VERSION ""

NS_ :

BS_:

BU_: SOBDMB_AWDC BCMC_CPDB BECMB_EPM PACM GWM _delete BCM ACCM DCDC_HEV GENERIC TSTR

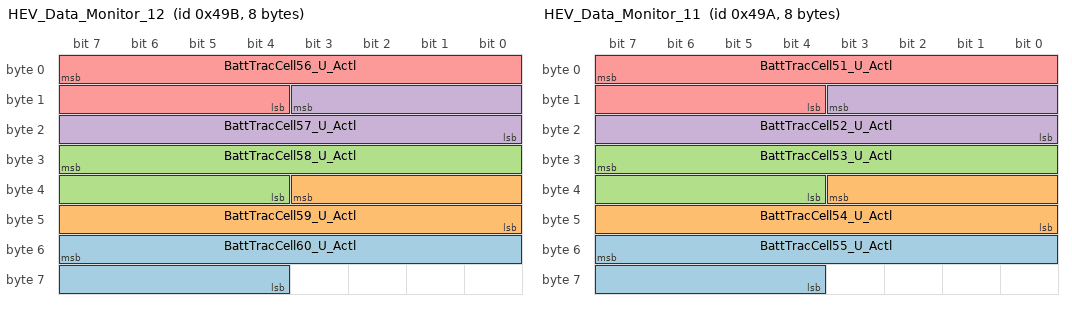
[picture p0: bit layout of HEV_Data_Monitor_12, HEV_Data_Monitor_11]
BO_ 1179 HEV_Data_Monitor_12: 8 GWM
 SG_ BattTracCell60_U_Actl : 55|12@0+ (0.001,1) [1|5.093] "volt" Vector__XXX
 SG_ BattTracCell59_U_Actl : 35|12@0+ (0.001,1) [1|5.093] "volt" Vector__XXX
 SG_ BattTracCell58_U_Actl : 31|12@0+ (0.001,1) [1|5.093] "volt" Vector__XXX
 SG_ BattTracCell57_U_Actl : 11|12@0+ (0.001,1) [1|5.093] "volt" Vector__XXX
 SG_ BattTracCell56_U_Actl : 7|12@0+ (0.001,1) [1|5.093] "volt" Vector__XXX

BO_ 1178 HEV_Data_Monitor_11: 8 GWM
 SG_ BattTracCell55_U_Actl : 55|12@0+ (0.001,1) [1|5.093] "volt" Vector__XXX
 SG_ BattTracCell54_U_Actl : 35|12@0+ (0.001,1) [1|5.093] "volt" Vector__XXX
 SG_ BattTracCell53_U_Actl : 31|12@0+ (0.001,1) [1|5.093] "volt" Vector__XXX
 SG_ BattTracCell52_U_Actl : 11|12@0+ (0.001,1) [1|5.093] "volt" Vector__XXX
 SG_ BattTracCell51_U_Actl : 7|12@0+ (0.001,1) [1|5.093] "volt" Vector__XXX

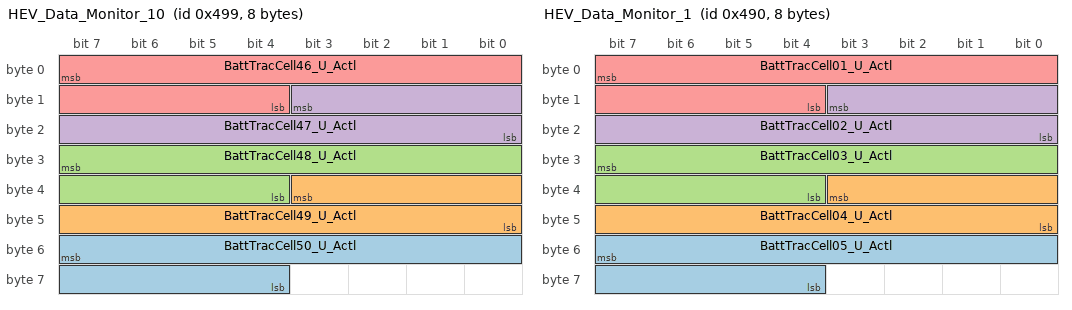
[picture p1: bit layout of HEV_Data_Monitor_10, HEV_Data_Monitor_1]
BO_ 1177 HEV_Data_Monitor_10: 8 GWM
 SG_ BattTracCell50_U_Actl : 55|12@0+ (0.001,1) [1|5.093] "volt" Vector__XXX
 SG_ BattTracCell49_U_Actl : 35|12@0+ (0.001,1) [1|5.093] "volt" Vector__XXX
 SG_ BattTracCell48_U_Actl : 31|12@0+ (0.001,1) [1|5.093] "volt" Vector__XXX
 SG_ BattTracCell47_U_Actl : 11|12@0+ (0.001,1) [1|5.093] "volt" Vector__XXX
 SG_ BattTracCell46_U_Actl : 7|12@0+ (0.001,1) [1|5.093] "volt" Vector__XXX

BO_ 1168 HEV_Data_Monitor_1: 8 GWM
 SG_ BattTracCell05_U_Actl : 55|12@0+ (0.001,1) [1|5.093] "volt" Vector__XXX
 SG_ BattTracCell04_U_Actl : 35|12@0+ (0.001,1) [1|5.093] "volt" Vector__XXX
 SG_ BattTracCell03_U_Actl : 31|12@0+ (0.001,1) [1|5.093] "volt" Vector__XXX
 SG_ BattTracCell02_U_Actl : 11|12@0+ (0.001,1) [1|5.093] "volt" Vector__XXX
 SG_ BattTracCell01_U_Actl : 7|12@0+ (0.001,1) [1|5.093] "volt" Vector__XXX

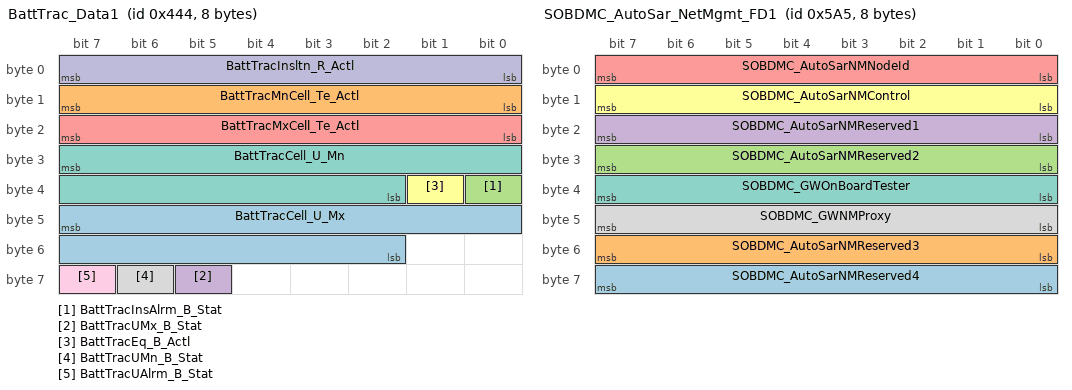
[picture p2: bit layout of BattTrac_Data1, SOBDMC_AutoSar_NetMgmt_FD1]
BO_ 1092 BattTrac_Data1: 8 GWM
 SG_ BattTracCell_U_Mx : 47|14@0+ (0.001,0) [0|16.382] "volt" Vector__XXX
 SG_ BattTracMnCell_Te_Actl : 15|8@0+ (1,-40) [-40|213] "degC" Vector__XXX
 SG_ BattTracInsAlrm_B_Stat : 32|1@0+ (1,0) [0|1] "SED" Vector__XXX
 SG_ BattTracUMx_B_Stat : 61|1@0+ (1,0) [0|1] "SED" Vector__XXX
 SG_ BattTracMxCell_Te_Actl : 23|8@0+ (1,-40) [-40|213] "degC" Vector__XXX
 SG_ BattTracEq_B_Actl : 33|1@0+ (1,0) [0|1] "SED" Vector__XXX
 SG_ BattTracCell_U_Mn : 31|14@0+ (0.001,0) [0|16.382] "volt" Vector__XXX
 SG_ BattTracUMn_B_Stat : 62|1@0+ (1,0) [0|1] "SED" Vector__XXX
 SG_ BattTracUAlrm_B_Stat : 63|1@0+ (1,0) [0|1] "SED" Vector__XXX
 SG_ BattTracInsltn_R_Actl : 7|8@0+ (6000,0) [0|1524000] "ohm" Vector__XXX

BO_ 1445 SOBDMC_AutoSar_NetMgmt_FD1: 8 GWM
 SG_ SOBDMC_AutoSarNMReserved4 : 63|8@0+ (1,0) [0|255] "unitless"  BCM
 SG_ SOBDMC_AutoSarNMReserved3 : 55|8@0+ (1,0) [0|255] "unitless"  BCM
 SG_ SOBDMC_AutoSarNMReserved2 : 31|8@0+ (1,0) [0|255] "unitless"  BCM
 SG_ SOBDMC_AutoSarNMReserved1 : 23|8@0+ (1,0) [0|255] "unitless"  BCM
 SG_ SOBDMC_AutoSarNMNodeId : 7|8@0+ (1,0) [0|255] "unitless"  BCM
 SG_ SOBDMC_AutoSarNMControl : 15|8@0+ (1,0) [0|255] "unitless"  BCM
 SG_ SOBDMC_GWOnBoardTester : 39|8@0+ (1,0) [0|255] "unitless"  BCM
 SG_ SOBDMC_GWNMProxy : 47|8@0+ (1,0) [0|255] "unitless"  BCM

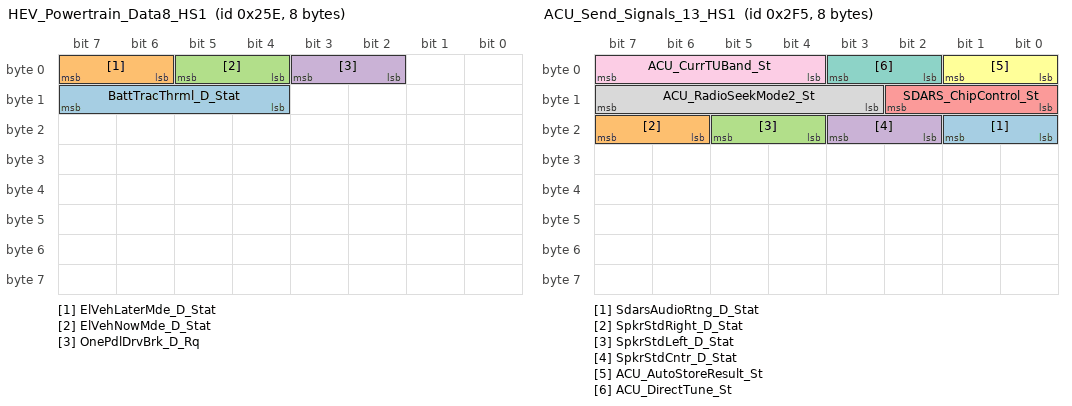
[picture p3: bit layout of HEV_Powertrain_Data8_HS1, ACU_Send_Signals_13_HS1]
BO_ 606 HEV_Powertrain_Data8_HS1: 8 GWM
 SG_ BattTracThrml_D_Stat : 15|4@0+ (1,0) [0|15] "SED"  GENERIC
 SG_ ElVehLaterMde_D_Stat : 7|2@0+ (1,0) [0|3] "SED"  GENERIC
 SG_ ElVehNowMde_D_Stat : 5|2@0+ (1,0) [0|3] "SED"  SOBDMB_AWDC
 SG_ OnePdlDrvBrk_D_Rq : 3|2@0+ (1,0) [0|3] "SED"  GENERIC

BO_ 942 ParkAid_Data_3_HS1: 8 GWM
 SG_ ApaOffOptnSel_B_Avail : 51|1@0+ (1,0) [0|1] "SED"  GENERIC
 SG_ PrkBrkElRleas_B_RqApa : 50|1@0+ (1,0) [0|1] "SED"  GENERIC
 SG_ ApaDrvRq2MsgTxt_D_Rq : 55|4@0+ (1,0) [0|15] "SED"  GENERIC
 SG_ ApaDrvRq1MsgTxt_D_Rq : 42|3@0+ (1,0) [0|7] "SED"  BCM
 SG_ ApaSys_D2_Stat : 35|4@0+ (1,0) [0|15] "SED"  GENERIC
 SG_ ApaSlotTrgt_D_Stat : 39|4@0+ (1,0) [0|15] "SED"  GENERIC
 SG_ ApaSlotOption_B_Avail : 43|1@0+ (1,0) [0|1] "SED"  GENERIC
 SG_ ApaSlotAlrtSet_B_Stat : 44|1@0+ (1,0) [0|1] "SED"  GENERIC
 SG_ ApaSlotAlrt_B_Rq : 45|1@0+ (1,0) [0|1] "SED"  GENERIC
 SG_ ApaRmtFeatSel_B_Avail : 46|1@0+ (1,0) [0|1] "SED"  GENERIC
 SG_ ApaParkOutSel_B_Avail : 47|1@0+ (1,0) [0|1] "SED"  GENERIC
 SG_ ApaParkInSel_B_Avail : 24|1@0+ (1,0) [0|1] "SED"  GENERIC
 SG_ ApaMsgTxt_D2_Stat : 28|4@0+ (1,0) [0|15] "SED"  GENERIC
 SG_ ApaDynmcSlot_B_Stat : 29|1@0+ (1,0) [0|1] "SED"  GENERIC
 SG_ ApaDisplayMode_D_Stat : 31|2@0+ (1,0) [0|3] "SED"  GENERIC
 SG_ ApaControlMode_D_Stat : 16|1@0+ (1,0) [0|1] "SED"  GENERIC
 SG_ PrkAidAcsyRear_D_Stat : 18|2@0+ (1,0) [0|3] "SED"  GENERIC
 SG_ PrkAidAcsyFront_D_Stat : 20|2@0+ (1,0) [0|3] "SED"  GENERIC
 SG_ PrkAidRdiusRight_L_Dsply : 15|8@0+ (1,0) [0|255] "unitless"  GENERIC
 SG_ PrkAidRdiusLeft_L_Dsply : 7|8@0+ (1,0) [0|255] "unitless"  GENERIC
 SG_ PrkAidDrvDir_D_Stat : 23|3@0+ (1,0) [0|7] "SED"  GENERIC

BO_ 757 ACU_Send_Signals_13_HS1: 8 GWM
 SG_ SdarsAudioRtng_D_Stat : 17|2@0+ (1,0) [0|3] "SED"  GENERIC
 SG_ SpkrStdRight_D_Stat : 23|2@0+ (1,0) [0|3] "SED"  GENERIC
 SG_ SpkrStdLeft_D_Stat : 21|2@0+ (1,0) [0|3] "SED"  GENERIC
 SG_ SpkrStdCntr_D_Stat : 19|2@0+ (1,0) [0|3] "SED"  GENERIC
 SG_ SDARS_ChipControl_St : 10|3@0+ (1,0) [0|7] "SED"  GENERIC
 SG_ ACU_AutoStoreResult_St : 1|2@0+ (1,0) [0|3] "SED"  GENERIC
 SG_ ACU_DirectTune_St : 3|2@0+ (1,0) [0|3] "SED"  GENERIC
 SG_ ACU_RadioSeekMode2_St : 15|5@0+ (1,0) [0|31] "SED"  GENERIC
 SG_ ACU_CurrTUBand_St : 7|4@0+ (1,0) [0|15] "SED" Vector__XXX

BO_ 646 Battery_Traction_13: 8 GWM
 SG_ BattTrac3_Pw_LimDchrg : 55|16@0+ (50,0) [0|3276750] "watts" Vector__XXX
 SG_ BattTrac3_Pw_LimChrg : 39|16@0+ (50,0) [0|3276750] "watts" Vector__XXX
 SG_ BattTrac3_Pw_DchrgInst : 23|16@0+ (50,0) [0|3276750] "watts" Vector__XXX
 SG_ BattTrac3_Pw_ChrgInst : 7|16@0+ (50,0) [0|3276750] "watts" Vector__XXX

BO_ 1229 IPMA_Data6_HS1: 8 GWM
 SG_ ExitNotClrRight_B_Stat : 6|1@0+ (1,0) [0|1] "SED"  BCM
 SG_ ExitNotClrLeft_B_Stat : 7|1@0+ (1,0) [0|1] "SED"  BCM

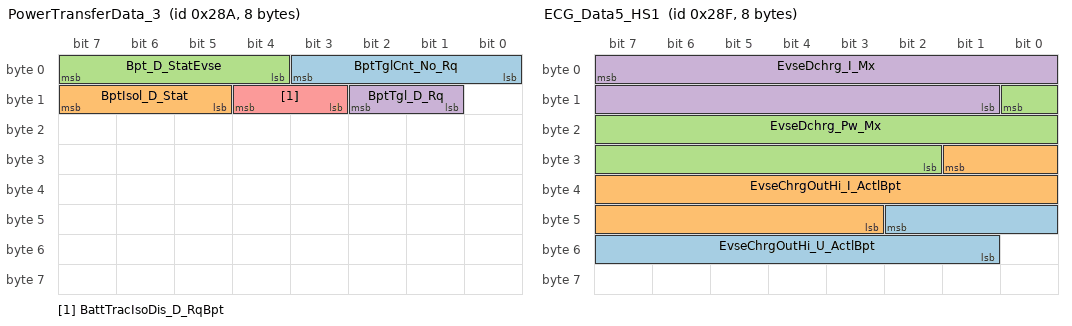
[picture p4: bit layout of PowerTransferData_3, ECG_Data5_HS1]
BO_ 650 PowerTransferData_3: 8 GWM
 SG_ BptTglCnt_No_Rq : 3|4@0+ (1,0) [0|13] "unitless" Vector__XXX
 SG_ BptIsol_D_Stat : 15|3@0+ (1,0) [0|7] "SED" Vector__XXX
 SG_ Bpt_D_StatEvse : 7|4@0+ (1,0) [0|15] "SED" Vector__XXX
 SG_ BptTgl_D_Rq : 10|2@0+ (1,0) [0|3] "SED" Vector__XXX
 SG_ BattTracIsoDis_D_RqBpt : 12|2@0+ (1,0) [0|3] "SED" Vector__XXX

BO_ 655 ECG_Data5_HS1: 8 GWM
 SG_ EvseChrgOutHi_U_ActlBpt : 42|10@0+ (0.5,0) [0|510.5] "volt" Vector__XXX
 SG_ EvseChrgOutHi_I_ActlBpt : 25|15@0+ (0.05,-750) [-750|888.25] "ampere" Vector__XXX
 SG_ EvseDchrg_Pw_Mx : 8|15@0+ (50,0) [0|1638250] "wattS" Vector__XXX
 SG_ EvseDchrg_I_Mx : 7|15@0+ (0.05,0) [0|1638.25] "ampere" Vector__XXX

BO_ 599 Battery_Traction_12: 8 GWM
 SG_ Bpt_D_StatBattTrac : 7|3@0+ (1,0) [0|7] "SED" Vector__XXX

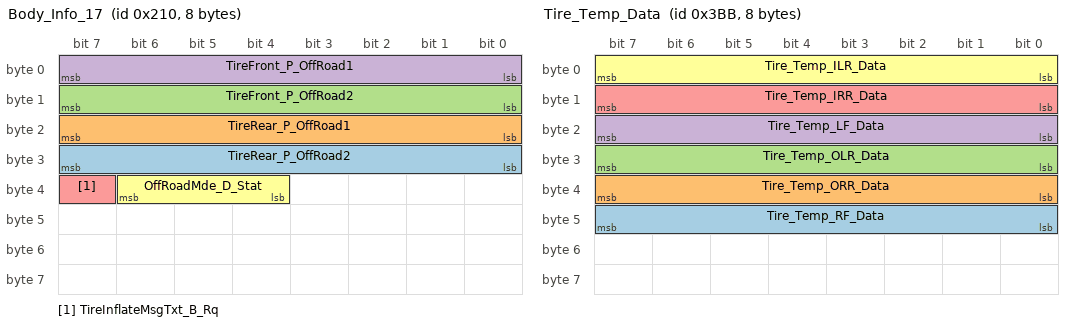
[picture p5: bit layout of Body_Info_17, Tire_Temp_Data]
BO_ 528 Body_Info_17: 8 BCM
 SG_ TireRear_P_OffRoad2 : 31|8@0+ (1,0) [0|255] "pounds/inch^2"  GWM
 SG_ TireRear_P_OffRoad1 : 23|8@0+ (1,0) [0|255] "pounds/inch^2"  GWM
 SG_ TireFront_P_OffRoad2 : 15|8@0+ (1,0) [0|255] "pounds/inch^2"  GWM
 SG_ TireFront_P_OffRoad1 : 7|8@0+ (1,0) [0|255] "pounds/inch^2"  GWM
 SG_ TireInflateMsgTxt_B_Rq : 39|1@0+ (1,0) [0|1] "SED"  GWM
 SG_ OffRoadMde_D_Stat : 38|3@0+ (1,0) [0|7] "SED"  GWM

BO_ 955 Tire_Temp_Data: 8 BCM
 SG_ Tire_Temp_RF_Data : 47|8@0+ (1,-60) [-60|193] "degC"  GWM
 SG_ Tire_Temp_ORR_Data : 39|8@0+ (1,-60) [-60|193] "degC"  GWM
 SG_ Tire_Temp_OLR_Data : 31|8@0+ (1,-60) [-60|193] "degC"  GWM
 SG_ Tire_Temp_LF_Data : 23|8@0+ (1,-60) [-60|193] "degC"  GWM
 SG_ Tire_Temp_IRR_Data : 15|8@0+ (1,-60) [-60|193] "degC"  GWM
 SG_ Tire_Temp_ILR_Data : 7|8@0+ (1,-60) [-60|193] "degC"  GWM

BO_ 749 BatteryCharge_Data3: 8 GWM
 SG_ ChrgrSysFalt18_D_Stat : 37|2@0+ (1,0) [0|3] "SED" Vector__XXX
 SG_ ChrgrSysFalt17_D_Stat : 39|2@0+ (1,0) [0|3] "SED" Vector__XXX
 SG_ ChrgrSysFalt16_D_Stat : 25|2@0+ (1,0) [0|3] "SED" Vector__XXX
 SG_ ChrgrSysFalt15_D_Stat : 27|2@0+ (1,0) [0|3] "SED" Vector__XXX
 SG_ ChrgrSysFalt14_D_Stat : 29|2@0+ (1,0) [0|3] "SED" Vector__XXX
 SG_ ChrgrSysFalt13_D_Stat : 31|2@0+ (1,0) [0|3] "SED" Vector__XXX
 SG_ ChrgrSysFalt12_D_Stat : 17|2@0+ (1,0) [0|3] "SED" Vector__XXX
 SG_ ChrgrSysFalt11_D_Stat : 19|2@0+ (1,0) [0|3] "SED" Vector__XXX
 SG_ ChrgrSysFalt9_D_Stat : 23|2@0+ (1,0) [0|3] "SED" Vector__XXX
 SG_ ChrgrSysFalt8_D_Stat : 9|2@0+ (1,0) [0|3] "SED" Vector__XXX
 SG_ ChrgrSysFalt7_D_Stat : 11|2@0+ (1,0) [0|3] "SED" Vector__XXX
 SG_ ChrgrSysFalt6_D_Stat : 13|2@0+ (1,0) [0|3] "SED" Vector__XXX
 SG_ ChrgrSysFalt5_D_Stat : 15|2@0+ (1,0) [0|3] "SED" Vector__XXX
 SG_ ChrgrSysFalt4_D_Stat : 1|2@0+ (1,0) [0|3] "SED" Vector__XXX
 SG_ ChrgrSysFalt3_D_Stat : 3|2@0+ (1,0) [0|3] "SED" Vector__XXX
 SG_ ChrgrSysFalt2_D_Stat : 5|2@0+ (1,0) [0|3] "SED" Vector__XXX
 SG_ ChrgrSysFalt1_D_Stat : 7|2@0+ (1,0) [0|3] "SED" Vector__XXX
 SG_ ChrgrSysFalt10_D_Stat : 21|2@0+ (1,0) [0|3] "SED" Vector__XXX

BO_ 624 PaakCtlData6_HS1: 8 GWM
 SG_ PaakAddEraseIndx_No_Rq : 5|6@0+ (1,0) [0|63] "unitless"  BCM
 SG_ PaakAddErase_D_Rq : 7|2@0+ (1,0) [0|3] "SED"  BCM

BO_ 580 Battery_Traction_11: 8 GWM
 SG_ BattTracVrtOck_B_Rq : 7|1@0+ (1,0) [0|1] "SED" Vector__XXX

BO_ 622 Body_Info_12: 8 BCM
 SG_ FobCtlType_D_Stat : 43|2@0+ (1,0) [0|3] "SED"  GWM
 SG_ FobCtlRollCode_No_Stat : 47|4@0+ (1,0) [0|15] "unitless"  GWM
 SG_ FobCtlPssvData_No_Actl : 7|40@0+ (1,0) [0|1099511627775] "Encrypted"  GWM

BO_ 1050 GatewayData8_HS1: 8 GWM
 SG_ ActvDrvMde_D2_Stat_UB : 2|1@0+ (1,0) [0|1] "SED"  BCM
 SG_ ActvDrvMde_D2_Stat : 7|5@0+ (1,0) [0|31] "SED"  BCM
 SG_ PtWakeupActv4_B_Rq_UB : 25|1@0+ (1,0) [0|1] "SED"  BCM
 SG_ PtWakeupActv4_B_Rq : 26|1@0+ (1,0) [0|1] "SED"  BCM
 SG_ ModemReset_D_Rq_UB : 24|1@0+ (1,0) [0|1] "SED" Vector__XXX
 SG_ ModemReset_D_Rq : 39|4@0+ (1,0) [0|15] "SED" Vector__XXX
 SG_ SelDrvMdeAwd_D_Rq_UB : 11|1@0+ (1,0) [0|1] "SED"  GENERIC
 SG_ SelDrvMdeAwd_D_Rq : 23|5@0+ (1,0) [0|31] "SED"  GENERIC
 SG_ DrLckCnt_No_ActlTgate_UB : 10|1@0+ (1,0) [0|1] "SED"  BCM
 SG_ DrLckCnt_No_ActlTgate : 31|4@0+ (1,0) [0|15] "unitless"  BCM
 SG_ TelematicsSrvc_D_St_UB : 12|1@0+ (1,0) [0|1] "SED" Vector__XXX
 SG_ TelematicsSrvc_D_St : 15|3@0+ (1,0) [0|7] "SED" Vector__XXX
 SG_ FactoryReset_Rq_UB : 0|1@0+ (1,0) [0|1] "SED" Vector__XXX
 SG_ FactoryReset_Rq : 1|1@0+ (1,0) [0|1] "SED" Vector__XXX
 SG_ TurnLampFrOut_B_Stat_UB : 27|1@0+ (1,0) [0|1] "SED"  BCM
 SG_ TurnLampFlOut_B_Stat_UB : 16|1@0+ (1,0) [0|1] "SED"  BCM
 SG_ TurnLampFrOut_B_Stat : 8|1@0+ (1,0) [0|1] "SED"  BCM
 SG_ TurnLampFlOut_B_Stat : 9|1@0+ (1,0) [0|1] "SED"  BCM
 SG_ TrunkFrontRolCd_No_Locl_UB : 18|1@0+ (1,0) [0|1] "SED"  BCM
 SG_ TrunkFrontRolCd_No_Locl : 47|16@0+ (1,0) [0|65535] "unitless"  BCM
 SG_ SelDrvMdeHmi03_D_Rq : 63|5@0+ (1,0) [0|31] "SED"  BCM
 SG_ SelDrvMdeHmi03_D_Rq_UB : 17|1@0+ (1,0) [0|1] "SED"  BCM

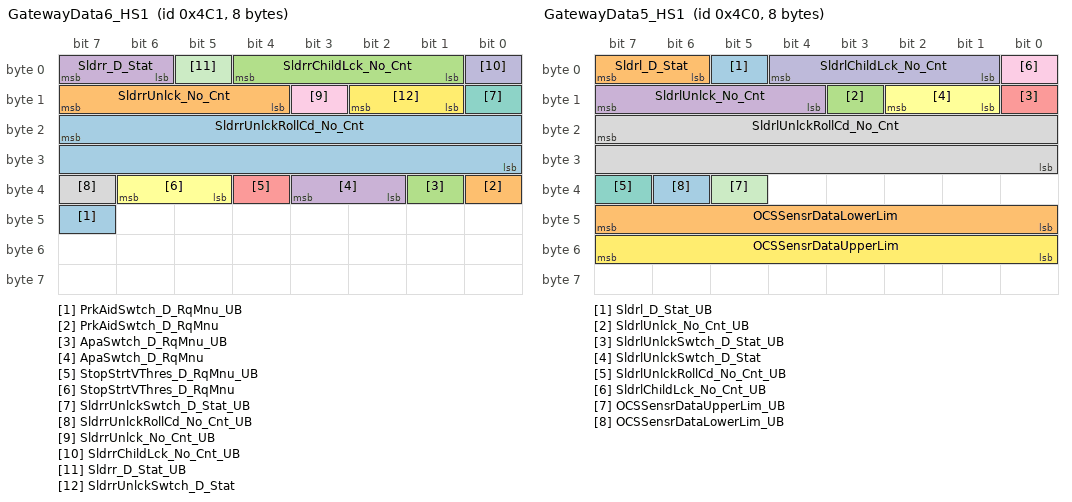
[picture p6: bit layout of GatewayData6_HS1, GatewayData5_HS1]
BO_ 1217 GatewayData6_HS1: 8 GWM
 SG_ PrkAidSwtch_D_RqMnu_UB : 47|1@0+ (1,0) [0|1] "SED"  GENERIC
 SG_ PrkAidSwtch_D_RqMnu : 32|1@0+ (1,0) [0|1] "SED"  GENERIC
 SG_ ApaSwtch_D_RqMnu_UB : 33|1@0+ (1,0) [0|1] "SED"  GENERIC
 SG_ ApaSwtch_D_RqMnu : 35|2@0+ (1,0) [0|3] "SED"  GENERIC
 SG_ StopStrtVThres_D_RqMnu_UB : 36|1@0+ (1,0) [0|1] "SED" Vector__XXX
 SG_ StopStrtVThres_D_RqMnu : 38|2@0+ (1,0) [0|3] "SED" Vector__XXX
 SG_ SldrrUnlckSwtch_D_Stat_UB : 8|1@0+ (1,0) [0|1] "SED" Vector__XXX
 SG_ SldrrUnlckRollCd_No_Cnt_UB : 39|1@0+ (1,0) [0|1] "SED" Vector__XXX
 SG_ SldrrUnlck_No_Cnt_UB : 11|1@0+ (1,0) [0|1] "SED" Vector__XXX
 SG_ SldrrChildLck_No_Cnt_UB : 0|1@0+ (1,0) [0|1] "SED" Vector__XXX
 SG_ Sldrr_D_Stat_UB : 5|1@0+ (1,0) [0|1] "SED" Vector__XXX
 SG_ SldrrUnlckSwtch_D_Stat : 10|2@0+ (1,0) [0|3] "SED" Vector__XXX
 SG_ SldrrUnlckRollCd_No_Cnt : 23|16@0+ (1,0) [0|65535] "unitless" Vector__XXX
 SG_ SldrrUnlck_No_Cnt : 15|4@0+ (1,0) [0|15] "unitless" Vector__XXX
 SG_ SldrrChildLck_No_Cnt : 4|4@0+ (1,0) [0|15] "unitless" Vector__XXX
 SG_ Sldrr_D_Stat : 7|2@0+ (1,0) [0|3] "SED" Vector__XXX

BO_ 1216 GatewayData5_HS1: 8 GWM
 SG_ Sldrl_D_Stat_UB : 5|1@0+ (1,0) [0|1] "SED" Vector__XXX
 SG_ Sldrl_D_Stat : 7|2@0+ (1,0) [0|3] "SED" Vector__XXX
 SG_ SldrlUnlck_No_Cnt_UB : 11|1@0+ (1,0) [0|1] "SED" Vector__XXX
 SG_ SldrlUnlck_No_Cnt : 15|4@0+ (1,0) [0|15] "unitless" Vector__XXX
 SG_ SldrlUnlckSwtch_D_Stat_UB : 8|1@0+ (1,0) [0|1] "SED" Vector__XXX
 SG_ SldrlUnlckSwtch_D_Stat : 10|2@0+ (1,0) [0|3] "SED" Vector__XXX
 SG_ SldrlUnlckRollCd_No_Cnt_UB : 39|1@0+ (1,0) [0|1] "SED" Vector__XXX
 SG_ SldrlUnlckRollCd_No_Cnt : 23|16@0+ (1,0) [0|65535] "unitless" Vector__XXX
 SG_ SldrlChildLck_No_Cnt_UB : 0|1@0+ (1,0) [0|1] "SED" Vector__XXX
 SG_ SldrlChildLck_No_Cnt : 4|4@0+ (1,0) [0|15] "unitless" Vector__XXX
 SG_ OCSSensrDataUpperLim_UB : 37|1@0+ (1,0) [0|1] "SED" Vector__XXX
 SG_ OCSSensrDataUpperLim : 55|8@0+ (1,0) [0|254] "SED" Vector__XXX
 SG_ OCSSensrDataLowerLim_UB : 38|1@0+ (1,0) [0|1] "SED" Vector__XXX
 SG_ OCSSensrDataLowerLim : 47|8@0+ (1,0) [0|254] "SED" Vector__XXX

BO_ 1087 Powertrain_Data_5_HS1: 8 GWM
 SG_ DcacFaltMsgTxt_D2_Rq : 39|6@0+ (1,0) [0|63] "SED" Vector__XXX
 SG_ SelDrvMdeCstmPt_D_Stat : 31|5@0+ (1,0) [0|31] "SED"  GENERIC
 SG_ RepaLcGrdInhbt_B_Stat : 17|1@0+ (1,0) [0|1] "SED"  GENERIC
 SG_ ClimtCool_D_RqPt : 19|2@0+ (1,0) [0|3] "SED"  GENERIC
 SG_ BtsiShifInhbt_B_RqPt : 8|1@0+ (1,0) [0|1] "SED" Vector__XXX
 SG_ StrtInGearMsgTxt_D_Rq : 23|4@0+ (1,0) [0|15] "SED"  GENERIC
 SG_ IgnOffInhbt_B_Stat : 9|1@0+ (1,0) [0|1] "SED" Vector__XXX
 SG_ StopStrtCstm_D_Stat : 26|2@0+ (1,0) [0|3] "SED"  GENERIC
 SG_ FapLcInhbt_B_Rq : 1|1@0+ (1,0) [0|1] "SED"  GENERIC
 SG_ FapLcStopHold_B_Rq : 2|1@0+ (1,0) [0|1] "SED"  GENERIC
 SG_ FapLcPrchgBrk_B_Rq : 3|1@0+ (1,0) [0|1] "SED"  GENERIC
 SG_ FapLcObstcl_B_Stat : 4|1@0+ (1,0) [0|1] "SED"  GENERIC
 SG_ FapLcMaxGrdInhbt_B_Stat : 5|1@0+ (1,0) [0|1] "SED"  GENERIC
 SG_ FapLcMaxGrdAbrt_B_Stat : 6|1@0+ (1,0) [0|1] "SED"  GENERIC
 SG_ FapLcActv_B_Stat : 7|1@0+ (1,0) [0|1] "SED" Vector__XXX
 SG_ BattRgenLoDChrg_D_RqEng : 13|2@0+ (1,0) [0|3] "SED" Vector__XXX
 SG_ BattRgenLoChrg_D_RqEng : 15|2@0+ (1,0) [0|3] "SED" Vector__XXX
 SG_ AdasLcObtclAbrt_B_Stat : 0|1@0+ (1,0) [0|1] "SED"  GENERIC
 SG_ AirDamPos_D_Stat : 11|2@0+ (1,0) [0|3] "SED"  GENERIC

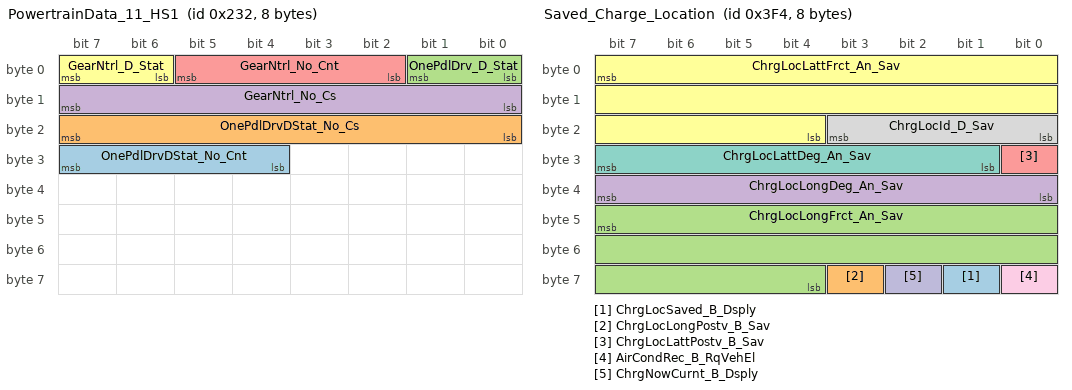
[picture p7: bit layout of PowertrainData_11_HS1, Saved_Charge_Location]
BO_ 562 PowertrainData_11_HS1: 8 GWM
 SG_ OnePdlDrvDStat_No_Cnt : 31|4@0+ (1,0) [0|15] "Unitless"  GENERIC
 SG_ OnePdlDrvDStat_No_Cs : 23|8@0+ (1,0) [0|255] "Unitless"  GENERIC
 SG_ OnePdlDrv_D_Stat : 1|2@0+ (1,0) [0|3] "SED"  GENERIC
 SG_ GearNtrl_No_Cs : 15|8@0+ (1,0) [0|255] "unitless" Vector__XXX
 SG_ GearNtrl_No_Cnt : 5|4@0+ (1,0) [0|15] "unitless" Vector__XXX
 SG_ GearNtrl_D_Stat : 7|2@0+ (1,0) [0|3] "SED" Vector__XXX

BO_ 533 APIM_Send_Signals_2_HS1: 8 GWM
 SG_ ClrExitAsstEnbl_D_RqMnu : 60|2@0+ (1,0) [0|3] "SED"  GENERIC
 SG_ PaakMyKey_D_Rq : 7|2@0+ (1,0) [0|3] "SED"  BCM
 SG_ AutoEpbZoomView_B_Stat : 32|1@0+ (1,0) [0|1] "SED"  GENERIC
 SG_ AutoEpbButtn_B_Stat : 19|1@0+ (1,0) [0|1] "SED"  GENERIC
 SG_ DcacPw_D_Rq : 62|2@0+ (1,0) [0|3] "SED"  GENERIC
 SG_ DcacPwReset_B_Rq : 63|1@0+ (1,0) [0|1] "SED"  GENERIC
 SG_ OtaTrg_D_Stat : 41|2@0+ (1,0) [0|3] "SED"  GENERIC
 SG_ DcacPwLoButtn_B_Stat : 13|1@0+ (1,0) [0|1] "SED"  GENERIC
 SG_ DcacPwOffButtn_B_Stat : 12|1@0+ (1,0) [0|1] "SED"  GENERIC
 SG_ DcacPwHiButtn_B_Stat : 14|1@0+ (1,0) [0|1] "SED"  GENERIC
 SG_ DcacPwResetButtn_B_Stat : 11|1@0+ (1,0) [0|1] "SED"  GENERIC
 SG_ DcacPwButtn_B_Falt : 15|1@0+ (1,0) [0|1] "SED"  GENERIC
 SG_ OnbChrgGoTTouch_D_Rq : 43|2@0+ (1,0) [0|3] "SED" Vector__XXX
 SG_ OnbChrgGoTPrcond_D_Rq : 34|2@0+ (1,0) [0|3] "SED" Vector__XXX
 SG_ OnbChrgGoTOn_D_Rq : 25|2@0+ (1,0) [0|3] "SED" Vector__XXX
 SG_ OnbChrgGoTMnte_D_Rq : 47|4@0+ (1,0) [0|15] "minute" Vector__XXX
 SG_ OnbChrgGoTHr_T_Rq : 39|5@0+ (1,0) [0|29] "hour" Vector__XXX
 SG_ OnbChrgGoTExtHtr_D_Rq : 27|2@0+ (1,0) [0|3] "SED" Vector__XXX
 SG_ OnbChrgGoTElement_D_Rq : 31|4@0+ (1,0) [0|15] "Unitless" Vector__XXX
 SG_ OnbChrgGoTDelete_B_Rq : 17|1@0+ (1,0) [0|1] "SED" Vector__XXX
 SG_ OnbChrgClearAll_B_Rq : 18|1@0+ (1,0) [0|1] "SED" Vector__XXX
 SG_ OnbChrgGoTUpdate_B_Rq : 16|1@0+ (1,0) [0|1] "SED" Vector__XXX
 SG_ TrlrAidMde_D_Rq : 5|2@0+ (1,0) [0|3] "SED"  GENERIC
 SG_ TCU_Init_Actvtn_St : 1|2@0+ (1,0) [0|3] "SED"  GENERIC
 SG_ TCU_Final_Actvtn_St : 3|2@0+ (1,0) [0|3] "SED"  GENERIC
 SG_ TrlrAlarmButtn_B_Stat : 50|1@0+ (1,0) [0|1] "SED"  GENERIC
 SG_ DcacMdeButtn_B_Stat : 8|1@0+ (1,0) [0|1] "SED"  GENERIC
 SG_ LghtAmbDrvMde_D_Rq : 49|2@0+ (1,0) [0|3] "SED"  BCM
 SG_ DcacGfciTestBttn_B_Stat : 9|1@0+ (1,0) [0|1] "SED"  GENERIC
 SG_ TrlrHitch_D_RqMnu : 23|4@0+ (1,0) [0|15] "SED"  GENERIC
 SG_ TrlrBrkGain_No_Rq : 55|5@0+ (0.5,0) [0|15.5] "unitless"  GENERIC
 SG_ DcacPwButtn_B_Stat : 10|1@0+ (1,0) [0|1] "SED"  GENERIC

BO_ 1012 Saved_Charge_Location: 8 GWM
 SG_ ChrgLocSaved_B_Dsply : 57|1@0+ (1,0) [0|1] "SED"  GENERIC
 SG_ ChrgLocLongPostv_B_Sav : 59|1@0+ (1,0) [0|1] "SED"  GENERIC
 SG_ ChrgLocLongFrct_An_Sav : 47|20@0+ (1E-006,0) [0|1.048575] "degrees"  GENERIC
 SG_ ChrgLocLongDeg_An_Sav : 39|8@0+ (1,0) [0|255] "degrees"  GENERIC
 SG_ ChrgLocLattPostv_B_Sav : 24|1@0+ (1,0) [0|1] "SED"  GENERIC
 SG_ ChrgLocLattFrct_An_Sav : 7|20@0+ (1E-006,0) [0|1.048575] "degrees"  GENERIC
 SG_ ChrgLocLattDeg_An_Sav : 31|7@0+ (1,0) [0|127] "unitless"  GENERIC
 SG_ ChrgLocId_D_Sav : 19|4@0+ (1,0) [0|15] "unitless"  GENERIC
 SG_ AirCondRec_B_RqVehEl : 56|1@0+ (1,0) [0|1] "SED"  GENERIC
 SG_ ChrgNowCurnt_B_Dsply : 58|1@0+ (1,0) [0|1] "SED" Vector__XXX

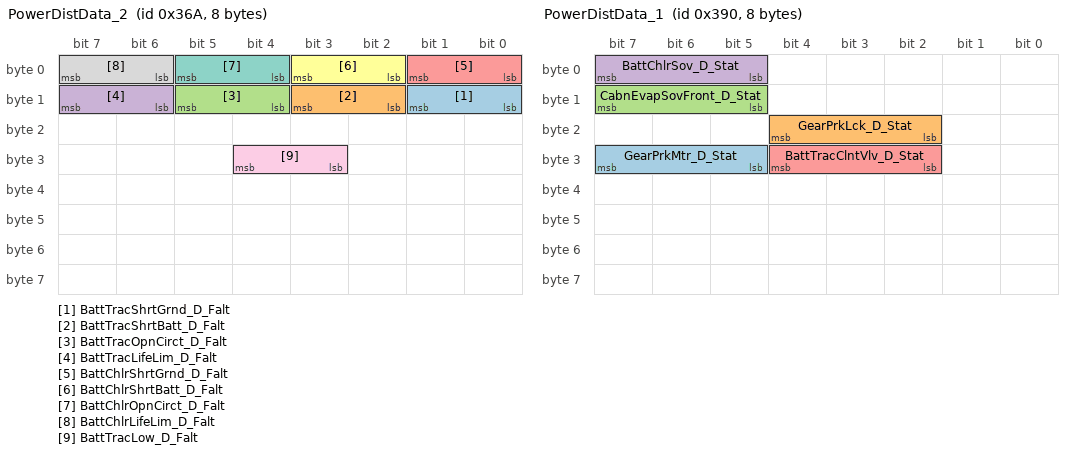
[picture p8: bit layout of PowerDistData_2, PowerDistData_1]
BO_ 874 PowerDistData_2: 8 BCMC_CPDB
 SG_ BattTracShrtGrnd_D_Falt : 9|2@0+ (1,0) [0|3] "SED"  GWM
 SG_ BattTracShrtBatt_D_Falt : 11|2@0+ (1,0) [0|3] "SED"  GWM
 SG_ BattTracOpnCirct_D_Falt : 13|2@0+ (1,0) [0|3] "SED"  GWM
 SG_ BattTracLifeLim_D_Falt : 15|2@0+ (1,0) [0|3] "SED"  GWM
 SG_ BattChlrShrtGrnd_D_Falt : 1|2@0+ (1,0) [0|3] "SED"  GWM
 SG_ BattChlrShrtBatt_D_Falt : 3|2@0+ (1,0) [0|3] "SED"  GWM
 SG_ BattChlrOpnCirct_D_Falt : 5|2@0+ (1,0) [0|3] "SED"  GWM
 SG_ BattChlrLifeLim_D_Falt : 7|2@0+ (1,0) [0|3] "SED"  GWM
 SG_ BattTracLow_D_Falt : 28|2@0+ (1,0) [0|3] "SED"  GWM

BO_ 912 PowerDistData_1: 8 BCMC_CPDB
 SG_ GearPrkMtr_D_Stat : 31|3@0+ (1,0) [0|7] "SED"  GWM
 SG_ GearPrkLck_D_Stat : 20|3@0+ (1,0) [0|7] "SED"  GWM
 SG_ CabnEvapSovFront_D_Stat : 15|3@0+ (1,0) [0|7] "SED"  GWM
 SG_ BattChlrSov_D_Stat : 7|3@0+ (1,0) [0|7] "SED"  GWM
 SG_ BattTracClntVlv_D_Stat : 28|3@0+ (1,0) [0|7] "SED"  GWM

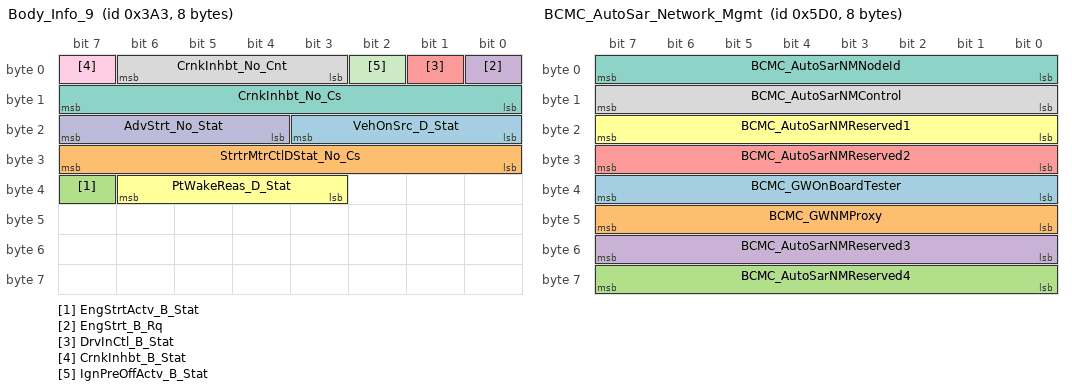
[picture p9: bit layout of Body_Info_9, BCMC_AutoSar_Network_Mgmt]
BO_ 931 Body_Info_9: 8 BCM
 SG_ VehOnSrc_D_Stat : 19|4@0+ (1,0) [0|15] "SED"  SOBDMB_AWDC,GWM
 SG_ StrtrMtrCtlDStat_No_Cs : 31|8@0+ (1,0) [0|255] "unitless"  SOBDMB_AWDC,GWM
 SG_ EngStrtActv_B_Stat : 39|1@0+ (1,0) [0|1] "SED"  SOBDMB_AWDC,GWM
 SG_ EngStrt_B_Rq : 0|1@0+ (1,0) [0|1] "SED"  SOBDMB_AWDC,GWM
 SG_ DrvInCtl_B_Stat : 1|1@0+ (1,0) [0|1] "SED"  SOBDMB_AWDC,GWM
 SG_ PtWakeReas_D_Stat : 38|4@0+ (1,0) [0|15] "SED"  GWM
 SG_ CrnkInhbt_No_Cs : 15|8@0+ (1,0) [0|255] "Unitless"  GWM
 SG_ CrnkInhbt_No_Cnt : 6|4@0+ (1,0) [0|15] "Unitless"  SOBDMB_AWDC,GWM
 SG_ CrnkInhbt_B_Stat : 7|1@0+ (1,0) [0|1] "SED"  SOBDMB_AWDC,GWM
 SG_ AdvStrt_No_Stat : 23|4@0+ (1,0) [0|15] "unitless"  SOBDMB_AWDC,GWM
 SG_ IgnPreOffActv_B_Stat : 2|1@0+ (1,0) [0|1] "SED"  GWM

BO_ 1488 BCMC_AutoSar_Network_Mgmt: 8 BCMC_CPDB
 SG_ BCMC_GWOnBoardTester : 39|8@0+ (1,0) [0|255] "unitless"  GWM
 SG_ BCMC_GWNMProxy : 47|8@0+ (1,0) [0|255] "unitless"  GWM
 SG_ BCMC_AutoSarNMReserved4 : 63|8@0+ (1,0) [0|255] "unitless"  GWM
 SG_ BCMC_AutoSarNMReserved3 : 55|8@0+ (1,0) [0|255] "unitless"  GWM
 SG_ BCMC_AutoSarNMReserved2 : 31|8@0+ (1,0) [0|255] "unitless"  GWM
 SG_ BCMC_AutoSarNMReserved1 : 23|8@0+ (1,0) [0|255] "unitless"  GWM
 SG_ BCMC_AutoSarNMNodeId : 7|8@0+ (1,0) [0|255] "unitless"  GWM
 SG_ BCMC_AutoSarNMControl : 15|8@0+ (1,0) [0|255] "unitless"  GWM

BO_ 1776 TesterPhysicalReqBCMC_CPDB: 8 TSTR
 SG_ TesterPhysicalReqBCMC_CPDB : 7|64@0+ (1,0) [0|1.84467E+019] "unitless"  BCMC_CPDB

BO_ 1784 TesterPhysicalResBCMC_CPDB: 8 BCMC_CPDB
 SG_ TesterPhysicalResBCMC_CPDB : 7|64@0+ (1,0) [0|1.84467E+019] "unitless"  TSTR

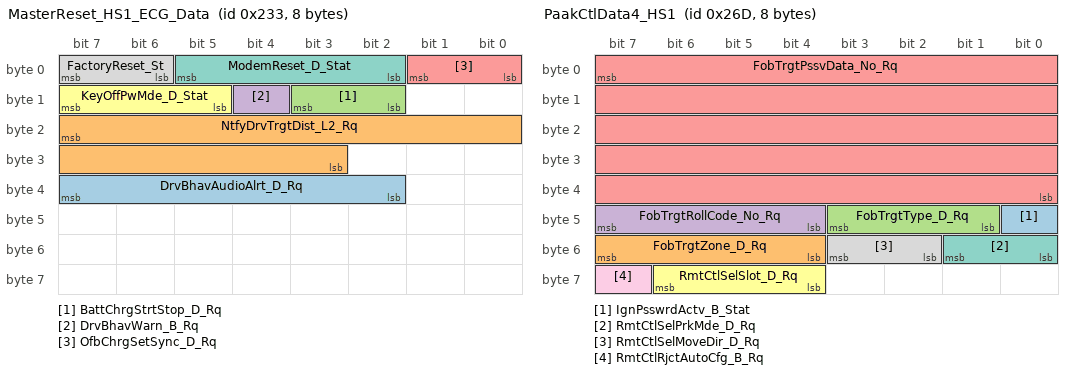
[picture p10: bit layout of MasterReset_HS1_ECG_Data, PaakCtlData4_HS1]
BO_ 563 MasterReset_HS1_ECG_Data: 8 GWM
 SG_ DrvBhavAudioAlrt_D_Rq : 39|6@0+ (1,0) [0|63] "SED"  GENERIC
 SG_ NtfyDrvTrgtDist_L2_Rq : 23|13@0+ (0.1,0) [0|818.9] "Km"  GENERIC
 SG_ BattChrgStrtStop_D_Rq : 11|2@0+ (1,0) [0|3] "SED"  GENERIC
 SG_ DrvBhavWarn_B_Rq : 12|1@0+ (1,0) [0|1] "SED"  GENERIC
 SG_ OfbChrgSetSync_D_Rq : 1|2@0+ (1,0) [0|3] "SED"  GENERIC
 SG_ KeyOffPwMde_D_Stat : 15|3@0+ (1,0) [0|7] "SED"  GENERIC
 SG_ ModemReset_D_Stat : 5|4@0+ (1,0) [0|15] "SED"  GENERIC
 SG_ FactoryReset_St : 7|2@0+ (1,0) [0|3] "SED"  GENERIC

BO_ 621 PaakCtlData4_HS1: 8 GWM
 SG_ IgnPsswrdActv_B_Stat : 40|1@0+ (1,0) [0|1] "SED"  BCM
 SG_ FobTrgtZone_D_Rq : 55|4@0+ (1,0) [0|15] "SED"  BCM
 SG_ FobTrgtType_D_Rq : 43|3@0+ (1,0) [0|7] "SED"  BCM
 SG_ FobTrgtRollCode_No_Rq : 47|4@0+ (1,0) [0|15] "unitless"  BCM
 SG_ FobTrgtPssvData_No_Rq : 7|40@0+ (1,0) [0|1099511627775] "Encrypted"  BCM
 SG_ RmtCtlSelSlot_D_Rq : 62|3@0+ (1,0) [0|7] "SED"  GENERIC
 SG_ RmtCtlSelPrkMde_D_Rq : 49|2@0+ (1,0) [0|3] "SED"  GENERIC
 SG_ RmtCtlSelMoveDir_D_Rq : 51|2@0+ (1,0) [0|3] "SED"  GENERIC
 SG_ RmtCtlRjctAutoCfg_B_Rq : 63|1@0+ (1,0) [0|1] "SED"  GENERIC

BO_ 1149 Battery_Traction_10: 8 GWM
 SG_ BattTracPerf_Pc_Dsply : 15|8@0+ (1,0) [0|253] "percent" Vector__XXX
 SG_ BattTracPerf_Pc_Actl : 7|8@0+ (1,0) [0|253] "percent" Vector__XXX

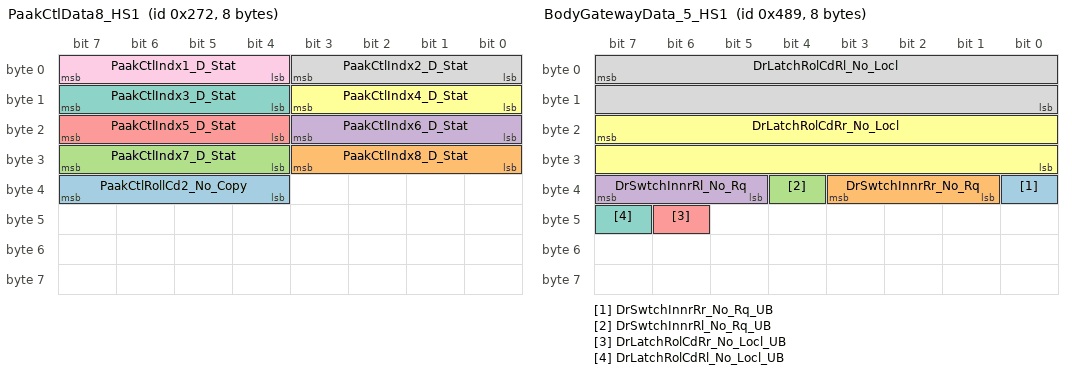
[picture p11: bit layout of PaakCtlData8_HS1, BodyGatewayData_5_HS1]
BO_ 626 PaakCtlData8_HS1: 8 GWM
 SG_ PaakCtlRollCd2_No_Copy : 39|4@0+ (1,0) [0|15] "unitless"  BCM
 SG_ PaakCtlIndx8_D_Stat : 27|4@0+ (1,0) [0|15] "SED"  BCM
 SG_ PaakCtlIndx7_D_Stat : 31|4@0+ (1,0) [0|15] "SED"  BCM
 SG_ PaakCtlIndx6_D_Stat : 19|4@0+ (1,0) [0|15] "SED"  BCM
 SG_ PaakCtlIndx5_D_Stat : 23|4@0+ (1,0) [0|15] "SED"  BCM
 SG_ PaakCtlIndx4_D_Stat : 11|4@0+ (1,0) [0|15] "SED"  BCM
 SG_ PaakCtlIndx3_D_Stat : 15|4@0+ (1,0) [0|15] "SED"  BCM
 SG_ PaakCtlIndx2_D_Stat : 3|4@0+ (1,0) [0|15] "SED"  BCM
 SG_ PaakCtlIndx1_D_Stat : 7|4@0+ (1,0) [0|15] "SED"  BCM

BO_ 1135 Battery_Traction_9: 8 GWM
 SG_ BattChrg_I2_Rq : 23|16@0+ (0.1,0) [0|6553.5] "ampere" Vector__XXX
 SG_ BattChrg_I2_Mx : 7|16@0+ (0.1,0) [0|6553.5] "ampere" Vector__XXX

BO_ 1161 BodyGatewayData_5_HS1: 8 GWM
 SG_ DrSwtchInnrRr_No_Rq_UB : 32|1@0+ (1,0) [0|1] "SED"  BCM
 SG_ DrSwtchInnrRr_No_Rq : 35|3@0+ (1,0) [0|7] "unitless"  BCM
 SG_ DrSwtchInnrRl_No_Rq_UB : 36|1@0+ (1,0) [0|1] "SED"  BCM
 SG_ DrSwtchInnrRl_No_Rq : 39|3@0+ (1,0) [0|7] "unitless"  BCM
 SG_ DrLatchRolCdRr_No_Locl_UB : 46|1@0+ (1,0) [0|1] "SED"  BCM
 SG_ DrLatchRolCdRr_No_Locl : 23|16@0+ (1,0) [0|65535] "unitless"  BCM
 SG_ DrLatchRolCdRl_No_Locl_UB : 47|1@0+ (1,0) [0|1] "SED"  BCM
 SG_ DrLatchRolCdRl_No_Locl : 7|16@0+ (1,0) [0|65535] "unitless"  BCM

BO_ 960 DrLatchRolCdData: 8 BCM
 SG_ DrLatchRolCdRr_No_Actl : 55|16@0+ (1,0) [0|65535] "unitless"  GWM
 SG_ DrLatchRolCdRl_No_Actl : 39|16@0+ (1,0) [0|65535] "unitless"  GWM
 SG_ DrLatchRolCdFr_No_Actl : 23|16@0+ (1,0) [0|65535] "unitless"  GWM
 SG_ DrLatchRolCdFl_No_Actl : 7|16@0+ (1,0) [0|65535] "unitless"  GWM

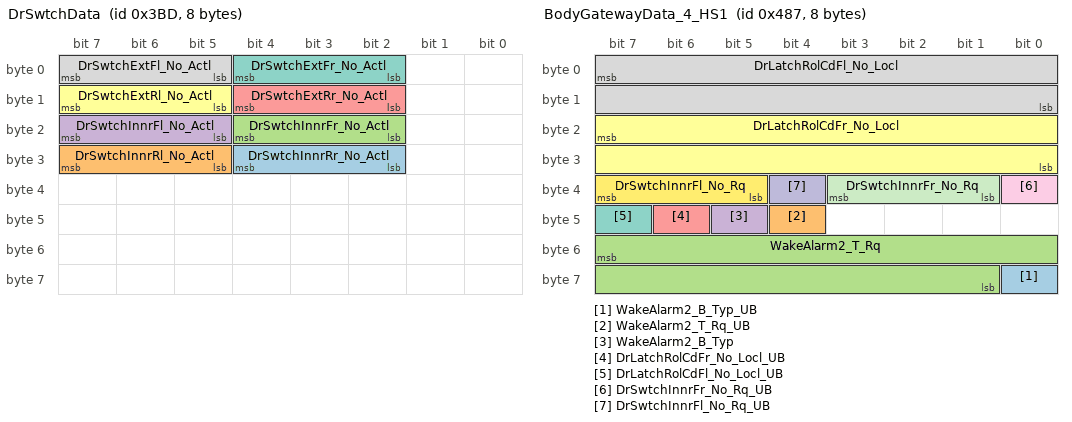
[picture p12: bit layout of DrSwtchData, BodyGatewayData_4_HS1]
BO_ 957 DrSwtchData: 8 BCM
 SG_ DrSwtchInnrRr_No_Actl : 28|3@0+ (1,0) [0|7] "unitless"  GWM
 SG_ DrSwtchInnrRl_No_Actl : 31|3@0+ (1,0) [0|7] "unitless"  GWM
 SG_ DrSwtchInnrFr_No_Actl : 20|3@0+ (1,0) [0|7] "unitless"  GWM
 SG_ DrSwtchInnrFl_No_Actl : 23|3@0+ (1,0) [0|7] "unitless"  GWM
 SG_ DrSwtchExtRr_No_Actl : 12|3@0+ (1,0) [0|7] "unitless"  GWM
 SG_ DrSwtchExtRl_No_Actl : 15|3@0+ (1,0) [0|7] "unitless"  GWM
 SG_ DrSwtchExtFr_No_Actl : 4|3@0+ (1,0) [0|7] "unitless"  GWM
 SG_ DrSwtchExtFl_No_Actl : 7|3@0+ (1,0) [0|7] "unitless"  GWM

BO_ 1159 BodyGatewayData_4_HS1: 8 GWM
 SG_ WakeAlarm2_B_Typ_UB : 56|1@0+ (1,0) [0|1] "SED"  BCM
 SG_ WakeAlarm2_T_Rq_UB : 44|1@0+ (1,0) [0|1] "SED"  BCM
 SG_ WakeAlarm2_T_Rq : 55|15@0+ (1,0) [0|32767] "minute"  BCM
 SG_ WakeAlarm2_B_Typ : 45|1@0+ (1,0) [0|1] "SED"  BCM
 SG_ DrLatchRolCdFr_No_Locl_UB : 46|1@0+ (1,0) [0|1] "SED"  BCM
 SG_ DrLatchRolCdFr_No_Locl : 23|16@0+ (1,0) [0|65535] "unitless"  BCM
 SG_ DrLatchRolCdFl_No_Locl_UB : 47|1@0+ (1,0) [0|1] "SED"  BCM
 SG_ DrLatchRolCdFl_No_Locl : 7|16@0+ (1,0) [0|65535] "unitless"  BCM
 SG_ DrSwtchInnrFr_No_Rq_UB : 32|1@0+ (1,0) [0|1] "SED"  BCM
 SG_ DrSwtchInnrFl_No_Rq_UB : 36|1@0+ (1,0) [0|1] "SED"  BCM
 SG_ DrSwtchInnrFr_No_Rq : 35|3@0+ (1,0) [0|7] "unitless"  BCM
 SG_ DrSwtchInnrFl_No_Rq : 39|3@0+ (1,0) [0|7] "unitless"  BCM

BO_ 72 Global_PATS_Target2: 8 SOBDMB_AWDC
 SG_ immoTarget2Status : 7|3@0+ (1,0) [0|7] "SED"  GWM,BCM
 SG_ immoTarget2Data : 15|40@0+ (1,0) [0|1099511627775] "Encrypted"  GWM,BCM
 SG_ immoTarget2Cmd : 4|3@0+ (1,0) [0|7] "SED"  GWM,BCM

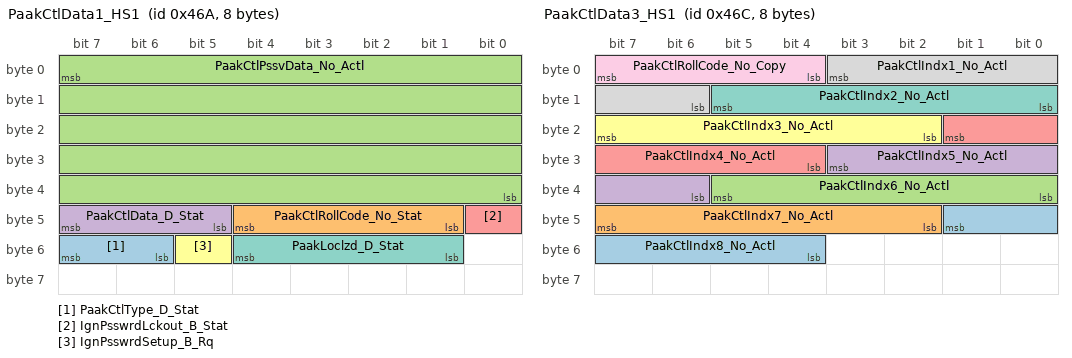
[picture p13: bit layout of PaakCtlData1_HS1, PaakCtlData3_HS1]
BO_ 1130 PaakCtlData1_HS1: 8 GWM
 SG_ PaakCtlType_D_Stat : 55|2@0+ (1,0) [0|3] "SED"  BCM
 SG_ PaakCtlRollCode_No_Stat : 44|4@0+ (1,0) [0|15] "unitless"  BCM
 SG_ PaakCtlPssvData_No_Actl : 7|40@0+ (1,0) [0|1099511627775] "unitless"  BCM
 SG_ PaakCtlData_D_Stat : 47|3@0+ (1,0) [0|7] "SED"  BCM
 SG_ IgnPsswrdLckout_B_Stat : 40|1@0+ (1,0) [0|1] "SED"  GENERIC
 SG_ IgnPsswrdSetup_B_Rq : 53|1@0+ (1,0) [0|1] "SED"  GENERIC
 SG_ PaakLoclzd_D_Stat : 52|4@0+ (1,0) [0|15] "SED"  BCM

BO_ 1132 PaakCtlData3_HS1: 8 GWM
 SG_ PaakCtlIndx8_No_Actl : 41|6@0+ (1,0) [0|63] "unitless"  BCM
 SG_ PaakCtlIndx7_No_Actl : 47|6@0+ (1,0) [0|63] "unitless"  BCM
 SG_ PaakCtlIndx6_No_Actl : 37|6@0+ (1,0) [0|63] "unitless"  BCM
 SG_ PaakCtlIndx5_No_Actl : 27|6@0+ (1,0) [0|63] "unitless"  BCM
 SG_ PaakCtlIndx4_No_Actl : 17|6@0+ (1,0) [0|63] "unitless"  BCM
 SG_ PaakCtlIndx3_No_Actl : 23|6@0+ (1,0) [0|63] "unitless"  BCM
 SG_ PaakCtlIndx2_No_Actl : 13|6@0+ (1,0) [0|63] "unitless"  BCM
 SG_ PaakCtlIndx1_No_Actl : 3|6@0+ (1,0) [0|63] "unitless"  BCM
 SG_ PaakCtlRollCode_No_Copy : 7|4@0+ (1,0) [0|15] "unitless"  BCM

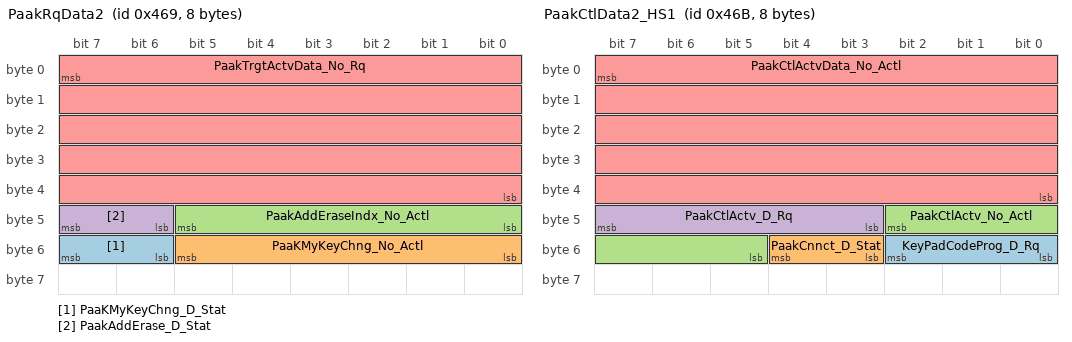
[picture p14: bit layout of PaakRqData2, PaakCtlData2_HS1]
BO_ 1129 PaakRqData2: 8 BCM
 SG_ PaaKMyKeyChng_D_Stat : 55|2@0+ (1,0) [0|3] "SED"  GWM
 SG_ PaaKMyKeyChng_No_Actl : 53|6@0+ (1,0) [0|63] "unitless"  GWM
 SG_ PaakAddEraseIndx_No_Actl : 45|6@0+ (1,0) [0|63] "unitless"  GWM
 SG_ PaakAddErase_D_Stat : 47|2@0+ (1,0) [0|3] "SED"  GWM
 SG_ PaakTrgtActvData_No_Rq : 7|40@0+ (1,0) [0|1099511627775] "unitless"  GWM

BO_ 1131 PaakCtlData2_HS1: 8 GWM
 SG_ KeyPadCodeProg_D_Rq : 50|3@0+ (1,0) [0|7] "SED"  BCM
 SG_ PaakCnnct_D_Stat : 52|2@0+ (1,0) [0|3] "SED"  GENERIC
 SG_ PaakCtlActv_No_Actl : 42|6@0+ (1,0) [0|63] "unitless"  BCM
 SG_ PaakCtlActv_D_Rq : 47|5@0+ (1,0) [0|31] "SED"  BCM
 SG_ PaakCtlActvData_No_Actl : 7|40@0+ (1,0) [0|1099511627775] "unitless"  BCM

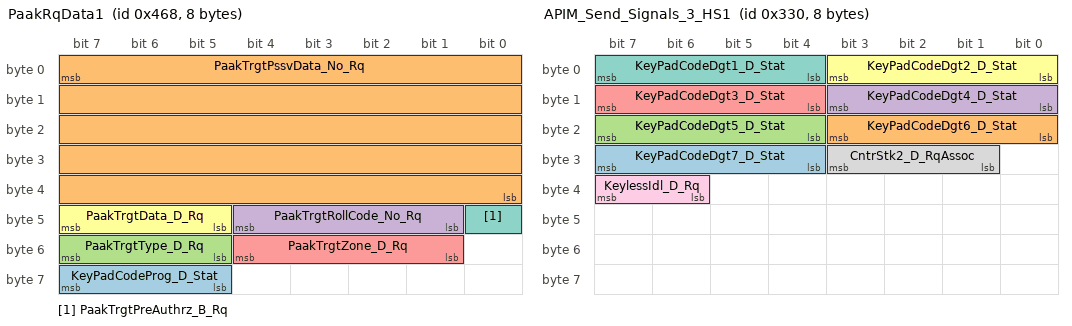
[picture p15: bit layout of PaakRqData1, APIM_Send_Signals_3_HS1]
BO_ 1128 PaakRqData1: 8 BCM
 SG_ KeyPadCodeProg_D_Stat : 63|3@0+ (1,0) [0|7] "SED"  GWM
 SG_ PaakTrgtPssvData_No_Rq : 7|40@0+ (1,0) [0|1099511627775] "unitless"  GWM
 SG_ PaakTrgtType_D_Rq : 55|3@0+ (1,0) [0|7] "SED"  GWM
 SG_ PaakTrgtRollCode_No_Rq : 44|4@0+ (1,0) [0|15] "unitless"  GWM
 SG_ PaakTrgtZone_D_Rq : 52|4@0+ (1,0) [0|15] "SED"  GWM
 SG_ PaakTrgtData_D_Rq : 47|3@0+ (1,0) [0|7] "SED"  GWM
 SG_ PaakTrgtPreAuthrz_B_Rq : 40|1@0+ (1,0) [0|1] "SED"  GWM

BO_ 123 Battery_Traction_2: 8 GWM
 SG_ BattTrac_U2_Actl : 21|12@0+ (0.5,0) [0|2046.5] "volt"  SOBDMB_AWDC,DCDC_HEV
 SG_ BattTrac_I2_Actl : 7|18@0+ (0.05,-6553.52) [-6553.52|6553.53] "ampere" Vector__XXX

BO_ 816 APIM_Send_Signals_3_HS1: 8 GWM
 SG_ KeyPadCodeDgt7_D_Stat : 31|4@0+ (1,0) [0|15] "SED"  BCM
 SG_ KeyPadCodeDgt6_D_Stat : 19|4@0+ (1,0) [0|15] "SED"  BCM
 SG_ KeyPadCodeDgt5_D_Stat : 23|4@0+ (1,0) [0|15] "SED"  BCM
 SG_ KeyPadCodeDgt4_D_Stat : 11|4@0+ (1,0) [0|15] "SED"  BCM
 SG_ KeyPadCodeDgt3_D_Stat : 15|4@0+ (1,0) [0|15] "SED"  BCM
 SG_ KeyPadCodeDgt2_D_Stat : 3|4@0+ (1,0) [0|15] "SED"  BCM
 SG_ KeyPadCodeDgt1_D_Stat : 7|4@0+ (1,0) [0|15] "SED"  BCM
 SG_ CntrStk2_D_RqAssoc : 27|3@0+ (1,0) [0|7] "SED"  BCM
 SG_ KeylessIdl_D_Rq : 39|2@0+ (1,0) [0|3] "SED"  BCM

BO_ 2612066520 PARSEDPushFcGWM_ECGtoPACM: 8 GWM
 SG_ PARSEDPushFcGWM_ECGtoPACM : 7|29@0+ (1,0) [0|536870911] "unitless"  PACM

BO_ 966 Body_Info_14: 8 BCM
 SG_ TrnkFrontInhbt_B_Stat : 26|1@0+ (1,0) [0|1] "SED"  GWM
 SG_ TrnkFrontRleas_D_Src : 20|3@0+ (1,0) [0|7] "SED"  GWM
 SG_ TrunkFrontOpen_No_Actl : 23|3@0+ (1,0) [0|7] "unitless"  GWM
 SG_ TrunkFrontRolCd_No_Actl : 7|16@0+ (1,0) [0|65535] "unitless"  GWM

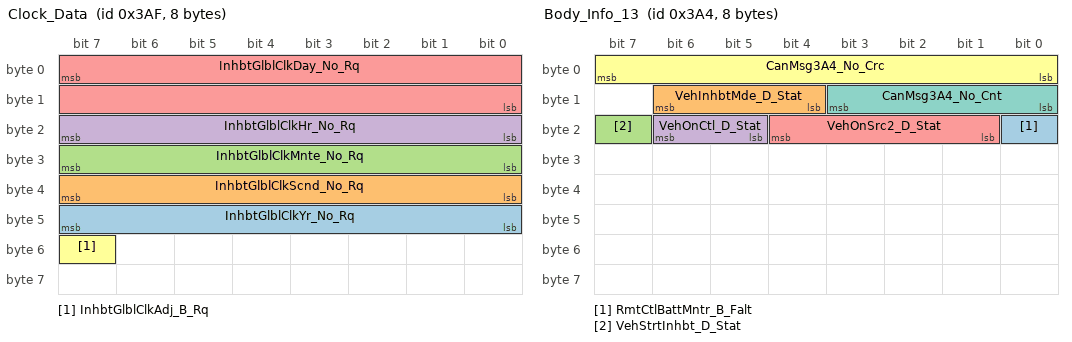
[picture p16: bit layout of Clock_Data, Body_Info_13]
BO_ 943 Clock_Data: 8 GWM
 SG_ InhbtGlblClkYr_No_Rq : 47|8@0+ (1,2000) [2000|2255] "year"  BCM
 SG_ InhbtGlblClkScnd_No_Rq : 39|8@0+ (1,0) [0|255] "second"  BCM
 SG_ InhbtGlblClkMnte_No_Rq : 31|8@0+ (1,0) [0|255] "minute"  BCM
 SG_ InhbtGlblClkHr_No_Rq : 23|8@0+ (1,0) [0|255] "hour"  BCM
 SG_ InhbtGlblClkDay_No_Rq : 7|16@0+ (1,0) [0|65535] "julian day"  BCM
 SG_ InhbtGlblClkAdj_B_Rq : 55|1@0+ (1,0) [0|1] "SED"  BCM

BO_ 932 Body_Info_13: 8 BCM
 SG_ RmtCtlBattMntr_B_Falt : 16|1@0+ (1,0) [0|1] "SED"  GWM
 SG_ VehInhbtMde_D_Stat : 14|3@0+ (1,0) [0|7] "SED"  GWM
 SG_ VehStrtInhbt_D_Stat : 23|1@0+ (1,0) [0|1] "SED"  GWM,PACM
 SG_ VehOnCtl_D_Stat : 22|2@0+ (1,0) [0|3] "SED"  GWM,PACM
 SG_ VehOnSrc2_D_Stat : 20|4@0+ (1,0) [0|15] "SED"  GWM
 SG_ CanMsg3A4_No_Crc : 7|8@0+ (1,0) [0|255] "Unitless"  GWM
 SG_ CanMsg3A4_No_Cnt : 11|4@0+ (1,0) [0|15] "Unitless"  GWM

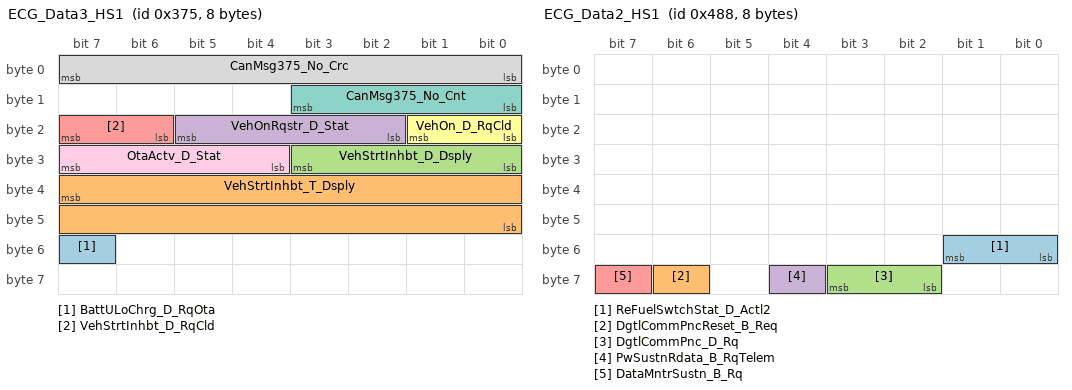
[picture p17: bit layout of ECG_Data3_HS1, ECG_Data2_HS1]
BO_ 885 ECG_Data3_HS1: 8 GWM
 SG_ BattULoChrg_D_RqOta : 55|1@0+ (1,0) [0|1] "SED"  BCM
 SG_ VehStrtInhbt_T_Dsply : 39|16@0+ (1,0) [0|65535] "second"  GENERIC
 SG_ VehStrtInhbt_D_Dsply : 27|4@0+ (1,0) [0|15] "SED"  GENERIC
 SG_ VehOnRqstr_D_Stat : 21|4@0+ (1,0) [0|15] "SED"  BCM
 SG_ VehStrtInhbt_D_RqCld : 23|2@0+ (1,0) [0|3] "SED"  BCM
 SG_ VehOn_D_RqCld : 17|2@0+ (1,0) [0|3] "SED"  BCM
 SG_ CanMsg375_No_Cnt : 11|4@0+ (1,0) [0|15] "unitless"  BCM
 SG_ CanMsg375_No_Crc : 7|8@0+ (1,0) [0|255] "unitless"  BCM
 SG_ OtaActv_D_Stat : 31|4@0+ (1,0) [0|15] "SED"  BCM

BO_ 1160 ECG_Data2_HS1: 8 GWM
 SG_ ReFuelSwtchStat_D_Actl2 : 49|2@0+ (1,0) [0|3] "SED"  GENERIC
 SG_ DgtlCommPncReset_B_Req : 62|1@0+ (1,0) [0|1] "SED" Vector__XXX
 SG_ DgtlCommPnc_D_Rq : 59|2@0+ (1,0) [0|3] "SED" Vector__XXX
 SG_ PwSustnRdata_B_RqTelem : 60|1@0+ (1,0) [0|1] "SED"  DCDC_HEV
 SG_ DataMntrSustn_B_Rq : 63|1@0+ (1,0) [0|1] "SED"  DCDC_HEV

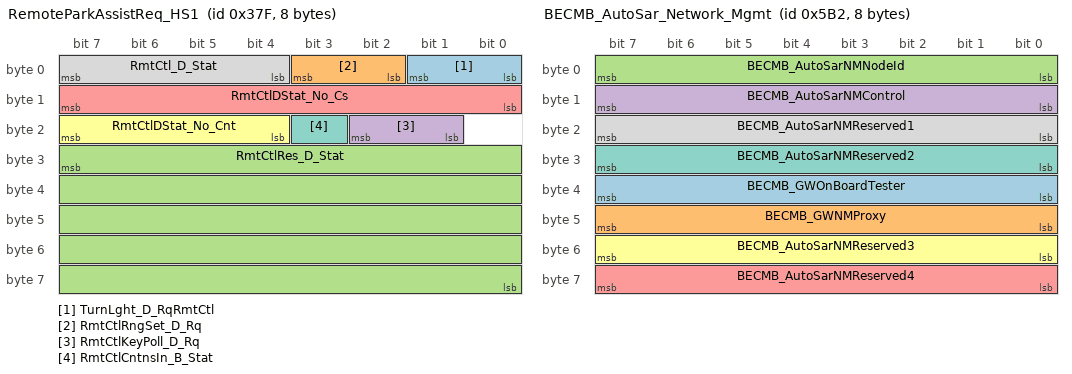
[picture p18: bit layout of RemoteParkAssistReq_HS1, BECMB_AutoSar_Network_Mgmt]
BO_ 895 RemoteParkAssistReq_HS1: 8 GWM
 SG_ TurnLght_D_RqRmtCtl : 1|2@0+ (1,0) [0|3] "SED" Vector__XXX
 SG_ RmtCtlRngSet_D_Rq : 3|2@0+ (1,0) [0|3] "SED" Vector__XXX
 SG_ RmtCtlRes_D_Stat : 31|40@0+ (1,0) [0|1099511627775] "unitless" Vector__XXX
 SG_ RmtCtlKeyPoll_D_Rq : 18|2@0+ (1,0) [0|3] "SED" Vector__XXX
 SG_ RmtCtlDStat_No_Cs : 15|8@0+ (1,0) [0|255] "Unitless" Vector__XXX
 SG_ RmtCtlDStat_No_Cnt : 23|4@0+ (1,0) [0|15] "Unitless" Vector__XXX
 SG_ RmtCtlCntnsIn_B_Stat : 19|1@0+ (1,0) [0|1] "SED" Vector__XXX
 SG_ RmtCtl_D_Stat : 7|4@0+ (1,0) [0|15] "SED" Vector__XXX

BO_ 515 PowertrainData_12_HS1: 8 GWM
 SG_ PtIgnSwtch_D_Stat : 7|2@0+ (1,0) [0|3] "SED"  BCM

BO_ 1119 Voltage_Power_Data2: 8 DCDC_HEV
 SG_ CoolFanDcdc_D_Rq : 5|2@0+ (1,0) [0|3] "SED"  GWM
 SG_ DcdcClntFlw_D_Rq : 7|2@0+ (1,0) [0|3] "SED"  SOBDMB_AWDC,GWM

BO_ 1827 TesterPhysicalReqBECMB_EPM: 8 TSTR
 SG_ TesterPhysicalReqBECMB_EPM : 7|64@0+ (1,0) [0|1.84467E+019] "unitless"  BECMB_EPM

BO_ 1835 TesterPhysicalResBECMB_EPM: 8 BECMB_EPM
 SG_ TesterPhysicalResBECMB_EPM : 7|64@0+ (1,0) [0|1.84467E+019] "unitless"  TSTR

BO_ 1110 Power_Stat: 8 BECMB_EPM
 SG_ RstrnMdulePw_D_Falt : 7|2@0+ (1,0) [0|3] "SED"  GWM

BO_ 1036 PedestrianAlert_Data: 8 PACM
 SG_ PdstrnAlrt_B_Falt : 7|1@0+ (1,0) [0|1] "SED"  GWM

BO_ 1152 HEV_Powertrain_Data6_HS1: 8 GWM
 SG_ PwOutlet8EnblScnd_B_Rq : 16|1@0+ (1,0) [0|1] "SED" Vector__XXX
 SG_ PwOutlet8Enbl_B_Rq : 17|1@0+ (1,0) [0|1] "SED" Vector__XXX
 SG_ PwOutlet7EnblScnd_B_Rq : 18|1@0+ (1,0) [0|1] "SED" Vector__XXX
 SG_ PwOutlet7Enbl_B_Rq : 19|1@0+ (1,0) [0|1] "SED" Vector__XXX
 SG_ PwOutlet6EnblScnd_B_Rq : 20|1@0+ (1,0) [0|1] "SED" Vector__XXX
 SG_ PwOutlet6Enbl_B_Rq : 21|1@0+ (1,0) [0|1] "SED" Vector__XXX
 SG_ PwCabinEnblScnd_B_Rq : 28|1@0+ (1,0) [0|1] "SED" Vector__XXX
 SG_ PwCabinEnbl_B_Rq : 29|1@0+ (1,0) [0|1] "SED" Vector__XXX
 SG_ PwTrnkFrntEnblScnd_B_Rq : 30|1@0+ (1,0) [0|1] "SED" Vector__XXX
 SG_ PwTrnkFrntEnbl_B_Rq : 31|1@0+ (1,0) [0|1] "SED" Vector__XXX
 SG_ OnePdlDrvLamp_B_Rq : 23|1@0+ (1,0) [0|1] "SED"  GENERIC
 SG_ OnePdlDrv_D_Dsply : 4|2@0+ (1,0) [0|3] "SED"  GENERIC
 SG_ HybPwULoLamp_B_Rq : 22|1@0+ (1,0) [0|1] "SED" Vector__XXX
 SG_ GrdAsstActv_B_Stat : 8|1@0+ (1,0) [0|1] "SED" Vector__XXX
 SG_ StopStrtVThres_D_Stat : 1|2@0+ (1,0) [0|3] "SED"  GENERIC
 SG_ VehElEff_No_Avg : 15|7@0+ (10,-100) [-100|1150] "watt*hr/km" Vector__XXX
 SG_ EngTeHi_B_Actl : 5|1@0+ (1,0) [0|1] "SED" Vector__XXX
 SG_ DcdcOn_B_Rq : 6|1@0+ (1,0) [0|1] "SED"  DCDC_HEV
 SG_ BattTracDiagClr_B_Stat : 2|1@0+ (1,0) [0|1] "SED" Vector__XXX
 SG_ ULoBattSpprtSustn_B_Rq : 7|1@0+ (1,0) [0|1] "SED"  BCM,DCDC_HEV

BO_ 1458 BECMB_AutoSar_Network_Mgmt: 8 BECMB_EPM
 SG_ BECMB_GWOnBoardTester : 39|8@0+ (1,0) [0|255] "unitless"  BCM,GWM
 SG_ BECMB_GWNMProxy : 47|8@0+ (1,0) [0|255] "unitless"  BCM,GWM
 SG_ BECMB_AutoSarNMNodeId : 7|8@0+ (1,0) [0|255] "unitless"  GWM,BCM
 SG_ BECMB_AutoSarNMControl : 15|8@0+ (1,0) [0|255] "unitless"  BCM,GWM
 SG_ BECMB_AutoSarNMReserved4 : 63|8@0+ (1,0) [0|255] "unitless"  BCM,GWM
 SG_ BECMB_AutoSarNMReserved3 : 55|8@0+ (1,0) [0|255] "unitless"  BCM,GWM
 SG_ BECMB_AutoSarNMReserved2 : 31|8@0+ (1,0) [0|255] "unitless"  GWM,BCM
 SG_ BECMB_AutoSarNMReserved1 : 23|8@0+ (1,0) [0|255] "unitless"  GWM,BCM

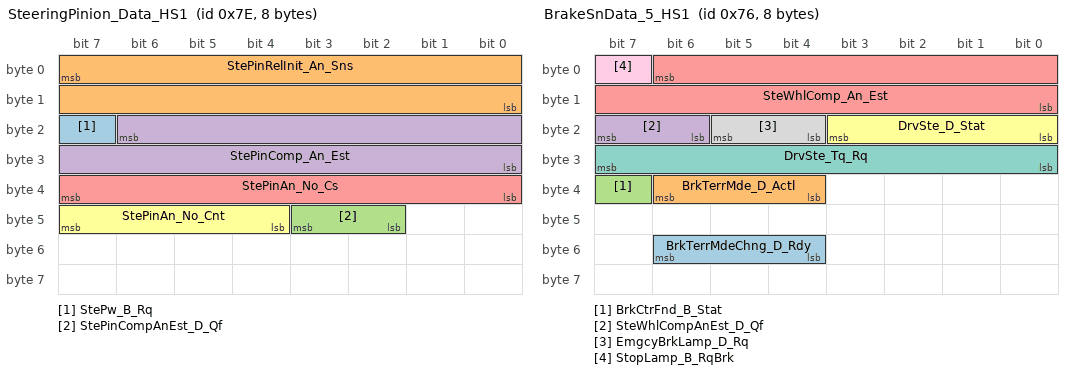
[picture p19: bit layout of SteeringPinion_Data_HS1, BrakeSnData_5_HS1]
BO_ 126 SteeringPinion_Data_HS1: 8 GWM
 SG_ StePw_B_Rq : 23|1@0+ (1,0) [0|1] "SED"  GENERIC
 SG_ StePinRelInit_An_Sns : 7|16@0+ (0.1,-3200) [-3200|3353.3] "degrees"  GENERIC
 SG_ StePinCompAnEst_D_Qf : 43|2@0+ (1,0) [0|3] "SED"  BCM
 SG_ StePinComp_An_Est : 22|15@0+ (0.1,-1600) [-1600|1676.7] "degrees"  BCM
 SG_ StePinAn_No_Cs : 39|8@0+ (1,0) [0|255] "Unitless"  GENERIC
 SG_ StePinAn_No_Cnt : 47|4@0+ (1,0) [0|15] "unitless"  GENERIC

BO_ 1872 TesterPhysicalReqPACM: 8 TSTR
 SG_ TesterPhysicalReqPACM : 7|64@0+ (1,0) [0|1.84467E+019] "unitless"  PACM

BO_ 1880 TesterPhysicalResPACM: 8 PACM
 SG_ TesterPhysicalResPACM : 7|64@0+ (1,0) [0|1.84467E+019] "unitless"  TSTR

BO_ 118 BrakeSnData_5_HS1: 8 GWM
 SG_ BrkTerrMdeChng_D_Rdy : 54|3@0+ (1,0) [0|7] "SED"  GENERIC
 SG_ BrkTerrMde_D_Actl : 38|3@0+ (1,0) [0|7] "SED"  GENERIC
 SG_ BrkCtrFnd_B_Stat : 39|1@0+ (1,0) [0|1] "SED"  GENERIC
 SG_ SteWhlCompAnEst_D_Qf : 23|2@0+ (1,0) [0|3] "SED"  BCM
 SG_ SteWhlComp_An_Est : 6|15@0+ (0.1,-1600) [-1600|1676.7] "deg"  BCM
 SG_ DrvSte_D_Stat : 19|4@0+ (1,0) [0|15] "SED"  GENERIC
 SG_ DrvSte_Tq_Rq : 31|8@0+ (0.0625,-8) [-8|7.8125] "Nm"  GENERIC
 SG_ EmgcyBrkLamp_D_Rq : 21|2@0+ (1,0) [0|3] "SED"  BCM
 SG_ StopLamp_B_RqBrk : 7|1@0+ (1,0) [0|1] "SED"  BCM

CM_ SG_ 1445 SOBDMC_AutoSarNMReserved4 "Signal not transmitted on gas and diesel variants.";
CM_ SG_ 1445 SOBDMC_AutoSarNMReserved3 "Signal not transmitted on gas and diesel variants.";
CM_ SG_ 1445 SOBDMC_AutoSarNMReserved2 "Signal not transmitted on gas and diesel variants.";
CM_ SG_ 1445 SOBDMC_AutoSarNMReserved1 "Signal not transmitted on gas and diesel variants.";
CM_ SG_ 1445 SOBDMC_AutoSarNMNodeId "Signal not transmitted on gas and diesel variants.";
CM_ SG_ 1445 SOBDMC_AutoSarNMControl "Signal not transmitted on gas and diesel variants.";
CM_ SG_ 942 PrkAidRdiusRight_L_Dsply "MSGDCR 679, set all signals to OnChange";
CM_ SG_ 942 PrkAidRdiusLeft_L_Dsply "MSGDCR 679, set all signals to OnChange";
CM_ SG_ 942 PrkAidDrvDir_D_Stat "MSGDCR 679, set all signals to OnChange";
CM_ SG_ 757 ACU_AutoStoreResult_St "Object Tuner. RadioSeekModeResult";
CM_ SG_ 757 ACU_DirectTune_St "Object.Tuner.DirectTune";
CM_ SG_ 757 ACU_RadioSeekMode2_St "Object Tuner.RadioSeekMode2";
CM_ SG_ 757 ACU_CurrTUBand_St "Object.Tuner.CurrentTUBand";
CM_ SG_ 562 OnePdlDrvDStat_No_Cnt "Signal not transmitted on gas variants.";
CM_ SG_ 562 OnePdlDrvDStat_No_Cs "Signal not transmitted on gas variants.";
CM_ SG_ 562 GearNtrl_No_Cs "Powersplit HEVs with HF45, HPCM will Tx  this message.  For all other programs it will be Tx by PCM or TCM. ";
CM_ SG_ 562 GearNtrl_No_Cnt "Powersplit HEVs with HF45, HPCM will Tx  this message.  For all other programs it will be Tx by PCM or TCM. ";
CM_ SG_ 931 CrnkInhbt_No_Cs "Signal not transmitted on gas and HEV variants.";
CM_ SG_ 931 CrnkInhbt_No_Cnt "Signal not transmitted on gas and HEV variants.";
CM_ SG_ 563 NtfyDrvTrgtDist_L2_Rq "Object.SetTripRangeAlert_Rq
This signal is meant to provide the customer settings for the target distance remote notification";
CM_ SG_ 1130 PaakCtlPssvData_No_Actl "Not transmitted on all vehicle variants";
CM_ SG_ 1129 PaakTrgtActvData_No_Rq "Not transmitted on all vehicle variants";
CM_ SG_ 1131 PaakCtlActvData_No_Actl "Not transmitted on all vehicle variants";
CM_ SG_ 1128 PaakTrgtPssvData_No_Rq "Not transmitted on all vehicle variants";
CM_ BO_ 932 "NOTE: START BITS 8-11 MUST BE OPEN SPEC REQUIREMENT";
CM_ SG_ 932 CanMsg3A4_No_Crc "Signal not transmitted on gas and HEV variants.";
CM_ SG_ 932 CanMsg3A4_No_Cnt "Signal not transmitted on gas and HEV variants.";
CM_ BO_ 885 "NOTE: START BITS 8-11 MUST BE OPEN SPEC REQUIREMENT";
CM_ BO_ 1160 "some signals from HS4 0x22A TCU_EM in CGEA1.3";
CM_ SG_ 126 StePinRelInit_An_Sns "SASM will transmit these signals on vehicles with SASM and without PSCM.  SCCM will not Tx this signal when SASM is present.";
CM_ SG_ 126 StePinAn_No_Cs "Signal not transmitted on gas variants.";
CM_ SG_ 118 SteWhlCompAnEst_D_Qf "Legacy signal not supported, reserving bit locations for commodity BCM, PAM, RCM, APIM dbc files.  GWM to Tx Init value, no valid data. ";
CM_ SG_ 118 SteWhlComp_An_Est "Legacy signal not supported, reserving bit locations for commodity BCM, PAM, RCM, APIM dbc files.  GWM to Tx Init value, no valid data. ";
BA_DEF_ BO_  "FrameRouting" STRING ;
BA_DEF_ BO_  "FrameGatewayNetwork" STRING ;
BA_DEF_ BO_  "NetworkInitialization" ENUM  "No","Yes";
BA_DEF_ BO_  "FrameGatewayId" HEX 0 1407;
BA_DEF_ BO_  "EventRateOfChange" INT 10 10000;
BA_DEF_ BO_  "GenMsgStartDelayTime" INT 0 10000;
BA_DEF_ BO_  "GenMsgNrOfRepetition" INT 0 100;
BA_DEF_ BO_  "GenMsgDelayTime" INT 0 1000;
BA_DEF_ BO_  "GenMsgCycleTime" INT 0 100000;
BA_DEF_ BO_  "GenMsgSendType" ENUM  "FixedPeriodic","Event","EnabledPeriodic","NotUsed","NotUsed","EventPeriodic","NotUsed","NotUsed","NoMsgSendType";
BA_DEF_ SG_  "U_CD764_MY2022_Tx" ENUM  "No","Yes";
BA_DEF_ SG_  "U_U55X_MY2022_Tx" ENUM  "No","Yes";
BA_DEF_ SG_  "U_CD542_MY2021_Tx" ENUM  "No","Yes";
BA_DEF_ SG_  "ECGUsedTxSignal" ENUM  "No","Yes";
BA_DEF_ SG_  "U_T6_MCA_MY2020_Tx" ENUM  "No","Yes";
BA_DEF_ SG_  "U_P702_MY2021_Tx" ENUM  "No","Yes";
BA_DEF_ SG_  "U_CX727_MY2021_Tx" ENUM  "No","Yes";
BA_DEF_ SG_  "U_CD764_MY2022_Rx" ENUM  "No","Yes";
BA_DEF_ SG_  "U_U55X_MY2022_Rx" ENUM  "No","Yes";
BA_DEF_ SG_  "U_CD542_MY2021_Rx" ENUM  "No","Yes";
BA_DEF_ SG_  "ECGUsedRxSignal" ENUM  "No","Yes";
BA_DEF_ SG_  "U_T6_MCA_MY2020_Rx" ENUM  "No","Yes";
BA_DEF_ SG_  "U_P702_MY2021_Rx" ENUM  "No","Yes";
BA_DEF_ SG_  "U_CX727_MY2021_Rx" ENUM  "No","Yes";
BA_DEF_ SG_  "GenSigStartValue" HEX 0 268435455;
BA_DEF_ SG_  "MetaData" ENUM  "No","Yes";
BA_DEF_ SG_  "ContentDependant" ENUM  "No","Yes";
BA_DEF_ SG_  "GenSigStartValueInteger" INT 0 1000000000;
BA_DEF_ SG_  "UsedOnPgmDBC" ENUM  "No","Yes";
BA_DEF_ SG_  "WakeupSignal" ENUM  "No","Yes";
BA_DEF_ SG_  "GenSigInactiveValue" INT 0 100000;
BA_DEF_ SG_  "GenSigSendType" ENUM  "Cyclic","OnWrite","vector_leerstring","OnChange","vector_leerstring","IfActive","vector_leerstring","NoSigSendType";
BA_DEF_ BO_  "OvtpPushApplication" ENUM  "FALSE","TRUE";
BA_DEF_ BO_  "SCP_FreshnessValueLength" INT 0 512;
BA_DEF_ BO_  "SCP_FreshnessValueTxLength" INT 0 512;
BA_DEF_ BO_  "SCP_AuthInfoTxLength" INT 0 512;
BA_DEF_ BO_  "GenMsgRoutingTimeoutTime" INT 0 5000;
BA_DEF_ BO_  "MessageGateway" ENUM  "No","Yes";
BA_DEF_ BO_  "NmAsrMessage" ENUM  "No","Yes";
BA_DEF_ BO_  "TpApplType" STRING ;
BA_DEF_ BO_  "DiagState" ENUM  "No","Yes";
BA_DEF_ BO_  "TpTxIndex" INT 0 536870911;
BA_DEF_ BO_  "DiagRequest" ENUM  "No","Yes";
BA_DEF_ BO_  "DiagResponse" ENUM  "No","Yes";
BA_DEF_ BO_  "GenMsgILSupport" ENUM  "No","Yes";
BA_DEF_DEF_  "FrameRouting" "";
BA_DEF_DEF_  "FrameGatewayNetwork" "NONE";
BA_DEF_DEF_  "NetworkInitialization" "Yes";
BA_DEF_DEF_  "FrameGatewayId" 0;
BA_DEF_DEF_  "EventRateOfChange" 10000;
BA_DEF_DEF_  "GenMsgStartDelayTime" 0;
BA_DEF_DEF_  "GenMsgNrOfRepetition" 1;
BA_DEF_DEF_  "GenMsgDelayTime" 20;
BA_DEF_DEF_  "GenMsgCycleTime" 0;
BA_DEF_DEF_  "GenMsgSendType" "NoMsgSendType";
BA_DEF_DEF_  "U_CD764_MY2022_Tx" "No";
BA_DEF_DEF_  "U_U55X_MY2022_Tx" "No";
BA_DEF_DEF_  "U_CD542_MY2021_Tx" "No";
BA_DEF_DEF_  "ECGUsedTxSignal" "No";
BA_DEF_DEF_  "U_T6_MCA_MY2020_Tx" "No";
BA_DEF_DEF_  "U_P702_MY2021_Tx" "No";
BA_DEF_DEF_  "U_CX727_MY2021_Tx" "No";
BA_DEF_DEF_  "U_CD764_MY2022_Rx" "No";
BA_DEF_DEF_  "U_U55X_MY2022_Rx" "No";
BA_DEF_DEF_  "U_CD542_MY2021_Rx" "No";
BA_DEF_DEF_  "ECGUsedRxSignal" "No";
BA_DEF_DEF_  "U_T6_MCA_MY2020_Rx" "No";
BA_DEF_DEF_  "U_P702_MY2021_Rx" "No";
BA_DEF_DEF_  "U_CX727_MY2021_Rx" "No";
BA_DEF_DEF_  "GenSigStartValue" 0;
BA_DEF_DEF_  "MetaData" "No";
BA_DEF_DEF_  "ContentDependant" "No";
BA_DEF_DEF_  "GenSigStartValueInteger" 0;
BA_DEF_DEF_  "UsedOnPgmDBC" "Yes";
BA_DEF_DEF_  "WakeupSignal" "No";
BA_DEF_DEF_  "GenSigInactiveValue" 0;
BA_DEF_DEF_  "GenSigSendType" "NoSigSendType";
BA_DEF_DEF_  "OvtpPushApplication" "FALSE";
BA_DEF_DEF_  "SCP_FreshnessValueLength" 64;
BA_DEF_DEF_  "SCP_FreshnessValueTxLength" 11;
BA_DEF_DEF_  "SCP_AuthInfoTxLength" 53;
BA_DEF_DEF_  "GenMsgRoutingTimeoutTime" 0;
BA_DEF_DEF_  "MessageGateway" "No";
BA_DEF_DEF_  "NmAsrMessage" "No";
BA_DEF_DEF_  "TpApplType" "";
BA_DEF_DEF_  "DiagState" "No";
BA_DEF_DEF_  "TpTxIndex" 0;
BA_DEF_DEF_  "DiagRequest" "No";
BA_DEF_DEF_  "DiagResponse" "No";
BA_DEF_DEF_  "GenMsgILSupport" "Yes";
BA_ "FrameGatewayId" BO_ 1179 1179;
BA_ "FrameRouting" BO_ 1179 "HS5_CAN,0x49B";
BA_ "FrameGatewayNetwork" BO_ 1179 "HS5_CAN";
BA_ "FrameGatewayId" BO_ 1178 1178;
BA_ "FrameRouting" BO_ 1178 "HS5_CAN,0x49A";
BA_ "FrameGatewayNetwork" BO_ 1178 "HS5_CAN";
BA_ "FrameGatewayId" BO_ 1177 1177;
BA_ "FrameRouting" BO_ 1177 "HS5_CAN,0x499";
BA_ "FrameGatewayNetwork" BO_ 1177 "HS5_CAN";
BA_ "FrameGatewayId" BO_ 1168 1168;
BA_ "FrameRouting" BO_ 1168 "HS5_CAN,0x490";
BA_ "FrameGatewayNetwork" BO_ 1168 "HS5_CAN";
BA_ "FrameGatewayId" BO_ 1092 1092;
BA_ "FrameRouting" BO_ 1092 "HS5_CAN,0x444";
BA_ "FrameGatewayNetwork" BO_ 1092 "HS5_CAN";
BA_ "GenMsgILSupport" BO_ 1445 0;
BA_ "NmAsrMessage" BO_ 1445 1;
BA_ "NetworkInitialization" BO_ 1445 0;
BA_ "FrameGatewayId" BO_ 606 606;
BA_ "FrameGatewayNetwork" BO_ 606 "FD1_CAN";
BA_ "FrameRouting" BO_ 606 "FD1_CAN,0x25E;";
BA_ "FrameGatewayId" BO_ 942 942;
BA_ "FrameGatewayNetwork" BO_ 942 "FD1_CAN";
BA_ "FrameRouting" BO_ 942 "FD1_CAN,0x3AE;HS2_CAN,0x3EA;";
BA_ "FrameGatewayId" BO_ 757 757;
BA_ "FrameGatewayNetwork" BO_ 757 "HS3_CAN";
BA_ "FrameRouting" BO_ 757 "HS3_CAN,0x2F5;";
BA_ "FrameGatewayId" BO_ 646 646;
BA_ "FrameGatewayNetwork" BO_ 646 "HS5_CAN";
BA_ "FrameRouting" BO_ 646 "HS5_CAN,0x286";
BA_ "FrameGatewayId" BO_ 1229 1229;
BA_ "FrameGatewayNetwork" BO_ 1229 "FD1_CAN";
BA_ "FrameRouting" BO_ 1229 "FD1_CAN,0x4CD;";
BA_ "GenMsgSendType" BO_ 650 5;
BA_ "GenMsgCycleTime" BO_ 650 500;
BA_ "GenMsgSendType" BO_ 655 0;
BA_ "GenMsgCycleTime" BO_ 655 500;
BA_ "FrameGatewayId" BO_ 599 599;
BA_ "FrameGatewayNetwork" BO_ 599 "HS5_CAN";
BA_ "FrameRouting" BO_ 599 "HS5_CAN,0x257";
BA_ "GenMsgSendType" BO_ 528 5;
BA_ "GenMsgCycleTime" BO_ 528 1000;
BA_ "GenMsgSendType" BO_ 955 0;
BA_ "GenMsgCycleTime" BO_ 955 1000;
BA_ "FrameGatewayId" BO_ 749 749;
BA_ "FrameRouting" BO_ 749 "HS5_CAN,0x2ED";
BA_ "FrameGatewayNetwork" BO_ 749 "HS5_CAN";
BA_ "FrameGatewayId" BO_ 624 624;
BA_ "FrameGatewayNetwork" BO_ 624 "HS4_CAN";
BA_ "FrameRouting" BO_ 624 "HS4_CAN,0x270;";
BA_ "FrameGatewayId" BO_ 580 580;
BA_ "FrameGatewayNetwork" BO_ 580 "HS5_CAN";
BA_ "FrameRouting" BO_ 580 "HS5_CAN,0x244";
BA_ "GenMsgSendType" BO_ 622 5;
BA_ "GenMsgCycleTime" BO_ 622 200;
BA_ "GenMsgSendType" BO_ 1050 5;
BA_ "GenMsgCycleTime" BO_ 1050 1000;
BA_ "GenMsgSendType" BO_ 1217 5;
BA_ "GenMsgCycleTime" BO_ 1217 1000;
BA_ "GenMsgSendType" BO_ 1216 5;
BA_ "GenMsgCycleTime" BO_ 1216 1000;
BA_ "FrameGatewayId" BO_ 1087 1087;
BA_ "FrameGatewayNetwork" BO_ 1087 "FD1_CAN";
BA_ "FrameRouting" BO_ 1087 "FD1_CAN,0x43F;";
BA_ "FrameGatewayId" BO_ 562 562;
BA_ "FrameGatewayNetwork" BO_ 562 "FD1_CAN";
BA_ "FrameRouting" BO_ 562 "FD1_CAN,0x232;";
BA_ "FrameGatewayId" BO_ 533 533;
BA_ "FrameGatewayNetwork" BO_ 533 "HS3_CAN";
BA_ "FrameRouting" BO_ 533 "HS3_CAN,0x215;";
BA_ "FrameGatewayId" BO_ 1012 1012;
BA_ "FrameGatewayNetwork" BO_ 1012 "FD1_CAN";
BA_ "FrameRouting" BO_ 1012 "FD1_CAN,0x3F4;";
BA_ "GenMsgSendType" BO_ 874 5;
BA_ "GenMsgCycleTime" BO_ 874 1000;
BA_ "GenMsgSendType" BO_ 912 5;
BA_ "GenMsgCycleTime" BO_ 912 1000;
BA_ "GenMsgSendType" BO_ 931 0;
BA_ "GenMsgCycleTime" BO_ 931 60;
BA_ "GenMsgILSupport" BO_ 1488 0;
BA_ "NmAsrMessage" BO_ 1488 1;
BA_ "GenMsgSendType" BO_ 1488 0;
BA_ "GenMsgCycleTime" BO_ 1488 1000;
BA_ "NetworkInitialization" BO_ 1488 0;
BA_ "GenMsgILSupport" BO_ 1776 0;
BA_ "DiagRequest" BO_ 1776 1;
BA_ "GenMsgSendType" BO_ 1776 1;
BA_ "GenMsgDelayTime" BO_ 1776 0;
BA_ "NetworkInitialization" BO_ 1776 0;
BA_ "GenMsgILSupport" BO_ 1784 0;
BA_ "DiagResponse" BO_ 1784 1;
BA_ "GenMsgSendType" BO_ 1784 1;
BA_ "GenMsgDelayTime" BO_ 1784 0;
BA_ "NetworkInitialization" BO_ 1784 0;
BA_ "GenMsgSendType" BO_ 563 5;
BA_ "GenMsgCycleTime" BO_ 563 1000;
BA_ "FrameGatewayId" BO_ 621 621;
BA_ "FrameGatewayNetwork" BO_ 621 "HS4_CAN";
BA_ "FrameRouting" BO_ 621 "HS4_CAN,0x26D;";
BA_ "FrameGatewayId" BO_ 1149 1149;
BA_ "FrameGatewayNetwork" BO_ 1149 "HS5_CAN";
BA_ "FrameRouting" BO_ 1149 "HS5_CAN,0x47D";
BA_ "FrameGatewayId" BO_ 626 626;
BA_ "FrameGatewayNetwork" BO_ 626 "HS4_CAN";
BA_ "FrameRouting" BO_ 626 "HS4_CAN,0x272;";
BA_ "FrameGatewayId" BO_ 1135 1135;
BA_ "FrameRouting" BO_ 1135 "HS5_CAN,0x46F";
BA_ "FrameGatewayNetwork" BO_ 1135 "HS5_CAN";
BA_ "GenMsgSendType" BO_ 1161 5;
BA_ "GenMsgCycleTime" BO_ 1161 1000;
BA_ "GenMsgSendType" BO_ 960 5;
BA_ "GenMsgCycleTime" BO_ 960 1000;
BA_ "GenMsgSendType" BO_ 957 5;
BA_ "GenMsgCycleTime" BO_ 957 1000;
BA_ "GenMsgSendType" BO_ 1159 5;
BA_ "GenMsgCycleTime" BO_ 1159 1000;
BA_ "GenMsgCycleTime" BO_ 72 20;
BA_ "GenMsgSendType" BO_ 72 0;
BA_ "FrameGatewayId" BO_ 1130 618;
BA_ "FrameGatewayNetwork" BO_ 1130 "HS4_CAN";
BA_ "FrameRouting" BO_ 1130 "HS4_CAN,0x26A;";
BA_ "FrameGatewayId" BO_ 1132 620;
BA_ "FrameGatewayNetwork" BO_ 1132 "HS4_CAN";
BA_ "FrameRouting" BO_ 1132 "HS4_CAN,0x26C;";
BA_ "GenMsgSendType" BO_ 1129 5;
BA_ "GenMsgCycleTime" BO_ 1129 200;
BA_ "FrameGatewayId" BO_ 1131 619;
BA_ "FrameGatewayNetwork" BO_ 1131 "HS4_CAN";
BA_ "FrameRouting" BO_ 1131 "HS4_CAN,0x26B;";
BA_ "GenMsgSendType" BO_ 1128 5;
BA_ "GenMsgCycleTime" BO_ 1128 200;
BA_ "FrameGatewayId" BO_ 123 123;
BA_ "FrameGatewayNetwork" BO_ 123 "HS5_CAN";
BA_ "FrameRouting" BO_ 123 "HS5_CAN,0x7B";
BA_ "FrameGatewayId" BO_ 816 816;
BA_ "FrameGatewayNetwork" BO_ 816 "HS3_CAN";
BA_ "FrameRouting" BO_ 816 "HS3_CAN,0x330;";
BA_ "TpTxIndex" BO_ 2612066520 464582872;
BA_ "OvtpPushApplication" BO_ 2612066520 1;
BA_ "GenMsgSendType" BO_ 2612066520 1;
BA_ "GenMsgDelayTime" BO_ 2612066520 0;
BA_ "NetworkInitialization" BO_ 2612066520 0;
BA_ "GenMsgSendType" BO_ 966 5;
BA_ "GenMsgCycleTime" BO_ 966 1000;
BA_ "GenMsgSendType" BO_ 943 1;
BA_ "GenMsgSendType" BO_ 932 0;
BA_ "GenMsgCycleTime" BO_ 932 200;
BA_ "GenMsgSendType" BO_ 885 0;
BA_ "GenMsgCycleTime" BO_ 885 200;
BA_ "GenMsgSendType" BO_ 1160 5;
BA_ "GenMsgCycleTime" BO_ 1160 1000;
BA_ "FrameGatewayId" BO_ 895 895;
BA_ "FrameGatewayNetwork" BO_ 895 "HS4_CAN";
BA_ "FrameRouting" BO_ 895 "HS4_CAN,0x37F;";
BA_ "FrameGatewayId" BO_ 515 515;
BA_ "FrameGatewayNetwork" BO_ 515 "FD1_CAN";
BA_ "FrameRouting" BO_ 515 "FD1_CAN,0x203;";
BA_ "GenMsgSendType" BO_ 1119 5;
BA_ "GenMsgCycleTime" BO_ 1119 1000;
BA_ "GenMsgILSupport" BO_ 1827 0;
BA_ "DiagRequest" BO_ 1827 1;
BA_ "GenMsgSendType" BO_ 1827 1;
BA_ "GenMsgDelayTime" BO_ 1827 0;
BA_ "NetworkInitialization" BO_ 1827 0;
BA_ "GenMsgILSupport" BO_ 1835 0;
BA_ "DiagResponse" BO_ 1835 1;
BA_ "GenMsgSendType" BO_ 1835 1;
BA_ "GenMsgDelayTime" BO_ 1835 0;
BA_ "NetworkInitialization" BO_ 1835 0;
BA_ "GenMsgSendType" BO_ 1110 0;
BA_ "GenMsgCycleTime" BO_ 1110 1000;
BA_ "GenMsgSendType" BO_ 1036 5;
BA_ "GenMsgCycleTime" BO_ 1036 1000;
BA_ "FrameGatewayId" BO_ 1152 1152;
BA_ "FrameGatewayNetwork" BO_ 1152 "FD1_CAN";
BA_ "FrameRouting" BO_ 1152 "FD1_CAN,0x480;";
BA_ "GenMsgILSupport" BO_ 1458 0;
BA_ "NmAsrMessage" BO_ 1458 1;
BA_ "GenMsgSendType" BO_ 1458 0;
BA_ "GenMsgCycleTime" BO_ 1458 1000;
BA_ "NetworkInitialization" BO_ 1458 0;
BA_ "MessageGateway" BO_ 126 1;
BA_ "GenMsgRoutingTimeoutTime" BO_ 126 30;
BA_ "GenMsgSendType" BO_ 126 0;
BA_ "GenMsgCycleTime" BO_ 126 20;
BA_ "GenMsgDelayTime" BO_ 126 10;
BA_ "GenMsgILSupport" BO_ 1872 0;
BA_ "DiagRequest" BO_ 1872 1;
BA_ "GenMsgSendType" BO_ 1872 1;
BA_ "GenMsgDelayTime" BO_ 1872 0;
BA_ "NetworkInitialization" BO_ 1872 0;
BA_ "GenMsgILSupport" BO_ 1880 0;
BA_ "DiagResponse" BO_ 1880 1;
BA_ "GenMsgSendType" BO_ 1880 1;
BA_ "GenMsgDelayTime" BO_ 1880 0;
BA_ "NetworkInitialization" BO_ 1880 0;
BA_ "FrameGatewayId" BO_ 118 118;
BA_ "FrameGatewayNetwork" BO_ 118 "FD1_CAN";
BA_ "FrameRouting" BO_ 118 "FD1_CAN,0x76;";
BA_ "U_CD542_MY2021_Tx" SG_ 1179 BattTracCell60_U_Actl 1;
BA_ "U_CX727_MY2021_Tx" SG_ 1179 BattTracCell60_U_Actl 1;
BA_ "U_U55X_MY2022_Rx" SG_ 1179 BattTracCell60_U_Actl 1;
BA_ "U_CD542_MY2021_Rx" SG_ 1179 BattTracCell60_U_Actl 1;
BA_ "ECGUsedRxSignal" SG_ 1179 BattTracCell60_U_Actl 1;
BA_ "GenSigStartValue" SG_ 1179 BattTracCell60_U_Actl 4094;
BA_ "GenSigStartValueInteger" SG_ 1179 BattTracCell60_U_Actl 4094;
BA_ "U_CD542_MY2021_Tx" SG_ 1179 BattTracCell59_U_Actl 1;
BA_ "U_CX727_MY2021_Tx" SG_ 1179 BattTracCell59_U_Actl 1;
BA_ "U_U55X_MY2022_Rx" SG_ 1179 BattTracCell59_U_Actl 1;
BA_ "U_CD542_MY2021_Rx" SG_ 1179 BattTracCell59_U_Actl 1;
BA_ "ECGUsedRxSignal" SG_ 1179 BattTracCell59_U_Actl 1;
BA_ "GenSigStartValue" SG_ 1179 BattTracCell59_U_Actl 4094;
BA_ "GenSigStartValueInteger" SG_ 1179 BattTracCell59_U_Actl 4094;
BA_ "U_CD542_MY2021_Tx" SG_ 1179 BattTracCell58_U_Actl 1;
BA_ "U_CX727_MY2021_Tx" SG_ 1179 BattTracCell58_U_Actl 1;
BA_ "U_U55X_MY2022_Rx" SG_ 1179 BattTracCell58_U_Actl 1;
BA_ "U_CD542_MY2021_Rx" SG_ 1179 BattTracCell58_U_Actl 1;
BA_ "ECGUsedRxSignal" SG_ 1179 BattTracCell58_U_Actl 1;
BA_ "GenSigStartValue" SG_ 1179 BattTracCell58_U_Actl 4094;
BA_ "GenSigStartValueInteger" SG_ 1179 BattTracCell58_U_Actl 4094;
BA_ "U_CD542_MY2021_Tx" SG_ 1179 BattTracCell57_U_Actl 1;
BA_ "U_CX727_MY2021_Tx" SG_ 1179 BattTracCell57_U_Actl 1;
BA_ "U_U55X_MY2022_Rx" SG_ 1179 BattTracCell57_U_Actl 1;
BA_ "U_CD542_MY2021_Rx" SG_ 1179 BattTracCell57_U_Actl 1;
BA_ "ECGUsedRxSignal" SG_ 1179 BattTracCell57_U_Actl 1;
BA_ "GenSigStartValue" SG_ 1179 BattTracCell57_U_Actl 4094;
BA_ "GenSigStartValueInteger" SG_ 1179 BattTracCell57_U_Actl 4094;
BA_ "U_CD542_MY2021_Tx" SG_ 1179 BattTracCell56_U_Actl 1;
BA_ "U_CX727_MY2021_Tx" SG_ 1179 BattTracCell56_U_Actl 1;
BA_ "U_U55X_MY2022_Rx" SG_ 1179 BattTracCell56_U_Actl 1;
BA_ "U_CD542_MY2021_Rx" SG_ 1179 BattTracCell56_U_Actl 1;
BA_ "ECGUsedRxSignal" SG_ 1179 BattTracCell56_U_Actl 1;
BA_ "GenSigStartValue" SG_ 1179 BattTracCell56_U_Actl 4094;
BA_ "GenSigStartValueInteger" SG_ 1179 BattTracCell56_U_Actl 4094;
BA_ "U_CD542_MY2021_Tx" SG_ 1178 BattTracCell55_U_Actl 1;
BA_ "U_CX727_MY2021_Tx" SG_ 1178 BattTracCell55_U_Actl 1;
BA_ "U_U55X_MY2022_Rx" SG_ 1178 BattTracCell55_U_Actl 1;
BA_ "U_CD542_MY2021_Rx" SG_ 1178 BattTracCell55_U_Actl 1;
BA_ "ECGUsedRxSignal" SG_ 1178 BattTracCell55_U_Actl 1;
BA_ "GenSigStartValue" SG_ 1178 BattTracCell55_U_Actl 4094;
BA_ "GenSigStartValueInteger" SG_ 1178 BattTracCell55_U_Actl 4094;
BA_ "U_CD542_MY2021_Tx" SG_ 1178 BattTracCell54_U_Actl 1;
BA_ "U_CX727_MY2021_Tx" SG_ 1178 BattTracCell54_U_Actl 1;
BA_ "U_U55X_MY2022_Rx" SG_ 1178 BattTracCell54_U_Actl 1;
BA_ "U_CD542_MY2021_Rx" SG_ 1178 BattTracCell54_U_Actl 1;
BA_ "ECGUsedRxSignal" SG_ 1178 BattTracCell54_U_Actl 1;
BA_ "GenSigStartValue" SG_ 1178 BattTracCell54_U_Actl 4094;
BA_ "GenSigStartValueInteger" SG_ 1178 BattTracCell54_U_Actl 4094;
BA_ "U_CD542_MY2021_Tx" SG_ 1178 BattTracCell53_U_Actl 1;
BA_ "U_CX727_MY2021_Tx" SG_ 1178 BattTracCell53_U_Actl 1;
BA_ "U_U55X_MY2022_Rx" SG_ 1178 BattTracCell53_U_Actl 1;
BA_ "U_CD542_MY2021_Rx" SG_ 1178 BattTracCell53_U_Actl 1;
BA_ "ECGUsedRxSignal" SG_ 1178 BattTracCell53_U_Actl 1;
BA_ "GenSigStartValue" SG_ 1178 BattTracCell53_U_Actl 4094;
BA_ "GenSigStartValueInteger" SG_ 1178 BattTracCell53_U_Actl 4094;
BA_ "U_CD542_MY2021_Tx" SG_ 1178 BattTracCell52_U_Actl 1;
BA_ "U_CX727_MY2021_Tx" SG_ 1178 BattTracCell52_U_Actl 1;
BA_ "U_U55X_MY2022_Rx" SG_ 1178 BattTracCell52_U_Actl 1;
BA_ "U_CD542_MY2021_Rx" SG_ 1178 BattTracCell52_U_Actl 1;
BA_ "ECGUsedRxSignal" SG_ 1178 BattTracCell52_U_Actl 1;
BA_ "GenSigStartValue" SG_ 1178 BattTracCell52_U_Actl 4094;
BA_ "GenSigStartValueInteger" SG_ 1178 BattTracCell52_U_Actl 4094;
BA_ "U_CD542_MY2021_Tx" SG_ 1178 BattTracCell51_U_Actl 1;
BA_ "U_CX727_MY2021_Tx" SG_ 1178 BattTracCell51_U_Actl 1;
BA_ "U_U55X_MY2022_Rx" SG_ 1178 BattTracCell51_U_Actl 1;
BA_ "U_CD542_MY2021_Rx" SG_ 1178 BattTracCell51_U_Actl 1;
BA_ "ECGUsedRxSignal" SG_ 1178 BattTracCell51_U_Actl 1;
BA_ "GenSigStartValue" SG_ 1178 BattTracCell51_U_Actl 4094;
BA_ "GenSigStartValueInteger" SG_ 1178 BattTracCell51_U_Actl 4094;
BA_ "U_CD542_MY2021_Tx" SG_ 1177 BattTracCell50_U_Actl 1;
BA_ "U_CX727_MY2021_Tx" SG_ 1177 BattTracCell50_U_Actl 1;
BA_ "U_U55X_MY2022_Rx" SG_ 1177 BattTracCell50_U_Actl 1;
BA_ "U_CD542_MY2021_Rx" SG_ 1177 BattTracCell50_U_Actl 1;
BA_ "ECGUsedRxSignal" SG_ 1177 BattTracCell50_U_Actl 1;
BA_ "GenSigStartValue" SG_ 1177 BattTracCell50_U_Actl 4094;
BA_ "GenSigStartValueInteger" SG_ 1177 BattTracCell50_U_Actl 4094;
BA_ "U_CD542_MY2021_Tx" SG_ 1177 BattTracCell49_U_Actl 1;
BA_ "U_CX727_MY2021_Tx" SG_ 1177 BattTracCell49_U_Actl 1;
BA_ "U_U55X_MY2022_Rx" SG_ 1177 BattTracCell49_U_Actl 1;
BA_ "U_CD542_MY2021_Rx" SG_ 1177 BattTracCell49_U_Actl 1;
BA_ "ECGUsedRxSignal" SG_ 1177 BattTracCell49_U_Actl 1;
BA_ "GenSigStartValue" SG_ 1177 BattTracCell49_U_Actl 4094;
BA_ "GenSigStartValueInteger" SG_ 1177 BattTracCell49_U_Actl 4094;
BA_ "U_CD542_MY2021_Tx" SG_ 1177 BattTracCell48_U_Actl 1;
BA_ "U_CX727_MY2021_Tx" SG_ 1177 BattTracCell48_U_Actl 1;
BA_ "U_U55X_MY2022_Rx" SG_ 1177 BattTracCell48_U_Actl 1;
BA_ "U_CD542_MY2021_Rx" SG_ 1177 BattTracCell48_U_Actl 1;
BA_ "ECGUsedRxSignal" SG_ 1177 BattTracCell48_U_Actl 1;
BA_ "GenSigStartValue" SG_ 1177 BattTracCell48_U_Actl 4094;
BA_ "GenSigStartValueInteger" SG_ 1177 BattTracCell48_U_Actl 4094;
BA_ "U_CD542_MY2021_Tx" SG_ 1177 BattTracCell47_U_Actl 1;
BA_ "U_CX727_MY2021_Tx" SG_ 1177 BattTracCell47_U_Actl 1;
BA_ "U_U55X_MY2022_Rx" SG_ 1177 BattTracCell47_U_Actl 1;
BA_ "U_CD542_MY2021_Rx" SG_ 1177 BattTracCell47_U_Actl 1;
BA_ "ECGUsedRxSignal" SG_ 1177 BattTracCell47_U_Actl 1;
BA_ "GenSigStartValue" SG_ 1177 BattTracCell47_U_Actl 4094;
BA_ "GenSigStartValueInteger" SG_ 1177 BattTracCell47_U_Actl 4094;
BA_ "U_CD542_MY2021_Tx" SG_ 1177 BattTracCell46_U_Actl 1;
BA_ "U_CX727_MY2021_Tx" SG_ 1177 BattTracCell46_U_Actl 1;
BA_ "U_U55X_MY2022_Rx" SG_ 1177 BattTracCell46_U_Actl 1;
BA_ "U_CD542_MY2021_Rx" SG_ 1177 BattTracCell46_U_Actl 1;
BA_ "ECGUsedRxSignal" SG_ 1177 BattTracCell46_U_Actl 1;
BA_ "GenSigStartValue" SG_ 1177 BattTracCell46_U_Actl 4094;
BA_ "GenSigStartValueInteger" SG_ 1177 BattTracCell46_U_Actl 4094;
BA_ "U_CD542_MY2021_Tx" SG_ 1168 BattTracCell05_U_Actl 1;
BA_ "U_CX727_MY2021_Tx" SG_ 1168 BattTracCell05_U_Actl 1;
BA_ "U_U55X_MY2022_Rx" SG_ 1168 BattTracCell05_U_Actl 1;
BA_ "U_CD542_MY2021_Rx" SG_ 1168 BattTracCell05_U_Actl 1;
BA_ "ECGUsedRxSignal" SG_ 1168 BattTracCell05_U_Actl 1;
BA_ "GenSigStartValue" SG_ 1168 BattTracCell05_U_Actl 4094;
BA_ "GenSigStartValueInteger" SG_ 1168 BattTracCell05_U_Actl 4094;
BA_ "U_CD542_MY2021_Tx" SG_ 1168 BattTracCell04_U_Actl 1;
BA_ "U_CX727_MY2021_Tx" SG_ 1168 BattTracCell04_U_Actl 1;
BA_ "U_U55X_MY2022_Rx" SG_ 1168 BattTracCell04_U_Actl 1;
BA_ "U_CD542_MY2021_Rx" SG_ 1168 BattTracCell04_U_Actl 1;
BA_ "ECGUsedRxSignal" SG_ 1168 BattTracCell04_U_Actl 1;
BA_ "GenSigStartValue" SG_ 1168 BattTracCell04_U_Actl 4094;
BA_ "GenSigStartValueInteger" SG_ 1168 BattTracCell04_U_Actl 4094;
BA_ "U_CD542_MY2021_Tx" SG_ 1168 BattTracCell03_U_Actl 1;
BA_ "U_CX727_MY2021_Tx" SG_ 1168 BattTracCell03_U_Actl 1;
BA_ "U_U55X_MY2022_Rx" SG_ 1168 BattTracCell03_U_Actl 1;
BA_ "U_CD542_MY2021_Rx" SG_ 1168 BattTracCell03_U_Actl 1;
BA_ "ECGUsedRxSignal" SG_ 1168 BattTracCell03_U_Actl 1;
BA_ "GenSigStartValue" SG_ 1168 BattTracCell03_U_Actl 4094;
BA_ "GenSigStartValueInteger" SG_ 1168 BattTracCell03_U_Actl 4094;
BA_ "U_CD542_MY2021_Tx" SG_ 1168 BattTracCell02_U_Actl 1;
BA_ "U_CX727_MY2021_Tx" SG_ 1168 BattTracCell02_U_Actl 1;
BA_ "U_U55X_MY2022_Rx" SG_ 1168 BattTracCell02_U_Actl 1;
BA_ "U_CD542_MY2021_Rx" SG_ 1168 BattTracCell02_U_Actl 1;
BA_ "ECGUsedRxSignal" SG_ 1168 BattTracCell02_U_Actl 1;
BA_ "GenSigStartValue" SG_ 1168 BattTracCell02_U_Actl 4094;
BA_ "GenSigStartValueInteger" SG_ 1168 BattTracCell02_U_Actl 4094;
BA_ "U_CD542_MY2021_Tx" SG_ 1168 BattTracCell01_U_Actl 1;
BA_ "U_CX727_MY2021_Tx" SG_ 1168 BattTracCell01_U_Actl 1;
BA_ "U_U55X_MY2022_Rx" SG_ 1168 BattTracCell01_U_Actl 1;
BA_ "U_CD542_MY2021_Rx" SG_ 1168 BattTracCell01_U_Actl 1;
BA_ "ECGUsedRxSignal" SG_ 1168 BattTracCell01_U_Actl 1;
BA_ "GenSigStartValue" SG_ 1168 BattTracCell01_U_Actl 4094;
BA_ "GenSigStartValueInteger" SG_ 1168 BattTracCell01_U_Actl 4094;
BA_ "U_CD542_MY2021_Tx" SG_ 1092 BattTracCell_U_Mx 1;
BA_ "U_CX727_MY2021_Tx" SG_ 1092 BattTracCell_U_Mx 1;
BA_ "U_U55X_MY2022_Rx" SG_ 1092 BattTracCell_U_Mx 1;
BA_ "U_CD542_MY2021_Rx" SG_ 1092 BattTracCell_U_Mx 1;
BA_ "ECGUsedRxSignal" SG_ 1092 BattTracCell_U_Mx 1;
BA_ "U_CD542_MY2021_Tx" SG_ 1092 BattTracMnCell_Te_Actl 1;
BA_ "U_CX727_MY2021_Tx" SG_ 1092 BattTracMnCell_Te_Actl 1;
BA_ "U_U55X_MY2022_Rx" SG_ 1092 BattTracMnCell_Te_Actl 1;
BA_ "U_CD542_MY2021_Rx" SG_ 1092 BattTracMnCell_Te_Actl 1;
BA_ "ECGUsedRxSignal" SG_ 1092 BattTracMnCell_Te_Actl 1;
BA_ "GenSigStartValue" SG_ 1092 BattTracMnCell_Te_Actl 254;
BA_ "GenSigStartValueInteger" SG_ 1092 BattTracMnCell_Te_Actl 254;
BA_ "U_CD542_MY2021_Tx" SG_ 1092 BattTracInsAlrm_B_Stat 1;
BA_ "U_CX727_MY2021_Tx" SG_ 1092 BattTracInsAlrm_B_Stat 1;
BA_ "U_U55X_MY2022_Rx" SG_ 1092 BattTracInsAlrm_B_Stat 1;
BA_ "U_CD542_MY2021_Rx" SG_ 1092 BattTracInsAlrm_B_Stat 1;
BA_ "ECGUsedRxSignal" SG_ 1092 BattTracInsAlrm_B_Stat 1;
BA_ "U_CD542_MY2021_Tx" SG_ 1092 BattTracUMx_B_Stat 1;
BA_ "U_CX727_MY2021_Tx" SG_ 1092 BattTracUMx_B_Stat 1;
BA_ "U_U55X_MY2022_Rx" SG_ 1092 BattTracUMx_B_Stat 1;
BA_ "U_CD542_MY2021_Rx" SG_ 1092 BattTracUMx_B_Stat 1;
BA_ "ECGUsedRxSignal" SG_ 1092 BattTracUMx_B_Stat 1;
BA_ "U_CD542_MY2021_Tx" SG_ 1092 BattTracMxCell_Te_Actl 1;
BA_ "U_CX727_MY2021_Tx" SG_ 1092 BattTracMxCell_Te_Actl 1;
BA_ "U_U55X_MY2022_Rx" SG_ 1092 BattTracMxCell_Te_Actl 1;
BA_ "U_CD542_MY2021_Rx" SG_ 1092 BattTracMxCell_Te_Actl 1;
BA_ "ECGUsedRxSignal" SG_ 1092 BattTracMxCell_Te_Actl 1;
BA_ "GenSigStartValue" SG_ 1092 BattTracMxCell_Te_Actl 254;
BA_ "GenSigStartValueInteger" SG_ 1092 BattTracMxCell_Te_Actl 254;
BA_ "U_CD542_MY2021_Tx" SG_ 1092 BattTracEq_B_Actl 1;
BA_ "U_CX727_MY2021_Tx" SG_ 1092 BattTracEq_B_Actl 1;
BA_ "U_U55X_MY2022_Rx" SG_ 1092 BattTracEq_B_Actl 1;
BA_ "U_CD542_MY2021_Rx" SG_ 1092 BattTracEq_B_Actl 1;
BA_ "ECGUsedRxSignal" SG_ 1092 BattTracEq_B_Actl 1;
BA_ "U_CD542_MY2021_Tx" SG_ 1092 BattTracCell_U_Mn 1;
BA_ "U_CX727_MY2021_Tx" SG_ 1092 BattTracCell_U_Mn 1;
BA_ "U_U55X_MY2022_Rx" SG_ 1092 BattTracCell_U_Mn 1;
BA_ "U_CD542_MY2021_Rx" SG_ 1092 BattTracCell_U_Mn 1;
BA_ "ECGUsedRxSignal" SG_ 1092 BattTracCell_U_Mn 1;
BA_ "U_CD542_MY2021_Tx" SG_ 1092 BattTracUMn_B_Stat 1;
BA_ "U_CX727_MY2021_Tx" SG_ 1092 BattTracUMn_B_Stat 1;
BA_ "U_U55X_MY2022_Rx" SG_ 1092 BattTracUMn_B_Stat 1;
BA_ "U_CD542_MY2021_Rx" SG_ 1092 BattTracUMn_B_Stat 1;
BA_ "ECGUsedRxSignal" SG_ 1092 BattTracUMn_B_Stat 1;
BA_ "U_CD542_MY2021_Tx" SG_ 1092 BattTracUAlrm_B_Stat 1;
BA_ "U_CX727_MY2021_Tx" SG_ 1092 BattTracUAlrm_B_Stat 1;
BA_ "U_U55X_MY2022_Rx" SG_ 1092 BattTracUAlrm_B_Stat 1;
BA_ "U_CD542_MY2021_Rx" SG_ 1092 BattTracUAlrm_B_Stat 1;
BA_ "ECGUsedRxSignal" SG_ 1092 BattTracUAlrm_B_Stat 1;
BA_ "U_CD542_MY2021_Tx" SG_ 1092 BattTracInsltn_R_Actl 1;
BA_ "U_CX727_MY2021_Tx" SG_ 1092 BattTracInsltn_R_Actl 1;
BA_ "U_U55X_MY2022_Rx" SG_ 1092 BattTracInsltn_R_Actl 1;
BA_ "U_CD542_MY2021_Rx" SG_ 1092 BattTracInsltn_R_Actl 1;
BA_ "ECGUsedRxSignal" SG_ 1092 BattTracInsltn_R_Actl 1;
BA_ "GenSigStartValue" SG_ 1092 BattTracInsltn_R_Actl 255;
BA_ "GenSigStartValueInteger" SG_ 1092 BattTracInsltn_R_Actl 255;
BA_ "GenSigStartValueInteger" SG_ 1445 SOBDMC_AutoSarNMReserved4 255;
BA_ "ContentDependant" SG_ 1445 SOBDMC_AutoSarNMReserved4 1;
BA_ "GenSigStartValue" SG_ 1445 SOBDMC_AutoSarNMReserved4 255;
BA_ "U_CX727_MY2021_Rx" SG_ 1445 SOBDMC_AutoSarNMReserved4 1;
BA_ "U_CD542_MY2021_Rx" SG_ 1445 SOBDMC_AutoSarNMReserved4 1;
BA_ "U_CX727_MY2021_Tx" SG_ 1445 SOBDMC_AutoSarNMReserved4 1;
BA_ "U_P702_MY2021_Tx" SG_ 1445 SOBDMC_AutoSarNMReserved4 1;
BA_ "U_CD542_MY2021_Tx" SG_ 1445 SOBDMC_AutoSarNMReserved4 1;
BA_ "GenSigStartValueInteger" SG_ 1445 SOBDMC_AutoSarNMReserved3 255;
BA_ "ContentDependant" SG_ 1445 SOBDMC_AutoSarNMReserved3 1;
BA_ "GenSigStartValue" SG_ 1445 SOBDMC_AutoSarNMReserved3 255;
BA_ "U_CX727_MY2021_Rx" SG_ 1445 SOBDMC_AutoSarNMReserved3 1;
BA_ "U_CD542_MY2021_Rx" SG_ 1445 SOBDMC_AutoSarNMReserved3 1;
BA_ "U_CX727_MY2021_Tx" SG_ 1445 SOBDMC_AutoSarNMReserved3 1;
BA_ "U_P702_MY2021_Tx" SG_ 1445 SOBDMC_AutoSarNMReserved3 1;
BA_ "U_CD542_MY2021_Tx" SG_ 1445 SOBDMC_AutoSarNMReserved3 1;
BA_ "GenSigStartValueInteger" SG_ 1445 SOBDMC_AutoSarNMReserved2 255;
BA_ "ContentDependant" SG_ 1445 SOBDMC_AutoSarNMReserved2 1;
BA_ "GenSigStartValue" SG_ 1445 SOBDMC_AutoSarNMReserved2 255;
BA_ "U_CX727_MY2021_Rx" SG_ 1445 SOBDMC_AutoSarNMReserved2 1;
BA_ "U_CD542_MY2021_Rx" SG_ 1445 SOBDMC_AutoSarNMReserved2 1;
BA_ "U_CX727_MY2021_Tx" SG_ 1445 SOBDMC_AutoSarNMReserved2 1;
BA_ "U_P702_MY2021_Tx" SG_ 1445 SOBDMC_AutoSarNMReserved2 1;
BA_ "U_CD542_MY2021_Tx" SG_ 1445 SOBDMC_AutoSarNMReserved2 1;
BA_ "GenSigStartValueInteger" SG_ 1445 SOBDMC_AutoSarNMReserved1 255;
BA_ "ContentDependant" SG_ 1445 SOBDMC_AutoSarNMReserved1 1;
BA_ "GenSigStartValue" SG_ 1445 SOBDMC_AutoSarNMReserved1 255;
BA_ "U_CX727_MY2021_Rx" SG_ 1445 SOBDMC_AutoSarNMReserved1 1;
BA_ "U_CD542_MY2021_Rx" SG_ 1445 SOBDMC_AutoSarNMReserved1 1;
BA_ "U_CX727_MY2021_Tx" SG_ 1445 SOBDMC_AutoSarNMReserved1 1;
BA_ "U_P702_MY2021_Tx" SG_ 1445 SOBDMC_AutoSarNMReserved1 1;
BA_ "U_CD542_MY2021_Tx" SG_ 1445 SOBDMC_AutoSarNMReserved1 1;
BA_ "GenSigStartValueInteger" SG_ 1445 SOBDMC_AutoSarNMNodeId 165;
BA_ "ContentDependant" SG_ 1445 SOBDMC_AutoSarNMNodeId 1;
BA_ "GenSigStartValue" SG_ 1445 SOBDMC_AutoSarNMNodeId 165;
BA_ "U_CX727_MY2021_Rx" SG_ 1445 SOBDMC_AutoSarNMNodeId 1;
BA_ "U_CD542_MY2021_Rx" SG_ 1445 SOBDMC_AutoSarNMNodeId 1;
BA_ "U_CX727_MY2021_Tx" SG_ 1445 SOBDMC_AutoSarNMNodeId 1;
BA_ "U_P702_MY2021_Tx" SG_ 1445 SOBDMC_AutoSarNMNodeId 1;
BA_ "U_CD542_MY2021_Tx" SG_ 1445 SOBDMC_AutoSarNMNodeId 1;
BA_ "ContentDependant" SG_ 1445 SOBDMC_AutoSarNMControl 1;
BA_ "U_CX727_MY2021_Rx" SG_ 1445 SOBDMC_AutoSarNMControl 1;
BA_ "U_CD542_MY2021_Rx" SG_ 1445 SOBDMC_AutoSarNMControl 1;
BA_ "U_CX727_MY2021_Tx" SG_ 1445 SOBDMC_AutoSarNMControl 1;
BA_ "U_P702_MY2021_Tx" SG_ 1445 SOBDMC_AutoSarNMControl 1;
BA_ "U_CD542_MY2021_Tx" SG_ 1445 SOBDMC_AutoSarNMControl 1;
BA_ "GenSigStartValueInteger" SG_ 1445 SOBDMC_GWOnBoardTester 255;
BA_ "ContentDependant" SG_ 1445 SOBDMC_GWOnBoardTester 1;
BA_ "GenSigStartValue" SG_ 1445 SOBDMC_GWOnBoardTester 255;
BA_ "U_CX727_MY2021_Rx" SG_ 1445 SOBDMC_GWOnBoardTester 1;
BA_ "U_CD542_MY2021_Rx" SG_ 1445 SOBDMC_GWOnBoardTester 1;
BA_ "U_CX727_MY2021_Tx" SG_ 1445 SOBDMC_GWOnBoardTester 1;
BA_ "U_P702_MY2021_Tx" SG_ 1445 SOBDMC_GWOnBoardTester 1;
BA_ "U_CD542_MY2021_Tx" SG_ 1445 SOBDMC_GWOnBoardTester 1;
BA_ "GenSigStartValueInteger" SG_ 1445 SOBDMC_GWNMProxy 255;
BA_ "ContentDependant" SG_ 1445 SOBDMC_GWNMProxy 1;
BA_ "GenSigStartValue" SG_ 1445 SOBDMC_GWNMProxy 255;
BA_ "U_CX727_MY2021_Rx" SG_ 1445 SOBDMC_GWNMProxy 1;
BA_ "U_CD542_MY2021_Rx" SG_ 1445 SOBDMC_GWNMProxy 1;
BA_ "U_CX727_MY2021_Tx" SG_ 1445 SOBDMC_GWNMProxy 1;
BA_ "U_P702_MY2021_Tx" SG_ 1445 SOBDMC_GWNMProxy 1;
BA_ "U_CD542_MY2021_Tx" SG_ 1445 SOBDMC_GWNMProxy 1;
BA_ "GenSigStartValue" SG_ 942 ApaOffOptnSel_B_Avail 1;
BA_ "GenSigStartValue" SG_ 650 BptTglCnt_No_Rq 14;
BA_ "GenSigSendType" SG_ 650 BptTglCnt_No_Rq 3;
BA_ "ECGUsedTxSignal" SG_ 650 BptTglCnt_No_Rq 1;
BA_ "GenSigStartValueInteger" SG_ 650 BptIsol_D_Stat 6;
BA_ "GenSigStartValue" SG_ 650 BptIsol_D_Stat 6;
BA_ "GenSigSendType" SG_ 650 BptIsol_D_Stat 3;
BA_ "ECGUsedTxSignal" SG_ 650 BptIsol_D_Stat 1;
BA_ "GenSigSendType" SG_ 650 Bpt_D_StatEvse 3;
BA_ "ECGUsedTxSignal" SG_ 650 Bpt_D_StatEvse 1;
BA_ "GenSigStartValue" SG_ 650 BptTgl_D_Rq 2;
BA_ "GenSigSendType" SG_ 650 BptTgl_D_Rq 3;
BA_ "ECGUsedTxSignal" SG_ 650 BptTgl_D_Rq 1;
BA_ "GenSigStartValue" SG_ 650 BattTracIsoDis_D_RqBpt 2;
BA_ "GenSigSendType" SG_ 650 BattTracIsoDis_D_RqBpt 3;
BA_ "ECGUsedTxSignal" SG_ 650 BattTracIsoDis_D_RqBpt 1;
BA_ "GenSigStartValue" SG_ 655 EvseChrgOutHi_U_ActlBpt 1022;
BA_ "ECGUsedTxSignal" SG_ 655 EvseChrgOutHi_U_ActlBpt 1;
BA_ "GenSigStartValue" SG_ 655 EvseChrgOutHi_I_ActlBpt 32766;
BA_ "ECGUsedTxSignal" SG_ 655 EvseChrgOutHi_I_ActlBpt 1;
BA_ "GenSigStartValue" SG_ 655 EvseDchrg_Pw_Mx 32766;
BA_ "ECGUsedTxSignal" SG_ 655 EvseDchrg_Pw_Mx 1;
BA_ "GenSigStartValue" SG_ 655 EvseDchrg_I_Mx 32766;
BA_ "ECGUsedTxSignal" SG_ 655 EvseDchrg_I_Mx 1;
BA_ "GenSigSendType" SG_ 599 Bpt_D_StatBattTrac 3;
BA_ "GenSigStartValue" SG_ 528 TireRear_P_OffRoad2 255;
BA_ "GenSigSendType" SG_ 528 TireRear_P_OffRoad2 3;
BA_ "GenSigStartValue" SG_ 528 TireRear_P_OffRoad1 255;
BA_ "GenSigSendType" SG_ 528 TireRear_P_OffRoad1 3;
BA_ "GenSigStartValue" SG_ 528 TireFront_P_OffRoad2 255;
BA_ "GenSigSendType" SG_ 528 TireFront_P_OffRoad2 3;
BA_ "GenSigStartValue" SG_ 528 TireFront_P_OffRoad1 255;
BA_ "GenSigSendType" SG_ 528 TireFront_P_OffRoad1 3;
BA_ "GenSigSendType" SG_ 528 TireInflateMsgTxt_B_Rq 3;
BA_ "GenSigSendType" SG_ 528 OffRoadMde_D_Stat 3;
BA_ "GenSigStartValueInteger" SG_ 955 Tire_Temp_RF_Data 253;
BA_ "GenSigStartValue" SG_ 955 Tire_Temp_RF_Data 253;
BA_ "U_T6_MCA_MY2020_Rx" SG_ 955 Tire_Temp_RF_Data 1;
BA_ "ECGUsedRxSignal" SG_ 955 Tire_Temp_RF_Data 1;
BA_ "U_CD542_MY2021_Rx" SG_ 955 Tire_Temp_RF_Data 1;
BA_ "U_U55X_MY2022_Rx" SG_ 955 Tire_Temp_RF_Data 1;
BA_ "U_CD764_MY2022_Rx" SG_ 955 Tire_Temp_RF_Data 1;
BA_ "U_CX727_MY2021_Tx" SG_ 955 Tire_Temp_RF_Data 1;
BA_ "U_P702_MY2021_Tx" SG_ 955 Tire_Temp_RF_Data 1;
BA_ "U_T6_MCA_MY2020_Tx" SG_ 955 Tire_Temp_RF_Data 1;
BA_ "U_CD542_MY2021_Tx" SG_ 955 Tire_Temp_RF_Data 1;
BA_ "U_U55X_MY2022_Tx" SG_ 955 Tire_Temp_RF_Data 1;
BA_ "U_CD764_MY2022_Tx" SG_ 955 Tire_Temp_RF_Data 1;
BA_ "GenSigStartValueInteger" SG_ 955 Tire_Temp_ORR_Data 253;
BA_ "GenSigStartValue" SG_ 955 Tire_Temp_ORR_Data 253;
BA_ "U_T6_MCA_MY2020_Rx" SG_ 955 Tire_Temp_ORR_Data 1;
BA_ "ECGUsedRxSignal" SG_ 955 Tire_Temp_ORR_Data 1;
BA_ "U_CD542_MY2021_Rx" SG_ 955 Tire_Temp_ORR_Data 1;
BA_ "U_U55X_MY2022_Rx" SG_ 955 Tire_Temp_ORR_Data 1;
BA_ "U_CD764_MY2022_Rx" SG_ 955 Tire_Temp_ORR_Data 1;
BA_ "U_CX727_MY2021_Tx" SG_ 955 Tire_Temp_ORR_Data 1;
BA_ "U_P702_MY2021_Tx" SG_ 955 Tire_Temp_ORR_Data 1;
BA_ "U_T6_MCA_MY2020_Tx" SG_ 955 Tire_Temp_ORR_Data 1;
BA_ "U_CD542_MY2021_Tx" SG_ 955 Tire_Temp_ORR_Data 1;
BA_ "U_U55X_MY2022_Tx" SG_ 955 Tire_Temp_ORR_Data 1;
BA_ "U_CD764_MY2022_Tx" SG_ 955 Tire_Temp_ORR_Data 1;
BA_ "GenSigStartValueInteger" SG_ 955 Tire_Temp_OLR_Data 253;
BA_ "GenSigStartValue" SG_ 955 Tire_Temp_OLR_Data 253;
BA_ "U_T6_MCA_MY2020_Rx" SG_ 955 Tire_Temp_OLR_Data 1;
BA_ "ECGUsedRxSignal" SG_ 955 Tire_Temp_OLR_Data 1;
BA_ "U_CD542_MY2021_Rx" SG_ 955 Tire_Temp_OLR_Data 1;
BA_ "U_U55X_MY2022_Rx" SG_ 955 Tire_Temp_OLR_Data 1;
BA_ "U_CD764_MY2022_Rx" SG_ 955 Tire_Temp_OLR_Data 1;
BA_ "U_CX727_MY2021_Tx" SG_ 955 Tire_Temp_OLR_Data 1;
BA_ "U_P702_MY2021_Tx" SG_ 955 Tire_Temp_OLR_Data 1;
BA_ "U_T6_MCA_MY2020_Tx" SG_ 955 Tire_Temp_OLR_Data 1;
BA_ "U_CD542_MY2021_Tx" SG_ 955 Tire_Temp_OLR_Data 1;
BA_ "U_U55X_MY2022_Tx" SG_ 955 Tire_Temp_OLR_Data 1;
BA_ "U_CD764_MY2022_Tx" SG_ 955 Tire_Temp_OLR_Data 1;
BA_ "GenSigStartValueInteger" SG_ 955 Tire_Temp_LF_Data 253;
BA_ "GenSigStartValue" SG_ 955 Tire_Temp_LF_Data 253;
BA_ "U_T6_MCA_MY2020_Rx" SG_ 955 Tire_Temp_LF_Data 1;
BA_ "ECGUsedRxSignal" SG_ 955 Tire_Temp_LF_Data 1;
BA_ "U_CD542_MY2021_Rx" SG_ 955 Tire_Temp_LF_Data 1;
BA_ "U_U55X_MY2022_Rx" SG_ 955 Tire_Temp_LF_Data 1;
BA_ "U_CD764_MY2022_Rx" SG_ 955 Tire_Temp_LF_Data 1;
BA_ "U_CX727_MY2021_Tx" SG_ 955 Tire_Temp_LF_Data 1;
BA_ "U_P702_MY2021_Tx" SG_ 955 Tire_Temp_LF_Data 1;
BA_ "U_T6_MCA_MY2020_Tx" SG_ 955 Tire_Temp_LF_Data 1;
BA_ "U_CD542_MY2021_Tx" SG_ 955 Tire_Temp_LF_Data 1;
BA_ "U_U55X_MY2022_Tx" SG_ 955 Tire_Temp_LF_Data 1;
BA_ "U_CD764_MY2022_Tx" SG_ 955 Tire_Temp_LF_Data 1;
BA_ "GenSigStartValueInteger" SG_ 955 Tire_Temp_IRR_Data 253;
BA_ "GenSigStartValue" SG_ 955 Tire_Temp_IRR_Data 253;
BA_ "U_T6_MCA_MY2020_Rx" SG_ 955 Tire_Temp_IRR_Data 1;
BA_ "ECGUsedRxSignal" SG_ 955 Tire_Temp_IRR_Data 1;
BA_ "U_CD542_MY2021_Rx" SG_ 955 Tire_Temp_IRR_Data 1;
BA_ "U_U55X_MY2022_Rx" SG_ 955 Tire_Temp_IRR_Data 1;
BA_ "U_CD764_MY2022_Rx" SG_ 955 Tire_Temp_IRR_Data 1;
BA_ "U_CX727_MY2021_Tx" SG_ 955 Tire_Temp_IRR_Data 1;
BA_ "U_P702_MY2021_Tx" SG_ 955 Tire_Temp_IRR_Data 1;
BA_ "U_T6_MCA_MY2020_Tx" SG_ 955 Tire_Temp_IRR_Data 1;
BA_ "U_CD542_MY2021_Tx" SG_ 955 Tire_Temp_IRR_Data 1;
BA_ "U_U55X_MY2022_Tx" SG_ 955 Tire_Temp_IRR_Data 1;
BA_ "U_CD764_MY2022_Tx" SG_ 955 Tire_Temp_IRR_Data 1;
BA_ "GenSigStartValueInteger" SG_ 955 Tire_Temp_ILR_Data 253;
BA_ "GenSigStartValue" SG_ 955 Tire_Temp_ILR_Data 253;
BA_ "U_T6_MCA_MY2020_Rx" SG_ 955 Tire_Temp_ILR_Data 1;
BA_ "ECGUsedRxSignal" SG_ 955 Tire_Temp_ILR_Data 1;
BA_ "U_CD542_MY2021_Rx" SG_ 955 Tire_Temp_ILR_Data 1;
BA_ "U_U55X_MY2022_Rx" SG_ 955 Tire_Temp_ILR_Data 1;
BA_ "U_CD764_MY2022_Rx" SG_ 955 Tire_Temp_ILR_Data 1;
BA_ "U_CX727_MY2021_Tx" SG_ 955 Tire_Temp_ILR_Data 1;
BA_ "U_P702_MY2021_Tx" SG_ 955 Tire_Temp_ILR_Data 1;
BA_ "U_T6_MCA_MY2020_Tx" SG_ 955 Tire_Temp_ILR_Data 1;
BA_ "U_CD542_MY2021_Tx" SG_ 955 Tire_Temp_ILR_Data 1;
BA_ "U_U55X_MY2022_Tx" SG_ 955 Tire_Temp_ILR_Data 1;
BA_ "U_CD764_MY2022_Tx" SG_ 955 Tire_Temp_ILR_Data 1;
BA_ "GenSigSendType" SG_ 749 ChrgrSysFalt18_D_Stat 3;
BA_ "U_CX727_MY2021_Rx" SG_ 749 ChrgrSysFalt18_D_Stat 1;
BA_ "U_CD542_MY2021_Rx" SG_ 749 ChrgrSysFalt18_D_Stat 1;
BA_ "U_CX727_MY2021_Tx" SG_ 749 ChrgrSysFalt18_D_Stat 1;
BA_ "U_CD542_MY2021_Tx" SG_ 749 ChrgrSysFalt18_D_Stat 1;
BA_ "GenSigSendType" SG_ 749 ChrgrSysFalt17_D_Stat 3;
BA_ "U_CX727_MY2021_Rx" SG_ 749 ChrgrSysFalt17_D_Stat 1;
BA_ "U_CD542_MY2021_Rx" SG_ 749 ChrgrSysFalt17_D_Stat 1;
BA_ "U_CX727_MY2021_Tx" SG_ 749 ChrgrSysFalt17_D_Stat 1;
BA_ "U_CD542_MY2021_Tx" SG_ 749 ChrgrSysFalt17_D_Stat 1;
BA_ "GenSigSendType" SG_ 749 ChrgrSysFalt16_D_Stat 3;
BA_ "U_CX727_MY2021_Rx" SG_ 749 ChrgrSysFalt16_D_Stat 1;
BA_ "U_CD542_MY2021_Rx" SG_ 749 ChrgrSysFalt16_D_Stat 1;
BA_ "U_CX727_MY2021_Tx" SG_ 749 ChrgrSysFalt16_D_Stat 1;
BA_ "U_CD542_MY2021_Tx" SG_ 749 ChrgrSysFalt16_D_Stat 1;
BA_ "GenSigSendType" SG_ 749 ChrgrSysFalt15_D_Stat 3;
BA_ "U_CX727_MY2021_Rx" SG_ 749 ChrgrSysFalt15_D_Stat 1;
BA_ "U_CD542_MY2021_Rx" SG_ 749 ChrgrSysFalt15_D_Stat 1;
BA_ "U_CX727_MY2021_Tx" SG_ 749 ChrgrSysFalt15_D_Stat 1;
BA_ "U_CD542_MY2021_Tx" SG_ 749 ChrgrSysFalt15_D_Stat 1;
BA_ "GenSigSendType" SG_ 749 ChrgrSysFalt14_D_Stat 3;
BA_ "U_CX727_MY2021_Rx" SG_ 749 ChrgrSysFalt14_D_Stat 1;
BA_ "U_CD542_MY2021_Rx" SG_ 749 ChrgrSysFalt14_D_Stat 1;
BA_ "U_CX727_MY2021_Tx" SG_ 749 ChrgrSysFalt14_D_Stat 1;
BA_ "U_CD542_MY2021_Tx" SG_ 749 ChrgrSysFalt14_D_Stat 1;
BA_ "GenSigSendType" SG_ 749 ChrgrSysFalt13_D_Stat 3;
BA_ "U_CX727_MY2021_Rx" SG_ 749 ChrgrSysFalt13_D_Stat 1;
BA_ "U_CD542_MY2021_Rx" SG_ 749 ChrgrSysFalt13_D_Stat 1;
BA_ "U_CX727_MY2021_Tx" SG_ 749 ChrgrSysFalt13_D_Stat 1;
BA_ "U_CD542_MY2021_Tx" SG_ 749 ChrgrSysFalt13_D_Stat 1;
BA_ "GenSigSendType" SG_ 749 ChrgrSysFalt12_D_Stat 3;
BA_ "U_CX727_MY2021_Rx" SG_ 749 ChrgrSysFalt12_D_Stat 1;
BA_ "U_CD542_MY2021_Rx" SG_ 749 ChrgrSysFalt12_D_Stat 1;
BA_ "U_CX727_MY2021_Tx" SG_ 749 ChrgrSysFalt12_D_Stat 1;
BA_ "U_CD542_MY2021_Tx" SG_ 749 ChrgrSysFalt12_D_Stat 1;
BA_ "GenSigSendType" SG_ 749 ChrgrSysFalt11_D_Stat 3;
BA_ "U_CX727_MY2021_Rx" SG_ 749 ChrgrSysFalt11_D_Stat 1;
BA_ "U_CD542_MY2021_Rx" SG_ 749 ChrgrSysFalt11_D_Stat 1;
BA_ "U_CX727_MY2021_Tx" SG_ 749 ChrgrSysFalt11_D_Stat 1;
BA_ "U_CD542_MY2021_Tx" SG_ 749 ChrgrSysFalt11_D_Stat 1;
BA_ "GenSigSendType" SG_ 749 ChrgrSysFalt9_D_Stat 3;
BA_ "U_CX727_MY2021_Rx" SG_ 749 ChrgrSysFalt9_D_Stat 1;
BA_ "U_CD542_MY2021_Rx" SG_ 749 ChrgrSysFalt9_D_Stat 1;
BA_ "U_CX727_MY2021_Tx" SG_ 749 ChrgrSysFalt9_D_Stat 1;
BA_ "U_CD542_MY2021_Tx" SG_ 749 ChrgrSysFalt9_D_Stat 1;
BA_ "GenSigSendType" SG_ 749 ChrgrSysFalt8_D_Stat 3;
BA_ "U_CX727_MY2021_Rx" SG_ 749 ChrgrSysFalt8_D_Stat 1;
BA_ "U_CD542_MY2021_Rx" SG_ 749 ChrgrSysFalt8_D_Stat 1;
BA_ "U_CX727_MY2021_Tx" SG_ 749 ChrgrSysFalt8_D_Stat 1;
BA_ "U_CD542_MY2021_Tx" SG_ 749 ChrgrSysFalt8_D_Stat 1;
BA_ "GenSigSendType" SG_ 749 ChrgrSysFalt7_D_Stat 3;
BA_ "U_CX727_MY2021_Rx" SG_ 749 ChrgrSysFalt7_D_Stat 1;
BA_ "U_CD542_MY2021_Rx" SG_ 749 ChrgrSysFalt7_D_Stat 1;
BA_ "U_CX727_MY2021_Tx" SG_ 749 ChrgrSysFalt7_D_Stat 1;
BA_ "U_CD542_MY2021_Tx" SG_ 749 ChrgrSysFalt7_D_Stat 1;
BA_ "GenSigSendType" SG_ 749 ChrgrSysFalt6_D_Stat 3;
BA_ "U_CX727_MY2021_Rx" SG_ 749 ChrgrSysFalt6_D_Stat 1;
BA_ "U_CD542_MY2021_Rx" SG_ 749 ChrgrSysFalt6_D_Stat 1;
BA_ "U_CX727_MY2021_Tx" SG_ 749 ChrgrSysFalt6_D_Stat 1;
BA_ "U_CD542_MY2021_Tx" SG_ 749 ChrgrSysFalt6_D_Stat 1;
BA_ "GenSigSendType" SG_ 749 ChrgrSysFalt5_D_Stat 3;
BA_ "U_CX727_MY2021_Rx" SG_ 749 ChrgrSysFalt5_D_Stat 1;
BA_ "U_CD542_MY2021_Rx" SG_ 749 ChrgrSysFalt5_D_Stat 1;
BA_ "U_CX727_MY2021_Tx" SG_ 749 ChrgrSysFalt5_D_Stat 1;
BA_ "U_CD542_MY2021_Tx" SG_ 749 ChrgrSysFalt5_D_Stat 1;
BA_ "GenSigSendType" SG_ 749 ChrgrSysFalt4_D_Stat 3;
BA_ "U_CX727_MY2021_Rx" SG_ 749 ChrgrSysFalt4_D_Stat 1;
BA_ "U_CD542_MY2021_Rx" SG_ 749 ChrgrSysFalt4_D_Stat 1;
BA_ "U_CX727_MY2021_Tx" SG_ 749 ChrgrSysFalt4_D_Stat 1;
BA_ "U_CD542_MY2021_Tx" SG_ 749 ChrgrSysFalt4_D_Stat 1;
BA_ "GenSigSendType" SG_ 749 ChrgrSysFalt3_D_Stat 3;
BA_ "U_CX727_MY2021_Rx" SG_ 749 ChrgrSysFalt3_D_Stat 1;
BA_ "U_CD542_MY2021_Rx" SG_ 749 ChrgrSysFalt3_D_Stat 1;
BA_ "U_CX727_MY2021_Tx" SG_ 749 ChrgrSysFalt3_D_Stat 1;
BA_ "U_CD542_MY2021_Tx" SG_ 749 ChrgrSysFalt3_D_Stat 1;
BA_ "GenSigSendType" SG_ 749 ChrgrSysFalt2_D_Stat 3;
BA_ "U_CX727_MY2021_Rx" SG_ 749 ChrgrSysFalt2_D_Stat 1;
BA_ "U_CD542_MY2021_Rx" SG_ 749 ChrgrSysFalt2_D_Stat 1;
BA_ "U_CX727_MY2021_Tx" SG_ 749 ChrgrSysFalt2_D_Stat 1;
BA_ "U_CD542_MY2021_Tx" SG_ 749 ChrgrSysFalt2_D_Stat 1;
BA_ "GenSigSendType" SG_ 749 ChrgrSysFalt1_D_Stat 3;
BA_ "U_CX727_MY2021_Rx" SG_ 749 ChrgrSysFalt1_D_Stat 1;
BA_ "U_CD542_MY2021_Rx" SG_ 749 ChrgrSysFalt1_D_Stat 1;
BA_ "U_CD542_MY2021_Tx" SG_ 749 ChrgrSysFalt1_D_Stat 1;
BA_ "GenSigSendType" SG_ 749 ChrgrSysFalt10_D_Stat 3;
BA_ "U_CX727_MY2021_Rx" SG_ 749 ChrgrSysFalt10_D_Stat 1;
BA_ "U_CD542_MY2021_Rx" SG_ 749 ChrgrSysFalt10_D_Stat 1;
BA_ "U_CX727_MY2021_Tx" SG_ 749 ChrgrSysFalt10_D_Stat 1;
BA_ "U_CD542_MY2021_Tx" SG_ 749 ChrgrSysFalt10_D_Stat 1;
BA_ "U_CX727_MY2021_Rx" SG_ 624 PaakAddEraseIndx_No_Rq 1;
BA_ "U_T6_MCA_MY2020_Rx" SG_ 624 PaakAddEraseIndx_No_Rq 1;
BA_ "U_CD542_MY2021_Rx" SG_ 624 PaakAddEraseIndx_No_Rq 1;
BA_ "U_U55X_MY2022_Rx" SG_ 624 PaakAddEraseIndx_No_Rq 1;
BA_ "U_CD764_MY2022_Rx" SG_ 624 PaakAddEraseIndx_No_Rq 1;
BA_ "U_CX727_MY2021_Rx" SG_ 624 PaakAddErase_D_Rq 1;
BA_ "U_T6_MCA_MY2020_Rx" SG_ 624 PaakAddErase_D_Rq 1;
BA_ "U_CD542_MY2021_Rx" SG_ 624 PaakAddErase_D_Rq 1;
BA_ "U_U55X_MY2022_Rx" SG_ 624 PaakAddErase_D_Rq 1;
BA_ "U_CD764_MY2022_Rx" SG_ 624 PaakAddErase_D_Rq 1;
BA_ "GenSigSendType" SG_ 580 BattTracVrtOck_B_Rq 3;
BA_ "GenSigSendType" SG_ 622 FobCtlType_D_Stat 3;
BA_ "U_CX727_MY2021_Tx" SG_ 622 FobCtlType_D_Stat 1;
BA_ "U_P702_MY2021_Tx" SG_ 622 FobCtlType_D_Stat 1;
BA_ "U_T6_MCA_MY2020_Tx" SG_ 622 FobCtlType_D_Stat 1;
BA_ "U_CD542_MY2021_Tx" SG_ 622 FobCtlType_D_Stat 1;
BA_ "U_U55X_MY2022_Tx" SG_ 622 FobCtlType_D_Stat 1;
BA_ "U_CD764_MY2022_Tx" SG_ 622 FobCtlType_D_Stat 1;
BA_ "GenSigSendType" SG_ 622 FobCtlRollCode_No_Stat 3;
BA_ "U_CX727_MY2021_Tx" SG_ 622 FobCtlRollCode_No_Stat 1;
BA_ "U_P702_MY2021_Tx" SG_ 622 FobCtlRollCode_No_Stat 1;
BA_ "U_T6_MCA_MY2020_Tx" SG_ 622 FobCtlRollCode_No_Stat 1;
BA_ "U_CD542_MY2021_Tx" SG_ 622 FobCtlRollCode_No_Stat 1;
BA_ "U_U55X_MY2022_Tx" SG_ 622 FobCtlRollCode_No_Stat 1;
BA_ "U_CD764_MY2022_Tx" SG_ 622 FobCtlRollCode_No_Stat 1;
BA_ "GenSigSendType" SG_ 622 FobCtlPssvData_No_Actl 3;
BA_ "U_CX727_MY2021_Tx" SG_ 622 FobCtlPssvData_No_Actl 1;
BA_ "U_P702_MY2021_Tx" SG_ 622 FobCtlPssvData_No_Actl 1;
BA_ "U_T6_MCA_MY2020_Tx" SG_ 622 FobCtlPssvData_No_Actl 1;
BA_ "U_CD542_MY2021_Tx" SG_ 622 FobCtlPssvData_No_Actl 1;
BA_ "U_U55X_MY2022_Tx" SG_ 622 FobCtlPssvData_No_Actl 1;
BA_ "U_CD764_MY2022_Tx" SG_ 622 FobCtlPssvData_No_Actl 1;
BA_ "GenSigStartValueInteger" SG_ 1050 ActvDrvMde_D2_Stat 31;
BA_ "GenSigStartValue" SG_ 1050 ActvDrvMde_D2_Stat 31;
BA_ "GenSigSendType" SG_ 1050 ActvDrvMde_D2_Stat 3;
BA_ "U_CD764_MY2022_Rx" SG_ 1050 PtWakeupActv4_B_Rq_UB 1;
BA_ "WakeupSignal" SG_ 1050 PtWakeupActv4_B_Rq 1;
BA_ "GenSigSendType" SG_ 1050 PtWakeupActv4_B_Rq 3;
BA_ "U_CD764_MY2022_Rx" SG_ 1050 PtWakeupActv4_B_Rq 1;
BA_ "GenSigSendType" SG_ 1050 ModemReset_D_Rq 3;
BA_ "GenSigStartValueInteger" SG_ 1050 SelDrvMdeAwd_D_Rq 31;
BA_ "GenSigStartValue" SG_ 1050 SelDrvMdeAwd_D_Rq 31;
BA_ "GenSigSendType" SG_ 1050 SelDrvMdeAwd_D_Rq 3;
BA_ "U_CX727_MY2021_Rx" SG_ 1050 DrLckCnt_No_ActlTgate_UB 1;
BA_ "U_P702_MY2021_Rx" SG_ 1050 DrLckCnt_No_ActlTgate_UB 1;
BA_ "U_T6_MCA_MY2020_Rx" SG_ 1050 DrLckCnt_No_ActlTgate_UB 1;
BA_ "U_CD542_MY2021_Rx" SG_ 1050 DrLckCnt_No_ActlTgate_UB 1;
BA_ "U_U55X_MY2022_Rx" SG_ 1050 DrLckCnt_No_ActlTgate_UB 1;
BA_ "U_CD764_MY2022_Rx" SG_ 1050 DrLckCnt_No_ActlTgate_UB 1;
BA_ "WakeupSignal" SG_ 1050 DrLckCnt_No_ActlTgate 1;
BA_ "U_CX727_MY2021_Rx" SG_ 1050 DrLckCnt_No_ActlTgate 1;
BA_ "U_P702_MY2021_Rx" SG_ 1050 DrLckCnt_No_ActlTgate 1;
BA_ "U_T6_MCA_MY2020_Rx" SG_ 1050 DrLckCnt_No_ActlTgate 1;
BA_ "U_CD542_MY2021_Rx" SG_ 1050 DrLckCnt_No_ActlTgate 1;
BA_ "U_U55X_MY2022_Rx" SG_ 1050 DrLckCnt_No_ActlTgate 1;
BA_ "U_CD764_MY2022_Rx" SG_ 1050 DrLckCnt_No_ActlTgate 1;
BA_ "GenSigSendType" SG_ 1050 TelematicsSrvc_D_St 3;
BA_ "GenSigSendType" SG_ 1050 FactoryReset_Rq 3;
BA_ "U_U55X_MY2022_Rx" SG_ 1050 TurnLampFrOut_B_Stat_UB 1;
BA_ "U_CD764_MY2022_Rx" SG_ 1050 TurnLampFrOut_B_Stat_UB 1;
BA_ "U_U55X_MY2022_Rx" SG_ 1050 TurnLampFlOut_B_Stat_UB 1;
BA_ "U_CD764_MY2022_Rx" SG_ 1050 TurnLampFlOut_B_Stat_UB 1;
BA_ "GenSigSendType" SG_ 1050 TurnLampFrOut_B_Stat 3;
BA_ "U_U55X_MY2022_Rx" SG_ 1050 TurnLampFrOut_B_Stat 1;
BA_ "U_CD764_MY2022_Rx" SG_ 1050 TurnLampFrOut_B_Stat 1;
BA_ "GenSigSendType" SG_ 1050 TurnLampFlOut_B_Stat 3;
BA_ "U_U55X_MY2022_Rx" SG_ 1050 TurnLampFlOut_B_Stat 1;
BA_ "U_CD764_MY2022_Rx" SG_ 1050 TurnLampFlOut_B_Stat 1;
BA_ "U_CD542_MY2021_Rx" SG_ 1050 TrunkFrontRolCd_No_Locl_UB 1;
BA_ "U_U55X_MY2022_Rx" SG_ 1050 TrunkFrontRolCd_No_Locl_UB 1;
BA_ "U_CD764_MY2022_Rx" SG_ 1050 TrunkFrontRolCd_No_Locl_UB 1;
BA_ "WakeupSignal" SG_ 1050 TrunkFrontRolCd_No_Locl 1;
BA_ "GenSigSendType" SG_ 1050 TrunkFrontRolCd_No_Locl 3;
BA_ "U_CD542_MY2021_Rx" SG_ 1050 TrunkFrontRolCd_No_Locl 1;
BA_ "U_U55X_MY2022_Rx" SG_ 1050 TrunkFrontRolCd_No_Locl 1;
BA_ "U_CD764_MY2022_Rx" SG_ 1050 TrunkFrontRolCd_No_Locl 1;
BA_ "GenSigSendType" SG_ 1050 SelDrvMdeHmi03_D_Rq 3;
BA_ "U_CD542_MY2021_Rx" SG_ 1050 SelDrvMdeHmi03_D_Rq 1;
BA_ "U_CD764_MY2022_Rx" SG_ 1050 SelDrvMdeHmi03_D_Rq 1;
BA_ "U_CD542_MY2021_Rx" SG_ 1050 SelDrvMdeHmi03_D_Rq_UB 1;
BA_ "U_CD764_MY2022_Rx" SG_ 1050 SelDrvMdeHmi03_D_Rq_UB 1;
BA_ "GenSigSendType" SG_ 1217 PrkAidSwtch_D_RqMnu 3;
BA_ "GenSigSendType" SG_ 1217 ApaSwtch_D_RqMnu 3;
BA_ "GenSigStartValueInteger" SG_ 1217 StopStrtVThres_D_RqMnu 1;
BA_ "GenSigStartValue" SG_ 1217 StopStrtVThres_D_RqMnu 1;
BA_ "GenSigSendType" SG_ 1217 StopStrtVThres_D_RqMnu 3;
BA_ "U_P702_MY2021_Rx" SG_ 1217 SldrrUnlckSwtch_D_Stat_UB 1;
BA_ "U_T6_MCA_MY2020_Rx" SG_ 1217 SldrrUnlckSwtch_D_Stat_UB 1;
BA_ "U_U55X_MY2022_Rx" SG_ 1217 SldrrUnlckSwtch_D_Stat_UB 1;
BA_ "U_P702_MY2021_Rx" SG_ 1217 SldrrUnlckRollCd_No_Cnt_UB 1;
BA_ "U_T6_MCA_MY2020_Rx" SG_ 1217 SldrrUnlckRollCd_No_Cnt_UB 1;
BA_ "U_U55X_MY2022_Rx" SG_ 1217 SldrrUnlckRollCd_No_Cnt_UB 1;
BA_ "U_P702_MY2021_Rx" SG_ 1217 SldrrUnlck_No_Cnt_UB 1;
BA_ "U_T6_MCA_MY2020_Rx" SG_ 1217 SldrrUnlck_No_Cnt_UB 1;
BA_ "U_U55X_MY2022_Rx" SG_ 1217 SldrrUnlck_No_Cnt_UB 1;
BA_ "U_P702_MY2021_Rx" SG_ 1217 SldrrChildLck_No_Cnt_UB 1;
BA_ "U_T6_MCA_MY2020_Rx" SG_ 1217 SldrrChildLck_No_Cnt_UB 1;
BA_ "U_U55X_MY2022_Rx" SG_ 1217 SldrrChildLck_No_Cnt_UB 1;
BA_ "U_P702_MY2021_Rx" SG_ 1217 Sldrr_D_Stat_UB 1;
BA_ "U_T6_MCA_MY2020_Rx" SG_ 1217 Sldrr_D_Stat_UB 1;
BA_ "U_U55X_MY2022_Rx" SG_ 1217 Sldrr_D_Stat_UB 1;
BA_ "GenSigSendType" SG_ 1217 SldrrUnlckSwtch_D_Stat 3;
BA_ "U_P702_MY2021_Rx" SG_ 1217 SldrrUnlckSwtch_D_Stat 1;
BA_ "U_T6_MCA_MY2020_Rx" SG_ 1217 SldrrUnlckSwtch_D_Stat 1;
BA_ "U_U55X_MY2022_Rx" SG_ 1217 SldrrUnlckSwtch_D_Stat 1;
BA_ "GenSigSendType" SG_ 1217 SldrrUnlckRollCd_No_Cnt 3;
BA_ "U_P702_MY2021_Rx" SG_ 1217 SldrrUnlckRollCd_No_Cnt 1;
BA_ "U_T6_MCA_MY2020_Rx" SG_ 1217 SldrrUnlckRollCd_No_Cnt 1;
BA_ "U_U55X_MY2022_Rx" SG_ 1217 SldrrUnlckRollCd_No_Cnt 1;
BA_ "WakeupSignal" SG_ 1217 SldrrUnlck_No_Cnt 1;
BA_ "GenSigSendType" SG_ 1217 SldrrUnlck_No_Cnt 3;
BA_ "U_P702_MY2021_Rx" SG_ 1217 SldrrUnlck_No_Cnt 1;
BA_ "U_T6_MCA_MY2020_Rx" SG_ 1217 SldrrUnlck_No_Cnt 1;
BA_ "U_U55X_MY2022_Rx" SG_ 1217 SldrrUnlck_No_Cnt 1;
BA_ "WakeupSignal" SG_ 1217 SldrrChildLck_No_Cnt 1;
BA_ "GenSigSendType" SG_ 1217 SldrrChildLck_No_Cnt 3;
BA_ "U_P702_MY2021_Rx" SG_ 1217 SldrrChildLck_No_Cnt 1;
BA_ "U_T6_MCA_MY2020_Rx" SG_ 1217 SldrrChildLck_No_Cnt 1;
BA_ "U_U55X_MY2022_Rx" SG_ 1217 SldrrChildLck_No_Cnt 1;
BA_ "WakeupSignal" SG_ 1217 Sldrr_D_Stat 1;
BA_ "GenSigSendType" SG_ 1217 Sldrr_D_Stat 3;
BA_ "U_P702_MY2021_Rx" SG_ 1217 Sldrr_D_Stat 1;
BA_ "U_T6_MCA_MY2020_Rx" SG_ 1217 Sldrr_D_Stat 1;
BA_ "U_U55X_MY2022_Rx" SG_ 1217 Sldrr_D_Stat 1;
BA_ "U_P702_MY2021_Rx" SG_ 1216 Sldrl_D_Stat_UB 1;
BA_ "U_T6_MCA_MY2020_Rx" SG_ 1216 Sldrl_D_Stat_UB 1;
BA_ "U_U55X_MY2022_Rx" SG_ 1216 Sldrl_D_Stat_UB 1;
BA_ "WakeupSignal" SG_ 1216 Sldrl_D_Stat 1;
BA_ "GenSigSendType" SG_ 1216 Sldrl_D_Stat 3;
BA_ "U_P702_MY2021_Rx" SG_ 1216 Sldrl_D_Stat 1;
BA_ "U_T6_MCA_MY2020_Rx" SG_ 1216 Sldrl_D_Stat 1;
BA_ "U_U55X_MY2022_Rx" SG_ 1216 Sldrl_D_Stat 1;
BA_ "U_P702_MY2021_Rx" SG_ 1216 SldrlUnlck_No_Cnt_UB 1;
BA_ "U_T6_MCA_MY2020_Rx" SG_ 1216 SldrlUnlck_No_Cnt_UB 1;
BA_ "U_U55X_MY2022_Rx" SG_ 1216 SldrlUnlck_No_Cnt_UB 1;
BA_ "WakeupSignal" SG_ 1216 SldrlUnlck_No_Cnt 1;
BA_ "GenSigSendType" SG_ 1216 SldrlUnlck_No_Cnt 3;
BA_ "U_P702_MY2021_Rx" SG_ 1216 SldrlUnlck_No_Cnt 1;
BA_ "U_T6_MCA_MY2020_Rx" SG_ 1216 SldrlUnlck_No_Cnt 1;
BA_ "U_U55X_MY2022_Rx" SG_ 1216 SldrlUnlck_No_Cnt 1;
BA_ "U_P702_MY2021_Rx" SG_ 1216 SldrlUnlckSwtch_D_Stat_UB 1;
BA_ "U_T6_MCA_MY2020_Rx" SG_ 1216 SldrlUnlckSwtch_D_Stat_UB 1;
BA_ "U_U55X_MY2022_Rx" SG_ 1216 SldrlUnlckSwtch_D_Stat_UB 1;
BA_ "GenSigSendType" SG_ 1216 SldrlUnlckSwtch_D_Stat 3;
BA_ "U_P702_MY2021_Rx" SG_ 1216 SldrlUnlckSwtch_D_Stat 1;
BA_ "U_T6_MCA_MY2020_Rx" SG_ 1216 SldrlUnlckSwtch_D_Stat 1;
BA_ "U_U55X_MY2022_Rx" SG_ 1216 SldrlUnlckSwtch_D_Stat 1;
BA_ "U_P702_MY2021_Rx" SG_ 1216 SldrlUnlckRollCd_No_Cnt_UB 1;
BA_ "U_T6_MCA_MY2020_Rx" SG_ 1216 SldrlUnlckRollCd_No_Cnt_UB 1;
BA_ "U_U55X_MY2022_Rx" SG_ 1216 SldrlUnlckRollCd_No_Cnt_UB 1;
BA_ "GenSigSendType" SG_ 1216 SldrlUnlckRollCd_No_Cnt 3;
BA_ "U_P702_MY2021_Rx" SG_ 1216 SldrlUnlckRollCd_No_Cnt 1;
BA_ "U_T6_MCA_MY2020_Rx" SG_ 1216 SldrlUnlckRollCd_No_Cnt 1;
BA_ "U_U55X_MY2022_Rx" SG_ 1216 SldrlUnlckRollCd_No_Cnt 1;
BA_ "U_P702_MY2021_Rx" SG_ 1216 SldrlChildLck_No_Cnt_UB 1;
BA_ "U_T6_MCA_MY2020_Rx" SG_ 1216 SldrlChildLck_No_Cnt_UB 1;
BA_ "U_U55X_MY2022_Rx" SG_ 1216 SldrlChildLck_No_Cnt_UB 1;
BA_ "WakeupSignal" SG_ 1216 SldrlChildLck_No_Cnt 1;
BA_ "GenSigSendType" SG_ 1216 SldrlChildLck_No_Cnt 3;
BA_ "U_P702_MY2021_Rx" SG_ 1216 SldrlChildLck_No_Cnt 1;
BA_ "U_T6_MCA_MY2020_Rx" SG_ 1216 SldrlChildLck_No_Cnt 1;
BA_ "U_U55X_MY2022_Rx" SG_ 1216 SldrlChildLck_No_Cnt 1;
BA_ "U_T6_MCA_MY2020_Rx" SG_ 1216 OCSSensrDataUpperLim_UB 1;
BA_ "U_U55X_MY2022_Rx" SG_ 1216 OCSSensrDataUpperLim_UB 1;
BA_ "GenSigSendType" SG_ 1216 OCSSensrDataUpperLim 3;
BA_ "U_T6_MCA_MY2020_Rx" SG_ 1216 OCSSensrDataUpperLim 1;
BA_ "U_U55X_MY2022_Rx" SG_ 1216 OCSSensrDataUpperLim 1;
BA_ "U_T6_MCA_MY2020_Rx" SG_ 1216 OCSSensrDataLowerLim_UB 1;
BA_ "U_U55X_MY2022_Rx" SG_ 1216 OCSSensrDataLowerLim_UB 1;
BA_ "GenSigSendType" SG_ 1216 OCSSensrDataLowerLim 3;
BA_ "U_T6_MCA_MY2020_Rx" SG_ 1216 OCSSensrDataLowerLim 1;
BA_ "U_U55X_MY2022_Rx" SG_ 1216 OCSSensrDataLowerLim 1;
BA_ "GenSigStartValueInteger" SG_ 1087 DcacFaltMsgTxt_D2_Rq 1;
BA_ "U_U55X_MY2022_Rx" SG_ 1087 BtsiShifInhbt_B_RqPt 1;
BA_ "U_T6_MCA_MY2020_Rx" SG_ 1087 IgnOffInhbt_B_Stat 1;
BA_ "U_U55X_MY2022_Rx" SG_ 1087 IgnOffInhbt_B_Stat 1;
BA_ "U_U55X_MY2022_Rx" SG_ 1087 FapLcActv_B_Stat 1;
BA_ "U_T6_MCA_MY2020_Rx" SG_ 1087 BattRgenLoDChrg_D_RqEng 1;
BA_ "U_U55X_MY2022_Rx" SG_ 1087 BattRgenLoDChrg_D_RqEng 1;
BA_ "U_T6_MCA_MY2020_Rx" SG_ 1087 BattRgenLoChrg_D_RqEng 1;
BA_ "U_U55X_MY2022_Rx" SG_ 1087 BattRgenLoChrg_D_RqEng 1;
BA_ "ContentDependant" SG_ 562 OnePdlDrvDStat_No_Cnt 1;
BA_ "MetaData" SG_ 562 OnePdlDrvDStat_No_Cnt 1;
BA_ "ContentDependant" SG_ 562 OnePdlDrvDStat_No_Cs 1;
BA_ "MetaData" SG_ 562 OnePdlDrvDStat_No_Cs 1;
BA_ "ContentDependant" SG_ 562 GearNtrl_No_Cs 1;
BA_ "MetaData" SG_ 562 GearNtrl_No_Cs 1;
BA_ "U_T6_MCA_MY2020_Rx" SG_ 562 GearNtrl_No_Cs 1;
BA_ "ContentDependant" SG_ 562 GearNtrl_No_Cnt 1;
BA_ "MetaData" SG_ 562 GearNtrl_No_Cnt 1;
BA_ "U_T6_MCA_MY2020_Rx" SG_ 562 GearNtrl_No_Cnt 1;
BA_ "GenSigStartValueInteger" SG_ 562 GearNtrl_D_Stat 2;
BA_ "GenSigStartValue" SG_ 562 GearNtrl_D_Stat 2;
BA_ "U_T6_MCA_MY2020_Rx" SG_ 562 GearNtrl_D_Stat 1;
BA_ "U_CX727_MY2021_Rx" SG_ 533 PaakMyKey_D_Rq 1;
BA_ "U_T6_MCA_MY2020_Rx" SG_ 533 PaakMyKey_D_Rq 1;
BA_ "U_CD542_MY2021_Rx" SG_ 533 PaakMyKey_D_Rq 1;
BA_ "U_U55X_MY2022_Rx" SG_ 533 PaakMyKey_D_Rq 1;
BA_ "U_CD764_MY2022_Rx" SG_ 533 PaakMyKey_D_Rq 1;
BA_ "GenSigStartValueInteger" SG_ 533 OnbChrgGoTOn_D_Rq 2;
BA_ "GenSigStartValue" SG_ 533 OnbChrgGoTOn_D_Rq 2;
BA_ "GenSigStartValueInteger" SG_ 533 OnbChrgGoTHr_T_Rq 30;
BA_ "GenSigStartValue" SG_ 533 OnbChrgGoTHr_T_Rq 30;
BA_ "WakeupSignal" SG_ 533 LghtAmbDrvMde_D_Rq 1;
BA_ "U_CD542_MY2021_Rx" SG_ 533 LghtAmbDrvMde_D_Rq 1;
BA_ "U_CD764_MY2022_Rx" SG_ 533 LghtAmbDrvMde_D_Rq 1;
BA_ "GenSigStartValueInteger" SG_ 1012 ChrgLocLongFrct_An_Sav 1048575;
BA_ "GenSigStartValue" SG_ 1012 ChrgLocLongFrct_An_Sav 1048575;
BA_ "GenSigStartValueInteger" SG_ 1012 ChrgLocLattFrct_An_Sav 1048575;
BA_ "GenSigStartValue" SG_ 1012 ChrgLocLattFrct_An_Sav 1048575;
BA_ "U_CX727_MY2021_Rx" SG_ 1012 ChrgNowCurnt_B_Dsply 1;
BA_ "U_CD542_MY2021_Rx" SG_ 1012 ChrgNowCurnt_B_Dsply 1;
BA_ "GenSigSendType" SG_ 874 BattTracShrtGrnd_D_Falt 3;
BA_ "U_P702_MY2021_Tx" SG_ 874 BattTracShrtGrnd_D_Falt 1;
BA_ "U_CD542_MY2021_Tx" SG_ 874 BattTracShrtGrnd_D_Falt 1;
BA_ "U_U55X_MY2022_Tx" SG_ 874 BattTracShrtGrnd_D_Falt 1;
BA_ "GenSigSendType" SG_ 874 BattTracShrtBatt_D_Falt 3;
BA_ "U_P702_MY2021_Tx" SG_ 874 BattTracShrtBatt_D_Falt 1;
BA_ "U_CD542_MY2021_Tx" SG_ 874 BattTracShrtBatt_D_Falt 1;
BA_ "U_U55X_MY2022_Tx" SG_ 874 BattTracShrtBatt_D_Falt 1;
BA_ "GenSigSendType" SG_ 874 BattTracOpnCirct_D_Falt 3;
BA_ "U_P702_MY2021_Tx" SG_ 874 BattTracOpnCirct_D_Falt 1;
BA_ "U_CD542_MY2021_Tx" SG_ 874 BattTracOpnCirct_D_Falt 1;
BA_ "U_U55X_MY2022_Tx" SG_ 874 BattTracOpnCirct_D_Falt 1;
BA_ "GenSigSendType" SG_ 874 BattTracLifeLim_D_Falt 3;
BA_ "U_P702_MY2021_Tx" SG_ 874 BattTracLifeLim_D_Falt 1;
BA_ "U_CD542_MY2021_Tx" SG_ 874 BattTracLifeLim_D_Falt 1;
BA_ "U_U55X_MY2022_Tx" SG_ 874 BattTracLifeLim_D_Falt 1;
BA_ "GenSigSendType" SG_ 874 BattChlrShrtGrnd_D_Falt 3;
BA_ "U_CX727_MY2021_Tx" SG_ 874 BattChlrShrtGrnd_D_Falt 1;
BA_ "U_P702_MY2021_Tx" SG_ 874 BattChlrShrtGrnd_D_Falt 1;
BA_ "U_CD542_MY2021_Tx" SG_ 874 BattChlrShrtGrnd_D_Falt 1;
BA_ "U_U55X_MY2022_Tx" SG_ 874 BattChlrShrtGrnd_D_Falt 1;
BA_ "GenSigSendType" SG_ 874 BattChlrShrtBatt_D_Falt 3;
BA_ "U_CX727_MY2021_Tx" SG_ 874 BattChlrShrtBatt_D_Falt 1;
BA_ "U_P702_MY2021_Tx" SG_ 874 BattChlrShrtBatt_D_Falt 1;
BA_ "U_CD542_MY2021_Tx" SG_ 874 BattChlrShrtBatt_D_Falt 1;
BA_ "U_U55X_MY2022_Tx" SG_ 874 BattChlrShrtBatt_D_Falt 1;
BA_ "GenSigSendType" SG_ 874 BattChlrOpnCirct_D_Falt 3;
BA_ "U_CX727_MY2021_Tx" SG_ 874 BattChlrOpnCirct_D_Falt 1;
BA_ "U_P702_MY2021_Tx" SG_ 874 BattChlrOpnCirct_D_Falt 1;
BA_ "U_CD542_MY2021_Tx" SG_ 874 BattChlrOpnCirct_D_Falt 1;
BA_ "U_U55X_MY2022_Tx" SG_ 874 BattChlrOpnCirct_D_Falt 1;
BA_ "GenSigSendType" SG_ 874 BattChlrLifeLim_D_Falt 3;
BA_ "U_CX727_MY2021_Tx" SG_ 874 BattChlrLifeLim_D_Falt 1;
BA_ "U_P702_MY2021_Tx" SG_ 874 BattChlrLifeLim_D_Falt 1;
BA_ "U_CD542_MY2021_Tx" SG_ 874 BattChlrLifeLim_D_Falt 1;
BA_ "U_U55X_MY2022_Tx" SG_ 874 BattChlrLifeLim_D_Falt 1;
BA_ "GenSigSendType" SG_ 874 BattTracLow_D_Falt 3;
BA_ "U_P702_MY2021_Tx" SG_ 874 BattTracLow_D_Falt 1;
BA_ "U_CD542_MY2021_Tx" SG_ 874 BattTracLow_D_Falt 1;
BA_ "U_U55X_MY2022_Tx" SG_ 874 BattTracLow_D_Falt 1;
BA_ "GenSigSendType" SG_ 912 GearPrkMtr_D_Stat 3;
BA_ "U_CX727_MY2021_Tx" SG_ 912 GearPrkMtr_D_Stat 1;
BA_ "U_CD542_MY2021_Tx" SG_ 912 GearPrkMtr_D_Stat 1;
BA_ "GenSigSendType" SG_ 912 GearPrkLck_D_Stat 3;
BA_ "U_CX727_MY2021_Tx" SG_ 912 GearPrkLck_D_Stat 1;
BA_ "U_CD542_MY2021_Tx" SG_ 912 GearPrkLck_D_Stat 1;
BA_ "GenSigSendType" SG_ 912 CabnEvapSovFront_D_Stat 3;
BA_ "U_CX727_MY2021_Tx" SG_ 912 CabnEvapSovFront_D_Stat 1;
BA_ "U_P702_MY2021_Tx" SG_ 912 CabnEvapSovFront_D_Stat 1;
BA_ "U_CD542_MY2021_Tx" SG_ 912 CabnEvapSovFront_D_Stat 1;
BA_ "U_U55X_MY2022_Tx" SG_ 912 CabnEvapSovFront_D_Stat 1;
BA_ "GenSigSendType" SG_ 912 BattChlrSov_D_Stat 3;
BA_ "U_CX727_MY2021_Tx" SG_ 912 BattChlrSov_D_Stat 1;
BA_ "U_P702_MY2021_Tx" SG_ 912 BattChlrSov_D_Stat 1;
BA_ "U_CD542_MY2021_Tx" SG_ 912 BattChlrSov_D_Stat 1;
BA_ "U_U55X_MY2022_Tx" SG_ 912 BattChlrSov_D_Stat 1;
BA_ "GenSigSendType" SG_ 912 BattTracClntVlv_D_Stat 3;
BA_ "U_P702_MY2021_Tx" SG_ 912 BattTracClntVlv_D_Stat 1;
BA_ "U_CD542_MY2021_Tx" SG_ 912 BattTracClntVlv_D_Stat 1;
BA_ "U_U55X_MY2022_Tx" SG_ 912 BattTracClntVlv_D_Stat 1;
BA_ "U_T6_MCA_MY2020_Rx" SG_ 931 VehOnSrc_D_Stat 1;
BA_ "U_U55X_MY2022_Rx" SG_ 931 VehOnSrc_D_Stat 1;
BA_ "U_CD764_MY2022_Rx" SG_ 931 VehOnSrc_D_Stat 1;
BA_ "U_P702_MY2021_Tx" SG_ 931 VehOnSrc_D_Stat 1;
BA_ "U_T6_MCA_MY2020_Tx" SG_ 931 VehOnSrc_D_Stat 1;
BA_ "U_CD542_MY2021_Tx" SG_ 931 VehOnSrc_D_Stat 1;
BA_ "U_U55X_MY2022_Tx" SG_ 931 VehOnSrc_D_Stat 1;
BA_ "U_CD764_MY2022_Tx" SG_ 931 VehOnSrc_D_Stat 1;
BA_ "MetaData" SG_ 931 StrtrMtrCtlDStat_No_Cs 1;
BA_ "U_P702_MY2021_Tx" SG_ 931 StrtrMtrCtlDStat_No_Cs 1;
BA_ "U_T6_MCA_MY2020_Tx" SG_ 931 StrtrMtrCtlDStat_No_Cs 1;
BA_ "U_CD542_MY2021_Tx" SG_ 931 StrtrMtrCtlDStat_No_Cs 1;
BA_ "U_U55X_MY2022_Tx" SG_ 931 StrtrMtrCtlDStat_No_Cs 1;
BA_ "U_CD764_MY2022_Tx" SG_ 931 StrtrMtrCtlDStat_No_Cs 1;
BA_ "U_P702_MY2021_Tx" SG_ 931 EngStrtActv_B_Stat 1;
BA_ "U_T6_MCA_MY2020_Tx" SG_ 931 EngStrtActv_B_Stat 1;
BA_ "U_CD542_MY2021_Tx" SG_ 931 EngStrtActv_B_Stat 1;
BA_ "U_U55X_MY2022_Tx" SG_ 931 EngStrtActv_B_Stat 1;
BA_ "U_CD764_MY2022_Tx" SG_ 931 EngStrtActv_B_Stat 1;
BA_ "U_P702_MY2021_Tx" SG_ 931 EngStrt_B_Rq 1;
BA_ "U_T6_MCA_MY2020_Tx" SG_ 931 EngStrt_B_Rq 1;
BA_ "U_CD542_MY2021_Tx" SG_ 931 EngStrt_B_Rq 1;
BA_ "U_U55X_MY2022_Tx" SG_ 931 EngStrt_B_Rq 1;
BA_ "U_CD764_MY2022_Tx" SG_ 931 EngStrt_B_Rq 1;
BA_ "U_P702_MY2021_Tx" SG_ 931 DrvInCtl_B_Stat 1;
BA_ "U_T6_MCA_MY2020_Tx" SG_ 931 DrvInCtl_B_Stat 1;
BA_ "U_CD542_MY2021_Tx" SG_ 931 DrvInCtl_B_Stat 1;
BA_ "U_U55X_MY2022_Tx" SG_ 931 DrvInCtl_B_Stat 1;
BA_ "U_CD764_MY2022_Tx" SG_ 931 DrvInCtl_B_Stat 1;
BA_ "GenSigSendType" SG_ 931 PtWakeReas_D_Stat 3;
BA_ "U_P702_MY2021_Tx" SG_ 931 PtWakeReas_D_Stat 1;
BA_ "U_T6_MCA_MY2020_Tx" SG_ 931 PtWakeReas_D_Stat 1;
BA_ "U_CD542_MY2021_Tx" SG_ 931 PtWakeReas_D_Stat 1;
BA_ "U_U55X_MY2022_Tx" SG_ 931 PtWakeReas_D_Stat 1;
BA_ "U_CD764_MY2022_Tx" SG_ 931 PtWakeReas_D_Stat 1;
BA_ "ContentDependant" SG_ 931 CrnkInhbt_No_Cs 1;
BA_ "MetaData" SG_ 931 CrnkInhbt_No_Cs 1;
BA_ "U_CX727_MY2021_Tx" SG_ 931 CrnkInhbt_No_Cs 1;
BA_ "U_P702_MY2021_Tx" SG_ 931 CrnkInhbt_No_Cs 1;
BA_ "U_T6_MCA_MY2020_Tx" SG_ 931 CrnkInhbt_No_Cs 1;
BA_ "U_CD542_MY2021_Tx" SG_ 931 CrnkInhbt_No_Cs 1;
BA_ "U_U55X_MY2022_Tx" SG_ 931 CrnkInhbt_No_Cs 1;
BA_ "U_CD764_MY2022_Tx" SG_ 931 CrnkInhbt_No_Cs 1;
BA_ "ContentDependant" SG_ 931 CrnkInhbt_No_Cnt 1;
BA_ "MetaData" SG_ 931 CrnkInhbt_No_Cnt 1;
BA_ "U_CX727_MY2021_Tx" SG_ 931 CrnkInhbt_No_Cnt 1;
BA_ "U_P702_MY2021_Tx" SG_ 931 CrnkInhbt_No_Cnt 1;
BA_ "U_T6_MCA_MY2020_Tx" SG_ 931 CrnkInhbt_No_Cnt 1;
BA_ "U_CD542_MY2021_Tx" SG_ 931 CrnkInhbt_No_Cnt 1;
BA_ "U_U55X_MY2022_Tx" SG_ 931 CrnkInhbt_No_Cnt 1;
BA_ "U_CD764_MY2022_Tx" SG_ 931 CrnkInhbt_No_Cnt 1;
BA_ "GenSigStartValueInteger" SG_ 931 CrnkInhbt_B_Stat 1;
BA_ "GenSigStartValue" SG_ 931 CrnkInhbt_B_Stat 1;
BA_ "U_CX727_MY2021_Tx" SG_ 931 CrnkInhbt_B_Stat 1;
BA_ "U_P702_MY2021_Tx" SG_ 931 CrnkInhbt_B_Stat 1;
BA_ "U_T6_MCA_MY2020_Tx" SG_ 931 CrnkInhbt_B_Stat 1;
BA_ "U_CD542_MY2021_Tx" SG_ 931 CrnkInhbt_B_Stat 1;
BA_ "U_U55X_MY2022_Tx" SG_ 931 CrnkInhbt_B_Stat 1;
BA_ "U_CD764_MY2022_Tx" SG_ 931 CrnkInhbt_B_Stat 1;
BA_ "U_T6_MCA_MY2020_Tx" SG_ 931 AdvStrt_No_Stat 1;
BA_ "U_CD542_MY2021_Tx" SG_ 931 AdvStrt_No_Stat 1;
BA_ "U_U55X_MY2022_Tx" SG_ 931 AdvStrt_No_Stat 1;
BA_ "U_CD764_MY2022_Tx" SG_ 931 AdvStrt_No_Stat 1;
BA_ "U_CX727_MY2021_Tx" SG_ 931 IgnPreOffActv_B_Stat 1;
BA_ "U_P702_MY2021_Tx" SG_ 931 IgnPreOffActv_B_Stat 1;
BA_ "U_T6_MCA_MY2020_Tx" SG_ 931 IgnPreOffActv_B_Stat 1;
BA_ "U_CD542_MY2021_Tx" SG_ 931 IgnPreOffActv_B_Stat 1;
BA_ "U_U55X_MY2022_Tx" SG_ 931 IgnPreOffActv_B_Stat 1;
BA_ "U_CD764_MY2022_Tx" SG_ 931 IgnPreOffActv_B_Stat 1;
BA_ "GenSigStartValueInteger" SG_ 1488 BCMC_GWOnBoardTester 255;
BA_ "ContentDependant" SG_ 1488 BCMC_GWOnBoardTester 1;
BA_ "GenSigStartValue" SG_ 1488 BCMC_GWOnBoardTester 255;
BA_ "U_CX727_MY2021_Tx" SG_ 1488 BCMC_GWOnBoardTester 1;
BA_ "U_P702_MY2021_Tx" SG_ 1488 BCMC_GWOnBoardTester 1;
BA_ "U_T6_MCA_MY2020_Tx" SG_ 1488 BCMC_GWOnBoardTester 1;
BA_ "U_CD542_MY2021_Tx" SG_ 1488 BCMC_GWOnBoardTester 1;
BA_ "U_U55X_MY2022_Tx" SG_ 1488 BCMC_GWOnBoardTester 1;
BA_ "U_CD764_MY2022_Tx" SG_ 1488 BCMC_GWOnBoardTester 1;
BA_ "GenSigStartValueInteger" SG_ 1488 BCMC_GWNMProxy 255;
BA_ "ContentDependant" SG_ 1488 BCMC_GWNMProxy 1;
BA_ "GenSigStartValue" SG_ 1488 BCMC_GWNMProxy 255;
BA_ "U_CX727_MY2021_Tx" SG_ 1488 BCMC_GWNMProxy 1;
BA_ "U_P702_MY2021_Tx" SG_ 1488 BCMC_GWNMProxy 1;
BA_ "U_T6_MCA_MY2020_Tx" SG_ 1488 BCMC_GWNMProxy 1;
BA_ "U_CD542_MY2021_Tx" SG_ 1488 BCMC_GWNMProxy 1;
BA_ "U_U55X_MY2022_Tx" SG_ 1488 BCMC_GWNMProxy 1;
BA_ "U_CD764_MY2022_Tx" SG_ 1488 BCMC_GWNMProxy 1;
BA_ "GenSigStartValueInteger" SG_ 1488 BCMC_AutoSarNMReserved4 255;
BA_ "ContentDependant" SG_ 1488 BCMC_AutoSarNMReserved4 1;
BA_ "GenSigStartValue" SG_ 1488 BCMC_AutoSarNMReserved4 255;
BA_ "U_CX727_MY2021_Tx" SG_ 1488 BCMC_AutoSarNMReserved4 1;
BA_ "U_P702_MY2021_Tx" SG_ 1488 BCMC_AutoSarNMReserved4 1;
BA_ "U_T6_MCA_MY2020_Tx" SG_ 1488 BCMC_AutoSarNMReserved4 1;
BA_ "U_CD542_MY2021_Tx" SG_ 1488 BCMC_AutoSarNMReserved4 1;
BA_ "U_U55X_MY2022_Tx" SG_ 1488 BCMC_AutoSarNMReserved4 1;
BA_ "U_CD764_MY2022_Tx" SG_ 1488 BCMC_AutoSarNMReserved4 1;
BA_ "GenSigStartValueInteger" SG_ 1488 BCMC_AutoSarNMReserved3 255;
BA_ "ContentDependant" SG_ 1488 BCMC_AutoSarNMReserved3 1;
BA_ "GenSigStartValue" SG_ 1488 BCMC_AutoSarNMReserved3 255;
BA_ "U_CX727_MY2021_Tx" SG_ 1488 BCMC_AutoSarNMReserved3 1;
BA_ "U_P702_MY2021_Tx" SG_ 1488 BCMC_AutoSarNMReserved3 1;
BA_ "U_T6_MCA_MY2020_Tx" SG_ 1488 BCMC_AutoSarNMReserved3 1;
BA_ "U_CD542_MY2021_Tx" SG_ 1488 BCMC_AutoSarNMReserved3 1;
BA_ "U_U55X_MY2022_Tx" SG_ 1488 BCMC_AutoSarNMReserved3 1;
BA_ "U_CD764_MY2022_Tx" SG_ 1488 BCMC_AutoSarNMReserved3 1;
BA_ "GenSigStartValueInteger" SG_ 1488 BCMC_AutoSarNMReserved2 255;
BA_ "ContentDependant" SG_ 1488 BCMC_AutoSarNMReserved2 1;
BA_ "GenSigStartValue" SG_ 1488 BCMC_AutoSarNMReserved2 255;
BA_ "U_CX727_MY2021_Tx" SG_ 1488 BCMC_AutoSarNMReserved2 1;
BA_ "U_P702_MY2021_Tx" SG_ 1488 BCMC_AutoSarNMReserved2 1;
BA_ "U_T6_MCA_MY2020_Tx" SG_ 1488 BCMC_AutoSarNMReserved2 1;
BA_ "U_CD542_MY2021_Tx" SG_ 1488 BCMC_AutoSarNMReserved2 1;
BA_ "U_U55X_MY2022_Tx" SG_ 1488 BCMC_AutoSarNMReserved2 1;
BA_ "U_CD764_MY2022_Tx" SG_ 1488 BCMC_AutoSarNMReserved2 1;
BA_ "GenSigStartValueInteger" SG_ 1488 BCMC_AutoSarNMReserved1 255;
BA_ "ContentDependant" SG_ 1488 BCMC_AutoSarNMReserved1 1;
BA_ "GenSigStartValue" SG_ 1488 BCMC_AutoSarNMReserved1 255;
BA_ "U_CX727_MY2021_Tx" SG_ 1488 BCMC_AutoSarNMReserved1 1;
BA_ "U_P702_MY2021_Tx" SG_ 1488 BCMC_AutoSarNMReserved1 1;
BA_ "U_T6_MCA_MY2020_Tx" SG_ 1488 BCMC_AutoSarNMReserved1 1;
BA_ "U_CD542_MY2021_Tx" SG_ 1488 BCMC_AutoSarNMReserved1 1;
BA_ "U_U55X_MY2022_Tx" SG_ 1488 BCMC_AutoSarNMReserved1 1;
BA_ "U_CD764_MY2022_Tx" SG_ 1488 BCMC_AutoSarNMReserved1 1;
BA_ "GenSigStartValueInteger" SG_ 1488 BCMC_AutoSarNMNodeId 208;
BA_ "ContentDependant" SG_ 1488 BCMC_AutoSarNMNodeId 1;
BA_ "GenSigStartValue" SG_ 1488 BCMC_AutoSarNMNodeId 208;
BA_ "U_CX727_MY2021_Tx" SG_ 1488 BCMC_AutoSarNMNodeId 1;
BA_ "U_P702_MY2021_Tx" SG_ 1488 BCMC_AutoSarNMNodeId 1;
BA_ "U_T6_MCA_MY2020_Tx" SG_ 1488 BCMC_AutoSarNMNodeId 1;
BA_ "U_CD542_MY2021_Tx" SG_ 1488 BCMC_AutoSarNMNodeId 1;
BA_ "U_U55X_MY2022_Tx" SG_ 1488 BCMC_AutoSarNMNodeId 1;
BA_ "U_CD764_MY2022_Tx" SG_ 1488 BCMC_AutoSarNMNodeId 1;
BA_ "ContentDependant" SG_ 1488 BCMC_AutoSarNMControl 1;
BA_ "U_CX727_MY2021_Tx" SG_ 1488 BCMC_AutoSarNMControl 1;
BA_ "U_P702_MY2021_Tx" SG_ 1488 BCMC_AutoSarNMControl 1;
BA_ "U_T6_MCA_MY2020_Tx" SG_ 1488 BCMC_AutoSarNMControl 1;
BA_ "U_CD542_MY2021_Tx" SG_ 1488 BCMC_AutoSarNMControl 1;
BA_ "U_U55X_MY2022_Tx" SG_ 1488 BCMC_AutoSarNMControl 1;
BA_ "U_CD764_MY2022_Tx" SG_ 1488 BCMC_AutoSarNMControl 1;
BA_ "GenSigSendType" SG_ 1776 TesterPhysicalReqBCMC_CPDB 3;
BA_ "U_CX727_MY2021_Rx" SG_ 1776 TesterPhysicalReqBCMC_CPDB 1;
BA_ "U_P702_MY2021_Rx" SG_ 1776 TesterPhysicalReqBCMC_CPDB 1;
BA_ "U_T6_MCA_MY2020_Rx" SG_ 1776 TesterPhysicalReqBCMC_CPDB 1;
BA_ "U_CD542_MY2021_Rx" SG_ 1776 TesterPhysicalReqBCMC_CPDB 1;
BA_ "U_U55X_MY2022_Rx" SG_ 1776 TesterPhysicalReqBCMC_CPDB 1;
BA_ "U_CD764_MY2022_Rx" SG_ 1776 TesterPhysicalReqBCMC_CPDB 1;
BA_ "GenSigSendType" SG_ 1784 TesterPhysicalResBCMC_CPDB 3;
BA_ "U_CX727_MY2021_Tx" SG_ 1784 TesterPhysicalResBCMC_CPDB 1;
BA_ "U_P702_MY2021_Tx" SG_ 1784 TesterPhysicalResBCMC_CPDB 1;
BA_ "U_T6_MCA_MY2020_Tx" SG_ 1784 TesterPhysicalResBCMC_CPDB 1;
BA_ "U_CD542_MY2021_Tx" SG_ 1784 TesterPhysicalResBCMC_CPDB 1;
BA_ "U_U55X_MY2022_Tx" SG_ 1784 TesterPhysicalResBCMC_CPDB 1;
BA_ "U_CD764_MY2022_Tx" SG_ 1784 TesterPhysicalResBCMC_CPDB 1;
BA_ "GenSigSendType" SG_ 563 DrvBhavAudioAlrt_D_Rq 3;
BA_ "ECGUsedTxSignal" SG_ 563 DrvBhavAudioAlrt_D_Rq 1;
BA_ "U_CD764_MY2022_Tx" SG_ 563 DrvBhavAudioAlrt_D_Rq 1;
BA_ "WakeupSignal" SG_ 563 NtfyDrvTrgtDist_L2_Rq 1;
BA_ "GenSigStartValueInteger" SG_ 563 NtfyDrvTrgtDist_L2_Rq 1;
BA_ "GenSigStartValue" SG_ 563 NtfyDrvTrgtDist_L2_Rq 8190;
BA_ "GenSigSendType" SG_ 563 NtfyDrvTrgtDist_L2_Rq 3;
BA_ "ECGUsedTxSignal" SG_ 563 NtfyDrvTrgtDist_L2_Rq 1;
BA_ "U_CD542_MY2021_Tx" SG_ 563 NtfyDrvTrgtDist_L2_Rq 1;
BA_ "U_CD764_MY2022_Tx" SG_ 563 NtfyDrvTrgtDist_L2_Rq 1;
BA_ "GenSigSendType" SG_ 563 BattChrgStrtStop_D_Rq 3;
BA_ "ECGUsedTxSignal" SG_ 563 BattChrgStrtStop_D_Rq 1;
BA_ "U_CD542_MY2021_Tx" SG_ 563 BattChrgStrtStop_D_Rq 1;
BA_ "U_CD764_MY2022_Tx" SG_ 563 BattChrgStrtStop_D_Rq 1;
BA_ "GenSigSendType" SG_ 563 DrvBhavWarn_B_Rq 3;
BA_ "ECGUsedTxSignal" SG_ 563 DrvBhavWarn_B_Rq 1;
BA_ "U_CD542_MY2021_Tx" SG_ 563 DrvBhavWarn_B_Rq 1;
BA_ "U_CD764_MY2022_Tx" SG_ 563 DrvBhavWarn_B_Rq 1;
BA_ "GenSigSendType" SG_ 563 OfbChrgSetSync_D_Rq 3;
BA_ "ECGUsedTxSignal" SG_ 563 OfbChrgSetSync_D_Rq 1;
BA_ "U_CD542_MY2021_Tx" SG_ 563 OfbChrgSetSync_D_Rq 1;
BA_ "U_CD764_MY2022_Tx" SG_ 563 OfbChrgSetSync_D_Rq 1;
BA_ "GenSigSendType" SG_ 563 KeyOffPwMde_D_Stat 3;
BA_ "ECGUsedTxSignal" SG_ 563 KeyOffPwMde_D_Stat 1;
BA_ "U_CD542_MY2021_Tx" SG_ 563 KeyOffPwMde_D_Stat 1;
BA_ "U_CD764_MY2022_Tx" SG_ 563 KeyOffPwMde_D_Stat 1;
BA_ "GenSigSendType" SG_ 563 ModemReset_D_Stat 3;
BA_ "ECGUsedTxSignal" SG_ 563 ModemReset_D_Stat 1;
BA_ "U_CD542_MY2021_Tx" SG_ 563 ModemReset_D_Stat 1;
BA_ "U_CD764_MY2022_Tx" SG_ 563 ModemReset_D_Stat 1;
BA_ "GenSigSendType" SG_ 563 FactoryReset_St 3;
BA_ "ECGUsedTxSignal" SG_ 563 FactoryReset_St 1;
BA_ "U_CD542_MY2021_Tx" SG_ 563 FactoryReset_St 1;
BA_ "U_CD764_MY2022_Tx" SG_ 563 FactoryReset_St 1;
BA_ "U_CX727_MY2021_Rx" SG_ 621 IgnPsswrdActv_B_Stat 1;
BA_ "U_P702_MY2021_Rx" SG_ 621 IgnPsswrdActv_B_Stat 1;
BA_ "U_T6_MCA_MY2020_Rx" SG_ 621 IgnPsswrdActv_B_Stat 1;
BA_ "U_CD542_MY2021_Rx" SG_ 621 IgnPsswrdActv_B_Stat 1;
BA_ "U_U55X_MY2022_Rx" SG_ 621 IgnPsswrdActv_B_Stat 1;
BA_ "U_CD764_MY2022_Rx" SG_ 621 IgnPsswrdActv_B_Stat 1;
BA_ "U_CX727_MY2021_Rx" SG_ 621 FobTrgtZone_D_Rq 1;
BA_ "U_P702_MY2021_Rx" SG_ 621 FobTrgtZone_D_Rq 1;
BA_ "U_T6_MCA_MY2020_Rx" SG_ 621 FobTrgtZone_D_Rq 1;
BA_ "U_CD542_MY2021_Rx" SG_ 621 FobTrgtZone_D_Rq 1;
BA_ "U_U55X_MY2022_Rx" SG_ 621 FobTrgtZone_D_Rq 1;
BA_ "U_CD764_MY2022_Rx" SG_ 621 FobTrgtZone_D_Rq 1;
BA_ "U_CX727_MY2021_Rx" SG_ 621 FobTrgtType_D_Rq 1;
BA_ "U_P702_MY2021_Rx" SG_ 621 FobTrgtType_D_Rq 1;
BA_ "U_T6_MCA_MY2020_Rx" SG_ 621 FobTrgtType_D_Rq 1;
BA_ "U_CD542_MY2021_Rx" SG_ 621 FobTrgtType_D_Rq 1;
BA_ "U_U55X_MY2022_Rx" SG_ 621 FobTrgtType_D_Rq 1;
BA_ "U_CD764_MY2022_Rx" SG_ 621 FobTrgtType_D_Rq 1;
BA_ "U_CX727_MY2021_Rx" SG_ 621 FobTrgtRollCode_No_Rq 1;
BA_ "U_P702_MY2021_Rx" SG_ 621 FobTrgtRollCode_No_Rq 1;
BA_ "U_T6_MCA_MY2020_Rx" SG_ 621 FobTrgtRollCode_No_Rq 1;
BA_ "U_CD542_MY2021_Rx" SG_ 621 FobTrgtRollCode_No_Rq 1;
BA_ "U_U55X_MY2022_Rx" SG_ 621 FobTrgtRollCode_No_Rq 1;
BA_ "U_CD764_MY2022_Rx" SG_ 621 FobTrgtRollCode_No_Rq 1;
BA_ "U_CX727_MY2021_Rx" SG_ 621 FobTrgtPssvData_No_Rq 1;
BA_ "U_P702_MY2021_Rx" SG_ 621 FobTrgtPssvData_No_Rq 1;
BA_ "U_T6_MCA_MY2020_Rx" SG_ 621 FobTrgtPssvData_No_Rq 1;
BA_ "U_CD542_MY2021_Rx" SG_ 621 FobTrgtPssvData_No_Rq 1;
BA_ "U_U55X_MY2022_Rx" SG_ 621 FobTrgtPssvData_No_Rq 1;
BA_ "U_CD764_MY2022_Rx" SG_ 621 FobTrgtPssvData_No_Rq 1;
BA_ "GenSigStartValue" SG_ 1149 BattTracPerf_Pc_Dsply 254;
BA_ "GenSigStartValue" SG_ 1149 BattTracPerf_Pc_Actl 254;
BA_ "WakeupSignal" SG_ 626 PaakCtlRollCd2_No_Copy 1;
BA_ "U_CD542_MY2021_Rx" SG_ 626 PaakCtlRollCd2_No_Copy 1;
BA_ "U_CD764_MY2022_Rx" SG_ 626 PaakCtlRollCd2_No_Copy 1;
BA_ "WakeupSignal" SG_ 626 PaakCtlIndx8_D_Stat 1;
BA_ "U_CD542_MY2021_Rx" SG_ 626 PaakCtlIndx8_D_Stat 1;
BA_ "U_CD764_MY2022_Rx" SG_ 626 PaakCtlIndx8_D_Stat 1;
BA_ "WakeupSignal" SG_ 626 PaakCtlIndx7_D_Stat 1;
BA_ "U_CD542_MY2021_Rx" SG_ 626 PaakCtlIndx7_D_Stat 1;
BA_ "U_CD764_MY2022_Rx" SG_ 626 PaakCtlIndx7_D_Stat 1;
BA_ "WakeupSignal" SG_ 626 PaakCtlIndx6_D_Stat 1;
BA_ "U_CD542_MY2021_Rx" SG_ 626 PaakCtlIndx6_D_Stat 1;
BA_ "U_CD764_MY2022_Rx" SG_ 626 PaakCtlIndx6_D_Stat 1;
BA_ "WakeupSignal" SG_ 626 PaakCtlIndx5_D_Stat 1;
BA_ "U_CD542_MY2021_Rx" SG_ 626 PaakCtlIndx5_D_Stat 1;
BA_ "U_CD764_MY2022_Rx" SG_ 626 PaakCtlIndx5_D_Stat 1;
BA_ "WakeupSignal" SG_ 626 PaakCtlIndx4_D_Stat 1;
BA_ "U_CD542_MY2021_Rx" SG_ 626 PaakCtlIndx4_D_Stat 1;
BA_ "U_CD764_MY2022_Rx" SG_ 626 PaakCtlIndx4_D_Stat 1;
BA_ "WakeupSignal" SG_ 626 PaakCtlIndx3_D_Stat 1;
BA_ "U_CD542_MY2021_Rx" SG_ 626 PaakCtlIndx3_D_Stat 1;
BA_ "U_CD764_MY2022_Rx" SG_ 626 PaakCtlIndx3_D_Stat 1;
BA_ "WakeupSignal" SG_ 626 PaakCtlIndx2_D_Stat 1;
BA_ "U_CD542_MY2021_Rx" SG_ 626 PaakCtlIndx2_D_Stat 1;
BA_ "U_CD764_MY2022_Rx" SG_ 626 PaakCtlIndx2_D_Stat 1;
BA_ "WakeupSignal" SG_ 626 PaakCtlIndx1_D_Stat 1;
BA_ "U_CD542_MY2021_Rx" SG_ 626 PaakCtlIndx1_D_Stat 1;
BA_ "U_CD764_MY2022_Rx" SG_ 626 PaakCtlIndx1_D_Stat 1;
BA_ "U_CD542_MY2021_Rx" SG_ 1161 DrSwtchInnrRr_No_Rq_UB 1;
BA_ "U_CD764_MY2022_Rx" SG_ 1161 DrSwtchInnrRr_No_Rq_UB 1;
BA_ "WakeupSignal" SG_ 1161 DrSwtchInnrRr_No_Rq 1;
BA_ "GenSigSendType" SG_ 1161 DrSwtchInnrRr_No_Rq 3;
BA_ "U_CD542_MY2021_Rx" SG_ 1161 DrSwtchInnrRr_No_Rq 1;
BA_ "U_CD764_MY2022_Rx" SG_ 1161 DrSwtchInnrRr_No_Rq 1;
BA_ "U_CD542_MY2021_Rx" SG_ 1161 DrSwtchInnrRl_No_Rq_UB 1;
BA_ "U_CD764_MY2022_Rx" SG_ 1161 DrSwtchInnrRl_No_Rq_UB 1;
BA_ "WakeupSignal" SG_ 1161 DrSwtchInnrRl_No_Rq 1;
BA_ "GenSigSendType" SG_ 1161 DrSwtchInnrRl_No_Rq 3;
BA_ "U_CD542_MY2021_Rx" SG_ 1161 DrSwtchInnrRl_No_Rq 1;
BA_ "U_CD764_MY2022_Rx" SG_ 1161 DrSwtchInnrRl_No_Rq 1;
BA_ "U_CD542_MY2021_Rx" SG_ 1161 DrLatchRolCdRr_No_Locl_UB 1;
BA_ "U_CD764_MY2022_Rx" SG_ 1161 DrLatchRolCdRr_No_Locl_UB 1;
BA_ "GenSigSendType" SG_ 1161 DrLatchRolCdRr_No_Locl 3;
BA_ "U_CD542_MY2021_Rx" SG_ 1161 DrLatchRolCdRr_No_Locl 1;
BA_ "U_CD764_MY2022_Rx" SG_ 1161 DrLatchRolCdRr_No_Locl 1;
BA_ "U_CD542_MY2021_Rx" SG_ 1161 DrLatchRolCdRl_No_Locl_UB 1;
BA_ "U_CD764_MY2022_Rx" SG_ 1161 DrLatchRolCdRl_No_Locl_UB 1;
BA_ "GenSigSendType" SG_ 1161 DrLatchRolCdRl_No_Locl 3;
BA_ "U_CD542_MY2021_Rx" SG_ 1161 DrLatchRolCdRl_No_Locl 1;
BA_ "U_CD764_MY2022_Rx" SG_ 1161 DrLatchRolCdRl_No_Locl 1;
BA_ "GenSigSendType" SG_ 960 DrLatchRolCdRr_No_Actl 3;
BA_ "U_CD542_MY2021_Tx" SG_ 960 DrLatchRolCdRr_No_Actl 1;
BA_ "U_CD764_MY2022_Tx" SG_ 960 DrLatchRolCdRr_No_Actl 1;
BA_ "GenSigSendType" SG_ 960 DrLatchRolCdRl_No_Actl 3;
BA_ "U_CD542_MY2021_Tx" SG_ 960 DrLatchRolCdRl_No_Actl 1;
BA_ "U_CD764_MY2022_Tx" SG_ 960 DrLatchRolCdRl_No_Actl 1;
BA_ "GenSigSendType" SG_ 960 DrLatchRolCdFr_No_Actl 3;
BA_ "U_CD542_MY2021_Tx" SG_ 960 DrLatchRolCdFr_No_Actl 1;
BA_ "U_CD764_MY2022_Tx" SG_ 960 DrLatchRolCdFr_No_Actl 1;
BA_ "GenSigSendType" SG_ 960 DrLatchRolCdFl_No_Actl 3;
BA_ "U_CD542_MY2021_Tx" SG_ 960 DrLatchRolCdFl_No_Actl 1;
BA_ "U_CD764_MY2022_Tx" SG_ 960 DrLatchRolCdFl_No_Actl 1;
BA_ "GenSigSendType" SG_ 957 DrSwtchInnrRr_No_Actl 3;
BA_ "U_CD542_MY2021_Tx" SG_ 957 DrSwtchInnrRr_No_Actl 1;
BA_ "U_CD764_MY2022_Tx" SG_ 957 DrSwtchInnrRr_No_Actl 1;
BA_ "GenSigSendType" SG_ 957 DrSwtchInnrRl_No_Actl 3;
BA_ "U_CD542_MY2021_Tx" SG_ 957 DrSwtchInnrRl_No_Actl 1;
BA_ "U_CD764_MY2022_Tx" SG_ 957 DrSwtchInnrRl_No_Actl 1;
BA_ "GenSigSendType" SG_ 957 DrSwtchInnrFr_No_Actl 3;
BA_ "U_CD542_MY2021_Tx" SG_ 957 DrSwtchInnrFr_No_Actl 1;
BA_ "U_CD764_MY2022_Tx" SG_ 957 DrSwtchInnrFr_No_Actl 1;
BA_ "GenSigSendType" SG_ 957 DrSwtchInnrFl_No_Actl 3;
BA_ "U_CD542_MY2021_Tx" SG_ 957 DrSwtchInnrFl_No_Actl 1;
BA_ "U_CD764_MY2022_Tx" SG_ 957 DrSwtchInnrFl_No_Actl 1;
BA_ "GenSigSendType" SG_ 957 DrSwtchExtRr_No_Actl 3;
BA_ "U_CD542_MY2021_Tx" SG_ 957 DrSwtchExtRr_No_Actl 1;
BA_ "U_CD764_MY2022_Tx" SG_ 957 DrSwtchExtRr_No_Actl 1;
BA_ "GenSigSendType" SG_ 957 DrSwtchExtRl_No_Actl 3;
BA_ "U_CD542_MY2021_Tx" SG_ 957 DrSwtchExtRl_No_Actl 1;
BA_ "U_CD764_MY2022_Tx" SG_ 957 DrSwtchExtRl_No_Actl 1;
BA_ "GenSigSendType" SG_ 957 DrSwtchExtFr_No_Actl 3;
BA_ "U_CD542_MY2021_Tx" SG_ 957 DrSwtchExtFr_No_Actl 1;
BA_ "U_CD764_MY2022_Tx" SG_ 957 DrSwtchExtFr_No_Actl 1;
BA_ "GenSigSendType" SG_ 957 DrSwtchExtFl_No_Actl 3;
BA_ "U_CD542_MY2021_Tx" SG_ 957 DrSwtchExtFl_No_Actl 1;
BA_ "U_CD764_MY2022_Tx" SG_ 957 DrSwtchExtFl_No_Actl 1;
BA_ "U_U55X_MY2022_Rx" SG_ 1159 WakeAlarm2_B_Typ_UB 1;
BA_ "U_CD764_MY2022_Rx" SG_ 1159 WakeAlarm2_B_Typ_UB 1;
BA_ "U_U55X_MY2022_Rx" SG_ 1159 WakeAlarm2_T_Rq_UB 1;
BA_ "U_CD764_MY2022_Rx" SG_ 1159 WakeAlarm2_T_Rq_UB 1;
BA_ "GenSigStartValueInteger" SG_ 1159 WakeAlarm2_T_Rq 32767;
BA_ "GenSigStartValue" SG_ 1159 WakeAlarm2_T_Rq 32767;
BA_ "GenSigSendType" SG_ 1159 WakeAlarm2_T_Rq 3;
BA_ "U_U55X_MY2022_Rx" SG_ 1159 WakeAlarm2_T_Rq 1;
BA_ "U_CD764_MY2022_Rx" SG_ 1159 WakeAlarm2_T_Rq 1;
BA_ "GenSigSendType" SG_ 1159 WakeAlarm2_B_Typ 3;
BA_ "U_U55X_MY2022_Rx" SG_ 1159 WakeAlarm2_B_Typ 1;
BA_ "U_CD764_MY2022_Rx" SG_ 1159 WakeAlarm2_B_Typ 1;
BA_ "U_CD542_MY2021_Rx" SG_ 1159 DrLatchRolCdFr_No_Locl_UB 1;
BA_ "U_CD764_MY2022_Rx" SG_ 1159 DrLatchRolCdFr_No_Locl_UB 1;
BA_ "GenSigSendType" SG_ 1159 DrLatchRolCdFr_No_Locl 3;
BA_ "U_CD542_MY2021_Rx" SG_ 1159 DrLatchRolCdFr_No_Locl 1;
BA_ "U_CD764_MY2022_Rx" SG_ 1159 DrLatchRolCdFr_No_Locl 1;
BA_ "U_CD542_MY2021_Rx" SG_ 1159 DrLatchRolCdFl_No_Locl_UB 1;
BA_ "U_CD764_MY2022_Rx" SG_ 1159 DrLatchRolCdFl_No_Locl_UB 1;
BA_ "GenSigSendType" SG_ 1159 DrLatchRolCdFl_No_Locl 3;
BA_ "U_CD542_MY2021_Rx" SG_ 1159 DrLatchRolCdFl_No_Locl 1;
BA_ "U_CD764_MY2022_Rx" SG_ 1159 DrLatchRolCdFl_No_Locl 1;
BA_ "U_CD542_MY2021_Rx" SG_ 1159 DrSwtchInnrFr_No_Rq_UB 1;
BA_ "U_CD764_MY2022_Rx" SG_ 1159 DrSwtchInnrFr_No_Rq_UB 1;
BA_ "U_CD542_MY2021_Rx" SG_ 1159 DrSwtchInnrFl_No_Rq_UB 1;
BA_ "U_CD764_MY2022_Rx" SG_ 1159 DrSwtchInnrFl_No_Rq_UB 1;
BA_ "WakeupSignal" SG_ 1159 DrSwtchInnrFr_No_Rq 1;
BA_ "GenSigSendType" SG_ 1159 DrSwtchInnrFr_No_Rq 3;
BA_ "U_CD542_MY2021_Rx" SG_ 1159 DrSwtchInnrFr_No_Rq 1;
BA_ "U_CD764_MY2022_Rx" SG_ 1159 DrSwtchInnrFr_No_Rq 1;
BA_ "WakeupSignal" SG_ 1159 DrSwtchInnrFl_No_Rq 1;
BA_ "GenSigSendType" SG_ 1159 DrSwtchInnrFl_No_Rq 3;
BA_ "U_CD542_MY2021_Rx" SG_ 1159 DrSwtchInnrFl_No_Rq 1;
BA_ "U_CD764_MY2022_Rx" SG_ 1159 DrSwtchInnrFl_No_Rq 1;
BA_ "U_CX727_MY2021_Rx" SG_ 72 immoTarget2Status 1;
BA_ "U_P702_MY2021_Rx" SG_ 72 immoTarget2Status 1;
BA_ "U_T6_MCA_MY2020_Rx" SG_ 72 immoTarget2Status 1;
BA_ "U_CD542_MY2021_Rx" SG_ 72 immoTarget2Status 1;
BA_ "U_U55X_MY2022_Rx" SG_ 72 immoTarget2Status 1;
BA_ "U_CD764_MY2022_Rx" SG_ 72 immoTarget2Status 1;
BA_ "U_CX727_MY2021_Tx" SG_ 72 immoTarget2Status 1;
BA_ "U_CX727_MY2021_Rx" SG_ 72 immoTarget2Data 1;
BA_ "U_P702_MY2021_Rx" SG_ 72 immoTarget2Data 1;
BA_ "U_T6_MCA_MY2020_Rx" SG_ 72 immoTarget2Data 1;
BA_ "U_CD542_MY2021_Rx" SG_ 72 immoTarget2Data 1;
BA_ "U_U55X_MY2022_Rx" SG_ 72 immoTarget2Data 1;
BA_ "U_CD764_MY2022_Rx" SG_ 72 immoTarget2Data 1;
BA_ "U_CX727_MY2021_Tx" SG_ 72 immoTarget2Data 1;
BA_ "U_CX727_MY2021_Rx" SG_ 72 immoTarget2Cmd 1;
BA_ "U_P702_MY2021_Rx" SG_ 72 immoTarget2Cmd 1;
BA_ "U_T6_MCA_MY2020_Rx" SG_ 72 immoTarget2Cmd 1;
BA_ "U_CD542_MY2021_Rx" SG_ 72 immoTarget2Cmd 1;
BA_ "U_U55X_MY2022_Rx" SG_ 72 immoTarget2Cmd 1;
BA_ "U_CD764_MY2022_Rx" SG_ 72 immoTarget2Cmd 1;
BA_ "U_CX727_MY2021_Tx" SG_ 72 immoTarget2Cmd 1;
BA_ "WakeupSignal" SG_ 1130 PaakCtlType_D_Stat 1;
BA_ "U_CX727_MY2021_Rx" SG_ 1130 PaakCtlType_D_Stat 1;
BA_ "U_P702_MY2021_Rx" SG_ 1130 PaakCtlType_D_Stat 1;
BA_ "U_T6_MCA_MY2020_Rx" SG_ 1130 PaakCtlType_D_Stat 1;
BA_ "U_CD542_MY2021_Rx" SG_ 1130 PaakCtlType_D_Stat 1;
BA_ "U_U55X_MY2022_Rx" SG_ 1130 PaakCtlType_D_Stat 1;
BA_ "U_CD764_MY2022_Rx" SG_ 1130 PaakCtlType_D_Stat 1;
BA_ "WakeupSignal" SG_ 1130 PaakCtlRollCode_No_Stat 1;
BA_ "U_CX727_MY2021_Rx" SG_ 1130 PaakCtlRollCode_No_Stat 1;
BA_ "U_P702_MY2021_Rx" SG_ 1130 PaakCtlRollCode_No_Stat 1;
BA_ "U_T6_MCA_MY2020_Rx" SG_ 1130 PaakCtlRollCode_No_Stat 1;
BA_ "U_CD542_MY2021_Rx" SG_ 1130 PaakCtlRollCode_No_Stat 1;
BA_ "U_U55X_MY2022_Rx" SG_ 1130 PaakCtlRollCode_No_Stat 1;
BA_ "U_CD764_MY2022_Rx" SG_ 1130 PaakCtlRollCode_No_Stat 1;
BA_ "WakeupSignal" SG_ 1130 PaakCtlPssvData_No_Actl 1;
BA_ "ContentDependant" SG_ 1130 PaakCtlPssvData_No_Actl 1;
BA_ "U_CX727_MY2021_Rx" SG_ 1130 PaakCtlPssvData_No_Actl 1;
BA_ "U_P702_MY2021_Rx" SG_ 1130 PaakCtlPssvData_No_Actl 1;
BA_ "U_T6_MCA_MY2020_Rx" SG_ 1130 PaakCtlPssvData_No_Actl 1;
BA_ "U_CD542_MY2021_Rx" SG_ 1130 PaakCtlPssvData_No_Actl 1;
BA_ "U_U55X_MY2022_Rx" SG_ 1130 PaakCtlPssvData_No_Actl 1;
BA_ "U_CD764_MY2022_Rx" SG_ 1130 PaakCtlPssvData_No_Actl 1;
BA_ "WakeupSignal" SG_ 1130 PaakCtlData_D_Stat 1;
BA_ "U_CX727_MY2021_Rx" SG_ 1130 PaakCtlData_D_Stat 1;
BA_ "U_P702_MY2021_Rx" SG_ 1130 PaakCtlData_D_Stat 1;
BA_ "U_T6_MCA_MY2020_Rx" SG_ 1130 PaakCtlData_D_Stat 1;
BA_ "U_CD542_MY2021_Rx" SG_ 1130 PaakCtlData_D_Stat 1;
BA_ "U_U55X_MY2022_Rx" SG_ 1130 PaakCtlData_D_Stat 1;
BA_ "U_CD764_MY2022_Rx" SG_ 1130 PaakCtlData_D_Stat 1;
BA_ "WakeupSignal" SG_ 1130 PaakLoclzd_D_Stat 1;
BA_ "U_CD542_MY2021_Rx" SG_ 1130 PaakLoclzd_D_Stat 1;
BA_ "U_U55X_MY2022_Rx" SG_ 1130 PaakLoclzd_D_Stat 1;
BA_ "U_CD764_MY2022_Rx" SG_ 1130 PaakLoclzd_D_Stat 1;
BA_ "U_CX727_MY2021_Rx" SG_ 1132 PaakCtlIndx8_No_Actl 1;
BA_ "U_P702_MY2021_Rx" SG_ 1132 PaakCtlIndx8_No_Actl 1;
BA_ "U_T6_MCA_MY2020_Rx" SG_ 1132 PaakCtlIndx8_No_Actl 1;
BA_ "U_CD542_MY2021_Rx" SG_ 1132 PaakCtlIndx8_No_Actl 1;
BA_ "U_CD764_MY2022_Rx" SG_ 1132 PaakCtlIndx8_No_Actl 1;
BA_ "U_CX727_MY2021_Rx" SG_ 1132 PaakCtlIndx7_No_Actl 1;
BA_ "U_P702_MY2021_Rx" SG_ 1132 PaakCtlIndx7_No_Actl 1;
BA_ "U_T6_MCA_MY2020_Rx" SG_ 1132 PaakCtlIndx7_No_Actl 1;
BA_ "U_CD542_MY2021_Rx" SG_ 1132 PaakCtlIndx7_No_Actl 1;
BA_ "U_CD764_MY2022_Rx" SG_ 1132 PaakCtlIndx7_No_Actl 1;
BA_ "U_CX727_MY2021_Rx" SG_ 1132 PaakCtlIndx6_No_Actl 1;
BA_ "U_P702_MY2021_Rx" SG_ 1132 PaakCtlIndx6_No_Actl 1;
BA_ "U_T6_MCA_MY2020_Rx" SG_ 1132 PaakCtlIndx6_No_Actl 1;
BA_ "U_CD542_MY2021_Rx" SG_ 1132 PaakCtlIndx6_No_Actl 1;
BA_ "U_CD764_MY2022_Rx" SG_ 1132 PaakCtlIndx6_No_Actl 1;
BA_ "U_CX727_MY2021_Rx" SG_ 1132 PaakCtlIndx5_No_Actl 1;
BA_ "U_P702_MY2021_Rx" SG_ 1132 PaakCtlIndx5_No_Actl 1;
BA_ "U_T6_MCA_MY2020_Rx" SG_ 1132 PaakCtlIndx5_No_Actl 1;
BA_ "U_CD542_MY2021_Rx" SG_ 1132 PaakCtlIndx5_No_Actl 1;
BA_ "U_CD764_MY2022_Rx" SG_ 1132 PaakCtlIndx5_No_Actl 1;
BA_ "U_CX727_MY2021_Rx" SG_ 1132 PaakCtlIndx4_No_Actl 1;
BA_ "U_P702_MY2021_Rx" SG_ 1132 PaakCtlIndx4_No_Actl 1;
BA_ "U_T6_MCA_MY2020_Rx" SG_ 1132 PaakCtlIndx4_No_Actl 1;
BA_ "U_CD542_MY2021_Rx" SG_ 1132 PaakCtlIndx4_No_Actl 1;
BA_ "U_CD764_MY2022_Rx" SG_ 1132 PaakCtlIndx4_No_Actl 1;
BA_ "U_CX727_MY2021_Rx" SG_ 1132 PaakCtlIndx3_No_Actl 1;
BA_ "U_P702_MY2021_Rx" SG_ 1132 PaakCtlIndx3_No_Actl 1;
BA_ "U_T6_MCA_MY2020_Rx" SG_ 1132 PaakCtlIndx3_No_Actl 1;
BA_ "U_CD542_MY2021_Rx" SG_ 1132 PaakCtlIndx3_No_Actl 1;
BA_ "U_CD764_MY2022_Rx" SG_ 1132 PaakCtlIndx3_No_Actl 1;
BA_ "U_CX727_MY2021_Rx" SG_ 1132 PaakCtlIndx2_No_Actl 1;
BA_ "U_P702_MY2021_Rx" SG_ 1132 PaakCtlIndx2_No_Actl 1;
BA_ "U_T6_MCA_MY2020_Rx" SG_ 1132 PaakCtlIndx2_No_Actl 1;
BA_ "U_CD542_MY2021_Rx" SG_ 1132 PaakCtlIndx2_No_Actl 1;
BA_ "U_CD764_MY2022_Rx" SG_ 1132 PaakCtlIndx2_No_Actl 1;
BA_ "U_CX727_MY2021_Rx" SG_ 1132 PaakCtlIndx1_No_Actl 1;
BA_ "U_P702_MY2021_Rx" SG_ 1132 PaakCtlIndx1_No_Actl 1;
BA_ "U_T6_MCA_MY2020_Rx" SG_ 1132 PaakCtlIndx1_No_Actl 1;
BA_ "U_CD542_MY2021_Rx" SG_ 1132 PaakCtlIndx1_No_Actl 1;
BA_ "U_CD764_MY2022_Rx" SG_ 1132 PaakCtlIndx1_No_Actl 1;
BA_ "U_CX727_MY2021_Rx" SG_ 1132 PaakCtlRollCode_No_Copy 1;
BA_ "U_P702_MY2021_Rx" SG_ 1132 PaakCtlRollCode_No_Copy 1;
BA_ "U_T6_MCA_MY2020_Rx" SG_ 1132 PaakCtlRollCode_No_Copy 1;
BA_ "U_CD542_MY2021_Rx" SG_ 1132 PaakCtlRollCode_No_Copy 1;
BA_ "U_CD764_MY2022_Rx" SG_ 1132 PaakCtlRollCode_No_Copy 1;
BA_ "GenSigSendType" SG_ 1129 PaaKMyKeyChng_D_Stat 3;
BA_ "U_CD764_MY2022_Tx" SG_ 1129 PaaKMyKeyChng_D_Stat 1;
BA_ "GenSigSendType" SG_ 1129 PaaKMyKeyChng_No_Actl 3;
BA_ "U_CD764_MY2022_Tx" SG_ 1129 PaaKMyKeyChng_No_Actl 1;
BA_ "U_CX727_MY2021_Tx" SG_ 1129 PaakAddEraseIndx_No_Actl 1;
BA_ "U_P702_MY2021_Tx" SG_ 1129 PaakAddEraseIndx_No_Actl 1;
BA_ "U_T6_MCA_MY2020_Tx" SG_ 1129 PaakAddEraseIndx_No_Actl 1;
BA_ "U_CD542_MY2021_Tx" SG_ 1129 PaakAddEraseIndx_No_Actl 1;
BA_ "U_U55X_MY2022_Tx" SG_ 1129 PaakAddEraseIndx_No_Actl 1;
BA_ "U_CD764_MY2022_Tx" SG_ 1129 PaakAddEraseIndx_No_Actl 1;
BA_ "GenSigSendType" SG_ 1129 PaakAddErase_D_Stat 3;
BA_ "U_CX727_MY2021_Tx" SG_ 1129 PaakAddErase_D_Stat 1;
BA_ "U_P702_MY2021_Tx" SG_ 1129 PaakAddErase_D_Stat 1;
BA_ "U_T6_MCA_MY2020_Tx" SG_ 1129 PaakAddErase_D_Stat 1;
BA_ "U_CD542_MY2021_Tx" SG_ 1129 PaakAddErase_D_Stat 1;
BA_ "U_U55X_MY2022_Tx" SG_ 1129 PaakAddErase_D_Stat 1;
BA_ "U_CD764_MY2022_Tx" SG_ 1129 PaakAddErase_D_Stat 1;
BA_ "ContentDependant" SG_ 1129 PaakTrgtActvData_No_Rq 1;
BA_ "GenSigSendType" SG_ 1129 PaakTrgtActvData_No_Rq 3;
BA_ "U_CX727_MY2021_Tx" SG_ 1129 PaakTrgtActvData_No_Rq 1;
BA_ "U_P702_MY2021_Tx" SG_ 1129 PaakTrgtActvData_No_Rq 1;
BA_ "U_T6_MCA_MY2020_Tx" SG_ 1129 PaakTrgtActvData_No_Rq 1;
BA_ "U_CD542_MY2021_Tx" SG_ 1129 PaakTrgtActvData_No_Rq 1;
BA_ "U_U55X_MY2022_Tx" SG_ 1129 PaakTrgtActvData_No_Rq 1;
BA_ "U_CD764_MY2022_Tx" SG_ 1129 PaakTrgtActvData_No_Rq 1;
BA_ "U_CX727_MY2021_Rx" SG_ 1131 KeyPadCodeProg_D_Rq 1;
BA_ "U_P702_MY2021_Rx" SG_ 1131 KeyPadCodeProg_D_Rq 1;
BA_ "U_T6_MCA_MY2020_Rx" SG_ 1131 KeyPadCodeProg_D_Rq 1;
BA_ "U_CD542_MY2021_Rx" SG_ 1131 KeyPadCodeProg_D_Rq 1;
BA_ "U_U55X_MY2022_Rx" SG_ 1131 KeyPadCodeProg_D_Rq 1;
BA_ "U_CD764_MY2022_Rx" SG_ 1131 KeyPadCodeProg_D_Rq 1;
BA_ "U_CX727_MY2021_Rx" SG_ 1131 PaakCtlActv_No_Actl 1;
BA_ "U_P702_MY2021_Rx" SG_ 1131 PaakCtlActv_No_Actl 1;
BA_ "U_T6_MCA_MY2020_Rx" SG_ 1131 PaakCtlActv_No_Actl 1;
BA_ "U_CD542_MY2021_Rx" SG_ 1131 PaakCtlActv_No_Actl 1;
BA_ "U_U55X_MY2022_Rx" SG_ 1131 PaakCtlActv_No_Actl 1;
BA_ "U_CD764_MY2022_Rx" SG_ 1131 PaakCtlActv_No_Actl 1;
BA_ "WakeupSignal" SG_ 1131 PaakCtlActv_D_Rq 1;
BA_ "U_CX727_MY2021_Rx" SG_ 1131 PaakCtlActv_D_Rq 1;
BA_ "U_P702_MY2021_Rx" SG_ 1131 PaakCtlActv_D_Rq 1;
BA_ "U_T6_MCA_MY2020_Rx" SG_ 1131 PaakCtlActv_D_Rq 1;
BA_ "U_CD542_MY2021_Rx" SG_ 1131 PaakCtlActv_D_Rq 1;
BA_ "U_U55X_MY2022_Rx" SG_ 1131 PaakCtlActv_D_Rq 1;
BA_ "U_CD764_MY2022_Rx" SG_ 1131 PaakCtlActv_D_Rq 1;
BA_ "ContentDependant" SG_ 1131 PaakCtlActvData_No_Actl 1;
BA_ "U_CX727_MY2021_Rx" SG_ 1131 PaakCtlActvData_No_Actl 1;
BA_ "U_P702_MY2021_Rx" SG_ 1131 PaakCtlActvData_No_Actl 1;
BA_ "U_T6_MCA_MY2020_Rx" SG_ 1131 PaakCtlActvData_No_Actl 1;
BA_ "U_CD542_MY2021_Rx" SG_ 1131 PaakCtlActvData_No_Actl 1;
BA_ "U_U55X_MY2022_Rx" SG_ 1131 PaakCtlActvData_No_Actl 1;
BA_ "U_CD764_MY2022_Rx" SG_ 1131 PaakCtlActvData_No_Actl 1;
BA_ "GenSigSendType" SG_ 1128 KeyPadCodeProg_D_Stat 3;
BA_ "U_CX727_MY2021_Tx" SG_ 1128 KeyPadCodeProg_D_Stat 1;
BA_ "U_P702_MY2021_Tx" SG_ 1128 KeyPadCodeProg_D_Stat 1;
BA_ "U_T6_MCA_MY2020_Tx" SG_ 1128 KeyPadCodeProg_D_Stat 1;
BA_ "U_CD542_MY2021_Tx" SG_ 1128 KeyPadCodeProg_D_Stat 1;
BA_ "U_U55X_MY2022_Tx" SG_ 1128 KeyPadCodeProg_D_Stat 1;
BA_ "U_CD764_MY2022_Tx" SG_ 1128 KeyPadCodeProg_D_Stat 1;
BA_ "ContentDependant" SG_ 1128 PaakTrgtPssvData_No_Rq 1;
BA_ "GenSigSendType" SG_ 1128 PaakTrgtPssvData_No_Rq 3;
BA_ "U_CX727_MY2021_Tx" SG_ 1128 PaakTrgtPssvData_No_Rq 1;
BA_ "U_P702_MY2021_Tx" SG_ 1128 PaakTrgtPssvData_No_Rq 1;
BA_ "U_T6_MCA_MY2020_Tx" SG_ 1128 PaakTrgtPssvData_No_Rq 1;
BA_ "U_CD542_MY2021_Tx" SG_ 1128 PaakTrgtPssvData_No_Rq 1;
BA_ "U_U55X_MY2022_Tx" SG_ 1128 PaakTrgtPssvData_No_Rq 1;
BA_ "U_CD764_MY2022_Tx" SG_ 1128 PaakTrgtPssvData_No_Rq 1;
BA_ "WakeupSignal" SG_ 1128 PaakTrgtType_D_Rq 1;
BA_ "GenSigSendType" SG_ 1128 PaakTrgtType_D_Rq 3;
BA_ "U_CX727_MY2021_Tx" SG_ 1128 PaakTrgtType_D_Rq 1;
BA_ "U_P702_MY2021_Tx" SG_ 1128 PaakTrgtType_D_Rq 1;
BA_ "U_T6_MCA_MY2020_Tx" SG_ 1128 PaakTrgtType_D_Rq 1;
BA_ "U_CD542_MY2021_Tx" SG_ 1128 PaakTrgtType_D_Rq 1;
BA_ "U_U55X_MY2022_Tx" SG_ 1128 PaakTrgtType_D_Rq 1;
BA_ "U_CD764_MY2022_Tx" SG_ 1128 PaakTrgtType_D_Rq 1;
BA_ "GenSigSendType" SG_ 1128 PaakTrgtRollCode_No_Rq 3;
BA_ "U_CX727_MY2021_Tx" SG_ 1128 PaakTrgtRollCode_No_Rq 1;
BA_ "U_P702_MY2021_Tx" SG_ 1128 PaakTrgtRollCode_No_Rq 1;
BA_ "U_T6_MCA_MY2020_Tx" SG_ 1128 PaakTrgtRollCode_No_Rq 1;
BA_ "U_CD542_MY2021_Tx" SG_ 1128 PaakTrgtRollCode_No_Rq 1;
BA_ "U_U55X_MY2022_Tx" SG_ 1128 PaakTrgtRollCode_No_Rq 1;
BA_ "U_CD764_MY2022_Tx" SG_ 1128 PaakTrgtRollCode_No_Rq 1;
BA_ "GenSigSendType" SG_ 1128 PaakTrgtZone_D_Rq 3;
BA_ "U_CX727_MY2021_Tx" SG_ 1128 PaakTrgtZone_D_Rq 1;
BA_ "U_P702_MY2021_Tx" SG_ 1128 PaakTrgtZone_D_Rq 1;
BA_ "U_T6_MCA_MY2020_Tx" SG_ 1128 PaakTrgtZone_D_Rq 1;
BA_ "U_CD542_MY2021_Tx" SG_ 1128 PaakTrgtZone_D_Rq 1;
BA_ "U_U55X_MY2022_Tx" SG_ 1128 PaakTrgtZone_D_Rq 1;
BA_ "U_CD764_MY2022_Tx" SG_ 1128 PaakTrgtZone_D_Rq 1;
BA_ "GenSigSendType" SG_ 1128 PaakTrgtData_D_Rq 3;
BA_ "U_CX727_MY2021_Tx" SG_ 1128 PaakTrgtData_D_Rq 1;
BA_ "U_P702_MY2021_Tx" SG_ 1128 PaakTrgtData_D_Rq 1;
BA_ "U_T6_MCA_MY2020_Tx" SG_ 1128 PaakTrgtData_D_Rq 1;
BA_ "U_CD542_MY2021_Tx" SG_ 1128 PaakTrgtData_D_Rq 1;
BA_ "U_U55X_MY2022_Tx" SG_ 1128 PaakTrgtData_D_Rq 1;
BA_ "U_CD764_MY2022_Tx" SG_ 1128 PaakTrgtData_D_Rq 1;
BA_ "WakeupSignal" SG_ 1128 PaakTrgtPreAuthrz_B_Rq 1;
BA_ "GenSigSendType" SG_ 1128 PaakTrgtPreAuthrz_B_Rq 3;
BA_ "U_CD542_MY2021_Tx" SG_ 1128 PaakTrgtPreAuthrz_B_Rq 1;
BA_ "U_CD764_MY2022_Tx" SG_ 1128 PaakTrgtPreAuthrz_B_Rq 1;
BA_ "GenSigStartValueInteger" SG_ 123 BattTrac_U2_Actl 1022;
BA_ "GenSigStartValue" SG_ 123 BattTrac_U2_Actl 4094;
BA_ "ECGUsedRxSignal" SG_ 123 BattTrac_U2_Actl 1;
BA_ "U_CD542_MY2021_Rx" SG_ 123 BattTrac_U2_Actl 1;
BA_ "U_U55X_MY2022_Rx" SG_ 123 BattTrac_U2_Actl 1;
BA_ "GenSigStartValueInteger" SG_ 123 BattTrac_I2_Actl 15000;
BA_ "GenSigStartValue" SG_ 123 BattTrac_I2_Actl 262142;
BA_ "ECGUsedRxSignal" SG_ 123 BattTrac_I2_Actl 1;
BA_ "U_CD542_MY2021_Rx" SG_ 123 BattTrac_I2_Actl 1;
BA_ "U_U55X_MY2022_Rx" SG_ 123 BattTrac_I2_Actl 1;
BA_ "WakeupSignal" SG_ 816 KeyPadCodeDgt7_D_Stat 1;
BA_ "U_CD542_MY2021_Rx" SG_ 816 KeyPadCodeDgt7_D_Stat 1;
BA_ "U_CD764_MY2022_Rx" SG_ 816 KeyPadCodeDgt7_D_Stat 1;
BA_ "WakeupSignal" SG_ 816 KeyPadCodeDgt6_D_Stat 1;
BA_ "U_CD542_MY2021_Rx" SG_ 816 KeyPadCodeDgt6_D_Stat 1;
BA_ "U_CD764_MY2022_Rx" SG_ 816 KeyPadCodeDgt6_D_Stat 1;
BA_ "WakeupSignal" SG_ 816 KeyPadCodeDgt5_D_Stat 1;
BA_ "U_CD542_MY2021_Rx" SG_ 816 KeyPadCodeDgt5_D_Stat 1;
BA_ "U_CD764_MY2022_Rx" SG_ 816 KeyPadCodeDgt5_D_Stat 1;
BA_ "WakeupSignal" SG_ 816 KeyPadCodeDgt4_D_Stat 1;
BA_ "U_CD542_MY2021_Rx" SG_ 816 KeyPadCodeDgt4_D_Stat 1;
BA_ "U_CD764_MY2022_Rx" SG_ 816 KeyPadCodeDgt4_D_Stat 1;
BA_ "WakeupSignal" SG_ 816 KeyPadCodeDgt3_D_Stat 1;
BA_ "U_CD542_MY2021_Rx" SG_ 816 KeyPadCodeDgt3_D_Stat 1;
BA_ "U_CD764_MY2022_Rx" SG_ 816 KeyPadCodeDgt3_D_Stat 1;
BA_ "WakeupSignal" SG_ 816 KeyPadCodeDgt2_D_Stat 1;
BA_ "U_CD542_MY2021_Rx" SG_ 816 KeyPadCodeDgt2_D_Stat 1;
BA_ "U_CD764_MY2022_Rx" SG_ 816 KeyPadCodeDgt2_D_Stat 1;
BA_ "WakeupSignal" SG_ 816 KeyPadCodeDgt1_D_Stat 1;
BA_ "U_CD542_MY2021_Rx" SG_ 816 KeyPadCodeDgt1_D_Stat 1;
BA_ "U_CD764_MY2022_Rx" SG_ 816 KeyPadCodeDgt1_D_Stat 1;
BA_ "WakeupSignal" SG_ 816 CntrStk2_D_RqAssoc 1;
BA_ "GenSigStartValueInteger" SG_ 816 CntrStk2_D_RqAssoc 3;
BA_ "GenSigStartValue" SG_ 816 CntrStk2_D_RqAssoc 3;
BA_ "U_CD542_MY2021_Rx" SG_ 816 CntrStk2_D_RqAssoc 1;
BA_ "U_CD764_MY2022_Rx" SG_ 816 CntrStk2_D_RqAssoc 1;
BA_ "U_T6_MCA_MY2020_Rx" SG_ 816 KeylessIdl_D_Rq 1;
BA_ "U_U55X_MY2022_Rx" SG_ 816 KeylessIdl_D_Rq 1;
BA_ "U_CD764_MY2022_Rx" SG_ 816 KeylessIdl_D_Rq 1;
BA_ "GenSigSendType" SG_ 2612066520 PARSEDPushFcGWM_ECGtoPACM 3;
BA_ "U_CD542_MY2021_Rx" SG_ 2612066520 PARSEDPushFcGWM_ECGtoPACM 1;
BA_ "ECGUsedTxSignal" SG_ 2612066520 PARSEDPushFcGWM_ECGtoPACM 1;
BA_ "U_CD542_MY2021_Tx" SG_ 2612066520 PARSEDPushFcGWM_ECGtoPACM 1;
BA_ "GenSigSendType" SG_ 966 TrnkFrontInhbt_B_Stat 3;
BA_ "U_CD764_MY2022_Tx" SG_ 966 TrnkFrontInhbt_B_Stat 1;
BA_ "GenSigSendType" SG_ 966 TrnkFrontRleas_D_Src 3;
BA_ "U_U55X_MY2022_Tx" SG_ 966 TrnkFrontRleas_D_Src 1;
BA_ "U_CD764_MY2022_Tx" SG_ 966 TrnkFrontRleas_D_Src 1;
BA_ "WakeupSignal" SG_ 966 TrunkFrontOpen_No_Actl 1;
BA_ "GenSigSendType" SG_ 966 TrunkFrontOpen_No_Actl 3;
BA_ "U_CD542_MY2021_Tx" SG_ 966 TrunkFrontOpen_No_Actl 1;
BA_ "U_U55X_MY2022_Tx" SG_ 966 TrunkFrontOpen_No_Actl 1;
BA_ "U_CD764_MY2022_Tx" SG_ 966 TrunkFrontOpen_No_Actl 1;
BA_ "WakeupSignal" SG_ 966 TrunkFrontRolCd_No_Actl 1;
BA_ "GenSigSendType" SG_ 966 TrunkFrontRolCd_No_Actl 3;
BA_ "U_CD542_MY2021_Tx" SG_ 966 TrunkFrontRolCd_No_Actl 1;
BA_ "U_U55X_MY2022_Tx" SG_ 966 TrunkFrontRolCd_No_Actl 1;
BA_ "U_CD764_MY2022_Tx" SG_ 966 TrunkFrontRolCd_No_Actl 1;
BA_ "U_T6_MCA_MY2020_Rx" SG_ 943 InhbtGlblClkYr_No_Rq 1;
BA_ "U_CD542_MY2021_Rx" SG_ 943 InhbtGlblClkYr_No_Rq 1;
BA_ "U_U55X_MY2022_Rx" SG_ 943 InhbtGlblClkYr_No_Rq 1;
BA_ "U_CD764_MY2022_Rx" SG_ 943 InhbtGlblClkYr_No_Rq 1;
BA_ "U_T6_MCA_MY2020_Tx" SG_ 943 InhbtGlblClkYr_No_Rq 1;
BA_ "ECGUsedTxSignal" SG_ 943 InhbtGlblClkYr_No_Rq 1;
BA_ "U_CD542_MY2021_Tx" SG_ 943 InhbtGlblClkYr_No_Rq 1;
BA_ "U_U55X_MY2022_Tx" SG_ 943 InhbtGlblClkYr_No_Rq 1;
BA_ "U_CD764_MY2022_Tx" SG_ 943 InhbtGlblClkYr_No_Rq 1;
BA_ "U_T6_MCA_MY2020_Rx" SG_ 943 InhbtGlblClkScnd_No_Rq 1;
BA_ "U_CD542_MY2021_Rx" SG_ 943 InhbtGlblClkScnd_No_Rq 1;
BA_ "U_U55X_MY2022_Rx" SG_ 943 InhbtGlblClkScnd_No_Rq 1;
BA_ "U_CD764_MY2022_Rx" SG_ 943 InhbtGlblClkScnd_No_Rq 1;
BA_ "U_T6_MCA_MY2020_Tx" SG_ 943 InhbtGlblClkScnd_No_Rq 1;
BA_ "ECGUsedTxSignal" SG_ 943 InhbtGlblClkScnd_No_Rq 1;
BA_ "U_CD542_MY2021_Tx" SG_ 943 InhbtGlblClkScnd_No_Rq 1;
BA_ "U_U55X_MY2022_Tx" SG_ 943 InhbtGlblClkScnd_No_Rq 1;
BA_ "U_CD764_MY2022_Tx" SG_ 943 InhbtGlblClkScnd_No_Rq 1;
BA_ "U_T6_MCA_MY2020_Rx" SG_ 943 InhbtGlblClkMnte_No_Rq 1;
BA_ "U_CD542_MY2021_Rx" SG_ 943 InhbtGlblClkMnte_No_Rq 1;
BA_ "U_U55X_MY2022_Rx" SG_ 943 InhbtGlblClkMnte_No_Rq 1;
BA_ "U_CD764_MY2022_Rx" SG_ 943 InhbtGlblClkMnte_No_Rq 1;
BA_ "U_T6_MCA_MY2020_Tx" SG_ 943 InhbtGlblClkMnte_No_Rq 1;
BA_ "ECGUsedTxSignal" SG_ 943 InhbtGlblClkMnte_No_Rq 1;
BA_ "U_CD542_MY2021_Tx" SG_ 943 InhbtGlblClkMnte_No_Rq 1;
BA_ "U_U55X_MY2022_Tx" SG_ 943 InhbtGlblClkMnte_No_Rq 1;
BA_ "U_CD764_MY2022_Tx" SG_ 943 InhbtGlblClkMnte_No_Rq 1;
BA_ "U_T6_MCA_MY2020_Rx" SG_ 943 InhbtGlblClkHr_No_Rq 1;
BA_ "U_CD542_MY2021_Rx" SG_ 943 InhbtGlblClkHr_No_Rq 1;
BA_ "U_U55X_MY2022_Rx" SG_ 943 InhbtGlblClkHr_No_Rq 1;
BA_ "U_CD764_MY2022_Rx" SG_ 943 InhbtGlblClkHr_No_Rq 1;
BA_ "U_T6_MCA_MY2020_Tx" SG_ 943 InhbtGlblClkHr_No_Rq 1;
BA_ "ECGUsedTxSignal" SG_ 943 InhbtGlblClkHr_No_Rq 1;
BA_ "U_CD542_MY2021_Tx" SG_ 943 InhbtGlblClkHr_No_Rq 1;
BA_ "U_U55X_MY2022_Tx" SG_ 943 InhbtGlblClkHr_No_Rq 1;
BA_ "U_CD764_MY2022_Tx" SG_ 943 InhbtGlblClkHr_No_Rq 1;
BA_ "U_T6_MCA_MY2020_Rx" SG_ 943 InhbtGlblClkDay_No_Rq 1;
BA_ "U_CD542_MY2021_Rx" SG_ 943 InhbtGlblClkDay_No_Rq 1;
BA_ "U_U55X_MY2022_Rx" SG_ 943 InhbtGlblClkDay_No_Rq 1;
BA_ "U_CD764_MY2022_Rx" SG_ 943 InhbtGlblClkDay_No_Rq 1;
BA_ "U_T6_MCA_MY2020_Tx" SG_ 943 InhbtGlblClkDay_No_Rq 1;
BA_ "ECGUsedTxSignal" SG_ 943 InhbtGlblClkDay_No_Rq 1;
BA_ "U_CD542_MY2021_Tx" SG_ 943 InhbtGlblClkDay_No_Rq 1;
BA_ "U_U55X_MY2022_Tx" SG_ 943 InhbtGlblClkDay_No_Rq 1;
BA_ "U_CD764_MY2022_Tx" SG_ 943 InhbtGlblClkDay_No_Rq 1;
BA_ "GenSigSendType" SG_ 943 InhbtGlblClkAdj_B_Rq 3;
BA_ "U_T6_MCA_MY2020_Rx" SG_ 943 InhbtGlblClkAdj_B_Rq 1;
BA_ "U_CD542_MY2021_Rx" SG_ 943 InhbtGlblClkAdj_B_Rq 1;
BA_ "U_U55X_MY2022_Rx" SG_ 943 InhbtGlblClkAdj_B_Rq 1;
BA_ "U_CD764_MY2022_Rx" SG_ 943 InhbtGlblClkAdj_B_Rq 1;
BA_ "U_T6_MCA_MY2020_Tx" SG_ 943 InhbtGlblClkAdj_B_Rq 1;
BA_ "ECGUsedTxSignal" SG_ 943 InhbtGlblClkAdj_B_Rq 1;
BA_ "U_CD542_MY2021_Tx" SG_ 943 InhbtGlblClkAdj_B_Rq 1;
BA_ "U_U55X_MY2022_Tx" SG_ 943 InhbtGlblClkAdj_B_Rq 1;
BA_ "U_CD764_MY2022_Tx" SG_ 943 InhbtGlblClkAdj_B_Rq 1;
BA_ "U_CD764_MY2022_Tx" SG_ 932 RmtCtlBattMntr_B_Falt 1;
BA_ "U_T6_MCA_MY2020_Rx" SG_ 932 VehInhbtMde_D_Stat 1;
BA_ "ECGUsedRxSignal" SG_ 932 VehInhbtMde_D_Stat 1;
BA_ "U_CD542_MY2021_Rx" SG_ 932 VehInhbtMde_D_Stat 1;
BA_ "U_U55X_MY2022_Rx" SG_ 932 VehInhbtMde_D_Stat 1;
BA_ "U_CD764_MY2022_Rx" SG_ 932 VehInhbtMde_D_Stat 1;
BA_ "U_T6_MCA_MY2020_Tx" SG_ 932 VehInhbtMde_D_Stat 1;
BA_ "U_CD542_MY2021_Tx" SG_ 932 VehInhbtMde_D_Stat 1;
BA_ "U_U55X_MY2022_Tx" SG_ 932 VehInhbtMde_D_Stat 1;
BA_ "U_CD764_MY2022_Tx" SG_ 932 VehInhbtMde_D_Stat 1;
BA_ "U_T6_MCA_MY2020_Rx" SG_ 932 VehStrtInhbt_D_Stat 1;
BA_ "U_U55X_MY2022_Rx" SG_ 932 VehStrtInhbt_D_Stat 1;
BA_ "U_CD764_MY2022_Rx" SG_ 932 VehStrtInhbt_D_Stat 1;
BA_ "ECGUsedRxSignal" SG_ 932 VehStrtInhbt_D_Stat 1;
BA_ "U_CD542_MY2021_Rx" SG_ 932 VehStrtInhbt_D_Stat 1;
BA_ "U_T6_MCA_MY2020_Tx" SG_ 932 VehStrtInhbt_D_Stat 1;
BA_ "U_CD542_MY2021_Tx" SG_ 932 VehStrtInhbt_D_Stat 1;
BA_ "U_U55X_MY2022_Tx" SG_ 932 VehStrtInhbt_D_Stat 1;
BA_ "U_CD764_MY2022_Tx" SG_ 932 VehStrtInhbt_D_Stat 1;
BA_ "U_T6_MCA_MY2020_Rx" SG_ 932 VehOnCtl_D_Stat 1;
BA_ "U_U55X_MY2022_Rx" SG_ 932 VehOnCtl_D_Stat 1;
BA_ "U_CD764_MY2022_Rx" SG_ 932 VehOnCtl_D_Stat 1;
BA_ "ECGUsedRxSignal" SG_ 932 VehOnCtl_D_Stat 1;
BA_ "U_CD542_MY2021_Rx" SG_ 932 VehOnCtl_D_Stat 1;
BA_ "U_T6_MCA_MY2020_Tx" SG_ 932 VehOnCtl_D_Stat 1;
BA_ "U_CD542_MY2021_Tx" SG_ 932 VehOnCtl_D_Stat 1;
BA_ "U_U55X_MY2022_Tx" SG_ 932 VehOnCtl_D_Stat 1;
BA_ "U_CD764_MY2022_Tx" SG_ 932 VehOnCtl_D_Stat 1;
BA_ "U_T6_MCA_MY2020_Rx" SG_ 932 VehOnSrc2_D_Stat 1;
BA_ "U_U55X_MY2022_Rx" SG_ 932 VehOnSrc2_D_Stat 1;
BA_ "U_CD764_MY2022_Rx" SG_ 932 VehOnSrc2_D_Stat 1;
BA_ "ECGUsedRxSignal" SG_ 932 VehOnSrc2_D_Stat 1;
BA_ "U_CD542_MY2021_Rx" SG_ 932 VehOnSrc2_D_Stat 1;
BA_ "U_T6_MCA_MY2020_Tx" SG_ 932 VehOnSrc2_D_Stat 1;
BA_ "U_CD542_MY2021_Tx" SG_ 932 VehOnSrc2_D_Stat 1;
BA_ "U_U55X_MY2022_Tx" SG_ 932 VehOnSrc2_D_Stat 1;
BA_ "U_CD764_MY2022_Tx" SG_ 932 VehOnSrc2_D_Stat 1;
BA_ "ContentDependant" SG_ 932 CanMsg3A4_No_Crc 1;
BA_ "MetaData" SG_ 932 CanMsg3A4_No_Crc 1;
BA_ "U_T6_MCA_MY2020_Rx" SG_ 932 CanMsg3A4_No_Crc 1;
BA_ "ECGUsedRxSignal" SG_ 932 CanMsg3A4_No_Crc 1;
BA_ "U_CD542_MY2021_Rx" SG_ 932 CanMsg3A4_No_Crc 1;
BA_ "U_U55X_MY2022_Rx" SG_ 932 CanMsg3A4_No_Crc 1;
BA_ "U_CD764_MY2022_Rx" SG_ 932 CanMsg3A4_No_Crc 1;
BA_ "U_T6_MCA_MY2020_Tx" SG_ 932 CanMsg3A4_No_Crc 1;
BA_ "U_CD542_MY2021_Tx" SG_ 932 CanMsg3A4_No_Crc 1;
BA_ "U_U55X_MY2022_Tx" SG_ 932 CanMsg3A4_No_Crc 1;
BA_ "U_CD764_MY2022_Tx" SG_ 932 CanMsg3A4_No_Crc 1;
BA_ "ContentDependant" SG_ 932 CanMsg3A4_No_Cnt 1;
BA_ "MetaData" SG_ 932 CanMsg3A4_No_Cnt 1;
BA_ "U_T6_MCA_MY2020_Rx" SG_ 932 CanMsg3A4_No_Cnt 1;
BA_ "ECGUsedRxSignal" SG_ 932 CanMsg3A4_No_Cnt 1;
BA_ "U_CD542_MY2021_Rx" SG_ 932 CanMsg3A4_No_Cnt 1;
BA_ "U_U55X_MY2022_Rx" SG_ 932 CanMsg3A4_No_Cnt 1;
BA_ "U_CD764_MY2022_Rx" SG_ 932 CanMsg3A4_No_Cnt 1;
BA_ "U_T6_MCA_MY2020_Tx" SG_ 932 CanMsg3A4_No_Cnt 1;
BA_ "U_CD542_MY2021_Tx" SG_ 932 CanMsg3A4_No_Cnt 1;
BA_ "U_U55X_MY2022_Tx" SG_ 932 CanMsg3A4_No_Cnt 1;
BA_ "U_CD764_MY2022_Tx" SG_ 932 CanMsg3A4_No_Cnt 1;
BA_ "U_T6_MCA_MY2020_Rx" SG_ 885 BattULoChrg_D_RqOta 1;
BA_ "U_CD542_MY2021_Rx" SG_ 885 BattULoChrg_D_RqOta 1;
BA_ "U_CD764_MY2022_Rx" SG_ 885 BattULoChrg_D_RqOta 1;
BA_ "U_T6_MCA_MY2020_Tx" SG_ 885 BattULoChrg_D_RqOta 1;
BA_ "ECGUsedTxSignal" SG_ 885 BattULoChrg_D_RqOta 1;
BA_ "U_CD542_MY2021_Tx" SG_ 885 BattULoChrg_D_RqOta 1;
BA_ "U_U55X_MY2022_Tx" SG_ 885 BattULoChrg_D_RqOta 1;
BA_ "U_CD764_MY2022_Tx" SG_ 885 BattULoChrg_D_RqOta 1;
BA_ "U_T6_MCA_MY2020_Tx" SG_ 885 VehStrtInhbt_T_Dsply 1;
BA_ "ECGUsedTxSignal" SG_ 885 VehStrtInhbt_T_Dsply 1;
BA_ "U_CD542_MY2021_Tx" SG_ 885 VehStrtInhbt_T_Dsply 1;
BA_ "U_U55X_MY2022_Tx" SG_ 885 VehStrtInhbt_T_Dsply 1;
BA_ "U_CD764_MY2022_Tx" SG_ 885 VehStrtInhbt_T_Dsply 1;
BA_ "U_T6_MCA_MY2020_Tx" SG_ 885 VehStrtInhbt_D_Dsply 1;
BA_ "ECGUsedTxSignal" SG_ 885 VehStrtInhbt_D_Dsply 1;
BA_ "U_CD542_MY2021_Tx" SG_ 885 VehStrtInhbt_D_Dsply 1;
BA_ "U_U55X_MY2022_Tx" SG_ 885 VehStrtInhbt_D_Dsply 1;
BA_ "U_CD764_MY2022_Tx" SG_ 885 VehStrtInhbt_D_Dsply 1;
BA_ "U_T6_MCA_MY2020_Rx" SG_ 885 VehOnRqstr_D_Stat 1;
BA_ "U_CD542_MY2021_Rx" SG_ 885 VehOnRqstr_D_Stat 1;
BA_ "U_U55X_MY2022_Rx" SG_ 885 VehOnRqstr_D_Stat 1;
BA_ "U_CD764_MY2022_Rx" SG_ 885 VehOnRqstr_D_Stat 1;
BA_ "U_T6_MCA_MY2020_Tx" SG_ 885 VehOnRqstr_D_Stat 1;
BA_ "ECGUsedTxSignal" SG_ 885 VehOnRqstr_D_Stat 1;
BA_ "U_CD542_MY2021_Tx" SG_ 885 VehOnRqstr_D_Stat 1;
BA_ "U_U55X_MY2022_Tx" SG_ 885 VehOnRqstr_D_Stat 1;
BA_ "U_CD764_MY2022_Tx" SG_ 885 VehOnRqstr_D_Stat 1;
BA_ "U_T6_MCA_MY2020_Rx" SG_ 885 VehStrtInhbt_D_RqCld 1;
BA_ "U_CD542_MY2021_Rx" SG_ 885 VehStrtInhbt_D_RqCld 1;
BA_ "U_CD764_MY2022_Rx" SG_ 885 VehStrtInhbt_D_RqCld 1;
BA_ "U_T6_MCA_MY2020_Tx" SG_ 885 VehStrtInhbt_D_RqCld 1;
BA_ "ECGUsedTxSignal" SG_ 885 VehStrtInhbt_D_RqCld 1;
BA_ "U_CD542_MY2021_Tx" SG_ 885 VehStrtInhbt_D_RqCld 1;
BA_ "U_U55X_MY2022_Tx" SG_ 885 VehStrtInhbt_D_RqCld 1;
BA_ "U_CD764_MY2022_Tx" SG_ 885 VehStrtInhbt_D_RqCld 1;
BA_ "U_T6_MCA_MY2020_Rx" SG_ 885 VehOn_D_RqCld 1;
BA_ "U_CD542_MY2021_Rx" SG_ 885 VehOn_D_RqCld 1;
BA_ "U_U55X_MY2022_Rx" SG_ 885 VehOn_D_RqCld 1;
BA_ "U_CD764_MY2022_Rx" SG_ 885 VehOn_D_RqCld 1;
BA_ "U_T6_MCA_MY2020_Tx" SG_ 885 VehOn_D_RqCld 1;
BA_ "ECGUsedTxSignal" SG_ 885 VehOn_D_RqCld 1;
BA_ "U_CD542_MY2021_Tx" SG_ 885 VehOn_D_RqCld 1;
BA_ "U_U55X_MY2022_Tx" SG_ 885 VehOn_D_RqCld 1;
BA_ "U_CD764_MY2022_Tx" SG_ 885 VehOn_D_RqCld 1;
BA_ "MetaData" SG_ 885 CanMsg375_No_Cnt 1;
BA_ "U_T6_MCA_MY2020_Rx" SG_ 885 CanMsg375_No_Cnt 1;
BA_ "U_CD542_MY2021_Rx" SG_ 885 CanMsg375_No_Cnt 1;
BA_ "U_U55X_MY2022_Rx" SG_ 885 CanMsg375_No_Cnt 1;
BA_ "U_CD764_MY2022_Rx" SG_ 885 CanMsg375_No_Cnt 1;
BA_ "U_T6_MCA_MY2020_Tx" SG_ 885 CanMsg375_No_Cnt 1;
BA_ "ECGUsedTxSignal" SG_ 885 CanMsg375_No_Cnt 1;
BA_ "U_CD542_MY2021_Tx" SG_ 885 CanMsg375_No_Cnt 1;
BA_ "U_U55X_MY2022_Tx" SG_ 885 CanMsg375_No_Cnt 1;
BA_ "U_CD764_MY2022_Tx" SG_ 885 CanMsg375_No_Cnt 1;
BA_ "MetaData" SG_ 885 CanMsg375_No_Crc 1;
BA_ "U_T6_MCA_MY2020_Rx" SG_ 885 CanMsg375_No_Crc 1;
BA_ "U_CD542_MY2021_Rx" SG_ 885 CanMsg375_No_Crc 1;
BA_ "U_U55X_MY2022_Rx" SG_ 885 CanMsg375_No_Crc 1;
BA_ "U_CD764_MY2022_Rx" SG_ 885 CanMsg375_No_Crc 1;
BA_ "U_T6_MCA_MY2020_Tx" SG_ 885 CanMsg375_No_Crc 1;
BA_ "ECGUsedTxSignal" SG_ 885 CanMsg375_No_Crc 1;
BA_ "U_CD542_MY2021_Tx" SG_ 885 CanMsg375_No_Crc 1;
BA_ "U_U55X_MY2022_Tx" SG_ 885 CanMsg375_No_Crc 1;
BA_ "U_CD764_MY2022_Tx" SG_ 885 CanMsg375_No_Crc 1;
BA_ "U_T6_MCA_MY2020_Rx" SG_ 885 OtaActv_D_Stat 1;
BA_ "U_CD542_MY2021_Rx" SG_ 885 OtaActv_D_Stat 1;
BA_ "U_U55X_MY2022_Rx" SG_ 885 OtaActv_D_Stat 1;
BA_ "U_CD764_MY2022_Rx" SG_ 885 OtaActv_D_Stat 1;
BA_ "U_T6_MCA_MY2020_Tx" SG_ 885 OtaActv_D_Stat 1;
BA_ "ECGUsedTxSignal" SG_ 885 OtaActv_D_Stat 1;
BA_ "U_CD542_MY2021_Tx" SG_ 885 OtaActv_D_Stat 1;
BA_ "U_U55X_MY2022_Tx" SG_ 885 OtaActv_D_Stat 1;
BA_ "U_CD764_MY2022_Tx" SG_ 885 OtaActv_D_Stat 1;
BA_ "WakeupSignal" SG_ 1160 ReFuelSwtchStat_D_Actl2 1;
BA_ "GenSigSendType" SG_ 1160 ReFuelSwtchStat_D_Actl2 3;
BA_ "ECGUsedTxSignal" SG_ 1160 ReFuelSwtchStat_D_Actl2 1;
BA_ "U_CD764_MY2022_Tx" SG_ 1160 ReFuelSwtchStat_D_Actl2 1;
BA_ "GenSigSendType" SG_ 1160 DgtlCommPncReset_B_Req 3;
BA_ "ECGUsedTxSignal" SG_ 1160 DgtlCommPncReset_B_Req 1;
BA_ "U_CD542_MY2021_Tx" SG_ 1160 DgtlCommPncReset_B_Req 1;
BA_ "U_U55X_MY2022_Tx" SG_ 1160 DgtlCommPncReset_B_Req 1;
BA_ "U_CD764_MY2022_Tx" SG_ 1160 DgtlCommPncReset_B_Req 1;
BA_ "GenSigSendType" SG_ 1160 DgtlCommPnc_D_Rq 3;
BA_ "ECGUsedTxSignal" SG_ 1160 DgtlCommPnc_D_Rq 1;
BA_ "U_CD542_MY2021_Tx" SG_ 1160 DgtlCommPnc_D_Rq 1;
BA_ "U_U55X_MY2022_Tx" SG_ 1160 DgtlCommPnc_D_Rq 1;
BA_ "U_CD764_MY2022_Tx" SG_ 1160 DgtlCommPnc_D_Rq 1;
BA_ "GenSigSendType" SG_ 1160 PwSustnRdata_B_RqTelem 3;
BA_ "U_CD542_MY2021_Rx" SG_ 1160 PwSustnRdata_B_RqTelem 1;
BA_ "ECGUsedTxSignal" SG_ 1160 PwSustnRdata_B_RqTelem 1;
BA_ "U_CD542_MY2021_Tx" SG_ 1160 PwSustnRdata_B_RqTelem 1;
BA_ "U_U55X_MY2022_Tx" SG_ 1160 PwSustnRdata_B_RqTelem 1;
BA_ "U_CD764_MY2022_Tx" SG_ 1160 PwSustnRdata_B_RqTelem 1;
BA_ "GenSigSendType" SG_ 1160 DataMntrSustn_B_Rq 3;
BA_ "U_CD542_MY2021_Rx" SG_ 1160 DataMntrSustn_B_Rq 1;
BA_ "ECGUsedTxSignal" SG_ 1160 DataMntrSustn_B_Rq 1;
BA_ "U_CD542_MY2021_Tx" SG_ 1160 DataMntrSustn_B_Rq 1;
BA_ "U_U55X_MY2022_Tx" SG_ 1160 DataMntrSustn_B_Rq 1;
BA_ "U_CD764_MY2022_Tx" SG_ 1160 DataMntrSustn_B_Rq 1;
BA_ "U_U55X_MY2022_Rx" SG_ 895 TurnLght_D_RqRmtCtl 1;
BA_ "U_U55X_MY2022_Rx" SG_ 895 RmtCtlRngSet_D_Rq 1;
BA_ "U_U55X_MY2022_Rx" SG_ 895 RmtCtlRes_D_Stat 1;
BA_ "U_U55X_MY2022_Rx" SG_ 895 RmtCtlKeyPoll_D_Rq 1;
BA_ "MetaData" SG_ 895 RmtCtlDStat_No_Cs 1;
BA_ "U_U55X_MY2022_Rx" SG_ 895 RmtCtlDStat_No_Cs 1;
BA_ "MetaData" SG_ 895 RmtCtlDStat_No_Cnt 1;
BA_ "U_U55X_MY2022_Rx" SG_ 895 RmtCtlDStat_No_Cnt 1;
BA_ "U_U55X_MY2022_Rx" SG_ 895 RmtCtlCntnsIn_B_Stat 1;
BA_ "WakeupSignal" SG_ 895 RmtCtl_D_Stat 1;
BA_ "U_U55X_MY2022_Rx" SG_ 895 RmtCtl_D_Stat 1;
BA_ "GenSigStartValueInteger" SG_ 515 PtIgnSwtch_D_Stat 2;
BA_ "GenSigStartValue" SG_ 515 PtIgnSwtch_D_Stat 2;
BA_ "U_CD542_MY2021_Rx" SG_ 515 PtIgnSwtch_D_Stat 1;
BA_ "U_CD764_MY2022_Rx" SG_ 515 PtIgnSwtch_D_Stat 1;
BA_ "GenSigSendType" SG_ 1119 CoolFanDcdc_D_Rq 3;
BA_ "U_CX727_MY2021_Rx" SG_ 1119 CoolFanDcdc_D_Rq 1;
BA_ "U_P702_MY2021_Rx" SG_ 1119 CoolFanDcdc_D_Rq 1;
BA_ "U_CD542_MY2021_Rx" SG_ 1119 CoolFanDcdc_D_Rq 1;
BA_ "U_CX727_MY2021_Tx" SG_ 1119 CoolFanDcdc_D_Rq 1;
BA_ "U_P702_MY2021_Tx" SG_ 1119 CoolFanDcdc_D_Rq 1;
BA_ "U_CD542_MY2021_Tx" SG_ 1119 CoolFanDcdc_D_Rq 1;
BA_ "GenSigSendType" SG_ 1119 DcdcClntFlw_D_Rq 3;
BA_ "U_CX727_MY2021_Rx" SG_ 1119 DcdcClntFlw_D_Rq 1;
BA_ "U_P702_MY2021_Rx" SG_ 1119 DcdcClntFlw_D_Rq 1;
BA_ "U_CD542_MY2021_Rx" SG_ 1119 DcdcClntFlw_D_Rq 1;
BA_ "U_CX727_MY2021_Tx" SG_ 1119 DcdcClntFlw_D_Rq 1;
BA_ "U_P702_MY2021_Tx" SG_ 1119 DcdcClntFlw_D_Rq 1;
BA_ "U_CD542_MY2021_Tx" SG_ 1119 DcdcClntFlw_D_Rq 1;
BA_ "GenSigSendType" SG_ 1827 TesterPhysicalReqBECMB_EPM 3;
BA_ "U_CX727_MY2021_Rx" SG_ 1827 TesterPhysicalReqBECMB_EPM 1;
BA_ "GenSigSendType" SG_ 1835 TesterPhysicalResBECMB_EPM 3;
BA_ "U_CX727_MY2021_Tx" SG_ 1835 TesterPhysicalResBECMB_EPM 1;
BA_ "GenSigStartValueInteger" SG_ 1110 RstrnMdulePw_D_Falt 1;
BA_ "GenSigStartValue" SG_ 1110 RstrnMdulePw_D_Falt 1;
BA_ "U_CX727_MY2021_Tx" SG_ 1110 RstrnMdulePw_D_Falt 1;
BA_ "U_P702_MY2021_Tx" SG_ 1110 RstrnMdulePw_D_Falt 1;
BA_ "U_T6_MCA_MY2020_Tx" SG_ 1110 RstrnMdulePw_D_Falt 1;
BA_ "U_U55X_MY2022_Tx" SG_ 1110 RstrnMdulePw_D_Falt 1;
BA_ "U_CD764_MY2022_Tx" SG_ 1110 RstrnMdulePw_D_Falt 1;
BA_ "GenSigSendType" SG_ 1036 PdstrnAlrt_B_Falt 3;
BA_ "U_CX727_MY2021_Tx" SG_ 1036 PdstrnAlrt_B_Falt 1;
BA_ "U_P702_MY2021_Tx" SG_ 1036 PdstrnAlrt_B_Falt 1;
BA_ "U_CD542_MY2021_Tx" SG_ 1036 PdstrnAlrt_B_Falt 1;
BA_ "GenSigStartValueInteger" SG_ 1152 StopStrtVThres_D_Stat 1;
BA_ "GenSigStartValue" SG_ 1152 StopStrtVThres_D_Stat 1;
BA_ "GenSigStartValueInteger" SG_ 1152 VehElEff_No_Avg 126;
BA_ "GenSigStartValue" SG_ 1152 VehElEff_No_Avg 126;
BA_ "U_CX727_MY2021_Rx" SG_ 1152 DcdcOn_B_Rq 1;
BA_ "U_P702_MY2021_Rx" SG_ 1152 DcdcOn_B_Rq 1;
BA_ "U_CD542_MY2021_Rx" SG_ 1152 DcdcOn_B_Rq 1;
BA_ "U_P702_MY2021_Rx" SG_ 1152 BattTracDiagClr_B_Stat 1;
BA_ "U_CD542_MY2021_Rx" SG_ 1152 BattTracDiagClr_B_Stat 1;
BA_ "U_CX727_MY2021_Rx" SG_ 1152 ULoBattSpprtSustn_B_Rq 1;
BA_ "U_CD542_MY2021_Rx" SG_ 1152 ULoBattSpprtSustn_B_Rq 1;
BA_ "U_P702_MY2021_Rx" SG_ 1152 ULoBattSpprtSustn_B_Rq 1;
BA_ "U_T6_MCA_MY2020_Rx" SG_ 1152 ULoBattSpprtSustn_B_Rq 1;
BA_ "U_U55X_MY2022_Rx" SG_ 1152 ULoBattSpprtSustn_B_Rq 1;
BA_ "U_CD764_MY2022_Rx" SG_ 1152 ULoBattSpprtSustn_B_Rq 1;
BA_ "GenSigStartValueInteger" SG_ 1458 BECMB_GWOnBoardTester 255;
BA_ "ContentDependant" SG_ 1458 BECMB_GWOnBoardTester 1;
BA_ "GenSigStartValue" SG_ 1458 BECMB_GWOnBoardTester 255;
BA_ "U_CX727_MY2021_Rx" SG_ 1458 BECMB_GWOnBoardTester 1;
BA_ "U_P702_MY2021_Rx" SG_ 1458 BECMB_GWOnBoardTester 1;
BA_ "U_T6_MCA_MY2020_Rx" SG_ 1458 BECMB_GWOnBoardTester 1;
BA_ "U_CD542_MY2021_Rx" SG_ 1458 BECMB_GWOnBoardTester 1;
BA_ "U_U55X_MY2022_Rx" SG_ 1458 BECMB_GWOnBoardTester 1;
BA_ "U_CD764_MY2022_Rx" SG_ 1458 BECMB_GWOnBoardTester 1;
BA_ "U_CX727_MY2021_Tx" SG_ 1458 BECMB_GWOnBoardTester 1;
BA_ "GenSigStartValueInteger" SG_ 1458 BECMB_GWNMProxy 255;
BA_ "ContentDependant" SG_ 1458 BECMB_GWNMProxy 1;
BA_ "GenSigStartValue" SG_ 1458 BECMB_GWNMProxy 255;
BA_ "U_CX727_MY2021_Rx" SG_ 1458 BECMB_GWNMProxy 1;
BA_ "U_P702_MY2021_Rx" SG_ 1458 BECMB_GWNMProxy 1;
BA_ "U_T6_MCA_MY2020_Rx" SG_ 1458 BECMB_GWNMProxy 1;
BA_ "U_CD542_MY2021_Rx" SG_ 1458 BECMB_GWNMProxy 1;
BA_ "U_U55X_MY2022_Rx" SG_ 1458 BECMB_GWNMProxy 1;
BA_ "U_CD764_MY2022_Rx" SG_ 1458 BECMB_GWNMProxy 1;
BA_ "U_CX727_MY2021_Tx" SG_ 1458 BECMB_GWNMProxy 1;
BA_ "GenSigStartValueInteger" SG_ 1458 BECMB_AutoSarNMNodeId 178;
BA_ "ContentDependant" SG_ 1458 BECMB_AutoSarNMNodeId 1;
BA_ "GenSigStartValue" SG_ 1458 BECMB_AutoSarNMNodeId 178;
BA_ "U_CX727_MY2021_Rx" SG_ 1458 BECMB_AutoSarNMNodeId 1;
BA_ "U_P702_MY2021_Rx" SG_ 1458 BECMB_AutoSarNMNodeId 1;
BA_ "U_T6_MCA_MY2020_Rx" SG_ 1458 BECMB_AutoSarNMNodeId 1;
BA_ "U_CD542_MY2021_Rx" SG_ 1458 BECMB_AutoSarNMNodeId 1;
BA_ "U_U55X_MY2022_Rx" SG_ 1458 BECMB_AutoSarNMNodeId 1;
BA_ "U_CD764_MY2022_Rx" SG_ 1458 BECMB_AutoSarNMNodeId 1;
BA_ "U_CX727_MY2021_Tx" SG_ 1458 BECMB_AutoSarNMNodeId 1;
BA_ "ContentDependant" SG_ 1458 BECMB_AutoSarNMControl 1;
BA_ "U_CX727_MY2021_Rx" SG_ 1458 BECMB_AutoSarNMControl 1;
BA_ "U_P702_MY2021_Rx" SG_ 1458 BECMB_AutoSarNMControl 1;
BA_ "U_T6_MCA_MY2020_Rx" SG_ 1458 BECMB_AutoSarNMControl 1;
BA_ "U_CD542_MY2021_Rx" SG_ 1458 BECMB_AutoSarNMControl 1;
BA_ "U_U55X_MY2022_Rx" SG_ 1458 BECMB_AutoSarNMControl 1;
BA_ "U_CD764_MY2022_Rx" SG_ 1458 BECMB_AutoSarNMControl 1;
BA_ "U_CX727_MY2021_Tx" SG_ 1458 BECMB_AutoSarNMControl 1;
BA_ "GenSigStartValueInteger" SG_ 1458 BECMB_AutoSarNMReserved4 255;
BA_ "ContentDependant" SG_ 1458 BECMB_AutoSarNMReserved4 1;
BA_ "GenSigStartValue" SG_ 1458 BECMB_AutoSarNMReserved4 255;
BA_ "U_CX727_MY2021_Rx" SG_ 1458 BECMB_AutoSarNMReserved4 1;
BA_ "U_P702_MY2021_Rx" SG_ 1458 BECMB_AutoSarNMReserved4 1;
BA_ "U_T6_MCA_MY2020_Rx" SG_ 1458 BECMB_AutoSarNMReserved4 1;
BA_ "U_CD542_MY2021_Rx" SG_ 1458 BECMB_AutoSarNMReserved4 1;
BA_ "U_U55X_MY2022_Rx" SG_ 1458 BECMB_AutoSarNMReserved4 1;
BA_ "U_CD764_MY2022_Rx" SG_ 1458 BECMB_AutoSarNMReserved4 1;
BA_ "U_CX727_MY2021_Tx" SG_ 1458 BECMB_AutoSarNMReserved4 1;
BA_ "GenSigStartValueInteger" SG_ 1458 BECMB_AutoSarNMReserved3 255;
BA_ "ContentDependant" SG_ 1458 BECMB_AutoSarNMReserved3 1;
BA_ "GenSigStartValue" SG_ 1458 BECMB_AutoSarNMReserved3 255;
BA_ "U_CX727_MY2021_Rx" SG_ 1458 BECMB_AutoSarNMReserved3 1;
BA_ "U_P702_MY2021_Rx" SG_ 1458 BECMB_AutoSarNMReserved3 1;
BA_ "U_T6_MCA_MY2020_Rx" SG_ 1458 BECMB_AutoSarNMReserved3 1;
BA_ "U_CD542_MY2021_Rx" SG_ 1458 BECMB_AutoSarNMReserved3 1;
BA_ "U_U55X_MY2022_Rx" SG_ 1458 BECMB_AutoSarNMReserved3 1;
BA_ "U_CD764_MY2022_Rx" SG_ 1458 BECMB_AutoSarNMReserved3 1;
BA_ "U_CX727_MY2021_Tx" SG_ 1458 BECMB_AutoSarNMReserved3 1;
BA_ "GenSigStartValueInteger" SG_ 1458 BECMB_AutoSarNMReserved2 255;
BA_ "ContentDependant" SG_ 1458 BECMB_AutoSarNMReserved2 1;
BA_ "GenSigStartValue" SG_ 1458 BECMB_AutoSarNMReserved2 255;
BA_ "U_CX727_MY2021_Rx" SG_ 1458 BECMB_AutoSarNMReserved2 1;
BA_ "U_P702_MY2021_Rx" SG_ 1458 BECMB_AutoSarNMReserved2 1;
BA_ "U_T6_MCA_MY2020_Rx" SG_ 1458 BECMB_AutoSarNMReserved2 1;
BA_ "U_CD542_MY2021_Rx" SG_ 1458 BECMB_AutoSarNMReserved2 1;
BA_ "U_U55X_MY2022_Rx" SG_ 1458 BECMB_AutoSarNMReserved2 1;
BA_ "U_CD764_MY2022_Rx" SG_ 1458 BECMB_AutoSarNMReserved2 1;
BA_ "U_CX727_MY2021_Tx" SG_ 1458 BECMB_AutoSarNMReserved2 1;
BA_ "GenSigStartValueInteger" SG_ 1458 BECMB_AutoSarNMReserved1 255;
BA_ "ContentDependant" SG_ 1458 BECMB_AutoSarNMReserved1 1;
BA_ "GenSigStartValue" SG_ 1458 BECMB_AutoSarNMReserved1 255;
BA_ "U_CX727_MY2021_Rx" SG_ 1458 BECMB_AutoSarNMReserved1 1;
BA_ "U_P702_MY2021_Rx" SG_ 1458 BECMB_AutoSarNMReserved1 1;
BA_ "U_T6_MCA_MY2020_Rx" SG_ 1458 BECMB_AutoSarNMReserved1 1;
BA_ "U_CD542_MY2021_Rx" SG_ 1458 BECMB_AutoSarNMReserved1 1;
BA_ "U_U55X_MY2022_Rx" SG_ 1458 BECMB_AutoSarNMReserved1 1;
BA_ "U_CD764_MY2022_Rx" SG_ 1458 BECMB_AutoSarNMReserved1 1;
BA_ "U_CX727_MY2021_Tx" SG_ 1458 BECMB_AutoSarNMReserved1 1;
BA_ "GenSigStartValueInteger" SG_ 126 StePinRelInit_An_Sns 65535;
BA_ "ContentDependant" SG_ 126 StePinRelInit_An_Sns 1;
BA_ "GenSigStartValue" SG_ 126 StePinRelInit_An_Sns 65535;
BA_ "GenSigStartValueInteger" SG_ 126 StePinCompAnEst_D_Qf 1;
BA_ "MetaData" SG_ 126 StePinCompAnEst_D_Qf 1;
BA_ "GenSigStartValue" SG_ 126 StePinCompAnEst_D_Qf 1;
BA_ "U_U55X_MY2022_Rx" SG_ 126 StePinCompAnEst_D_Qf 1;
BA_ "U_CX727_MY2021_Rx" SG_ 126 StePinCompAnEst_D_Qf 1;
BA_ "U_P702_MY2021_Rx" SG_ 126 StePinCompAnEst_D_Qf 1;
BA_ "U_T6_MCA_MY2020_Rx" SG_ 126 StePinCompAnEst_D_Qf 1;
BA_ "U_CD542_MY2021_Rx" SG_ 126 StePinCompAnEst_D_Qf 1;
BA_ "U_CD764_MY2022_Rx" SG_ 126 StePinCompAnEst_D_Qf 1;
BA_ "GenSigStartValueInteger" SG_ 126 StePinComp_An_Est 16000;
BA_ "U_U55X_MY2022_Rx" SG_ 126 StePinComp_An_Est 1;
BA_ "U_CX727_MY2021_Rx" SG_ 126 StePinComp_An_Est 1;
BA_ "U_P702_MY2021_Rx" SG_ 126 StePinComp_An_Est 1;
BA_ "U_T6_MCA_MY2020_Rx" SG_ 126 StePinComp_An_Est 1;
BA_ "U_CD542_MY2021_Rx" SG_ 126 StePinComp_An_Est 1;
BA_ "U_CD764_MY2022_Rx" SG_ 126 StePinComp_An_Est 1;
BA_ "ContentDependant" SG_ 126 StePinAn_No_Cs 1;
BA_ "MetaData" SG_ 126 StePinAn_No_Cs 1;
BA_ "MetaData" SG_ 126 StePinAn_No_Cnt 1;
BA_ "GenSigSendType" SG_ 1872 TesterPhysicalReqPACM 3;
BA_ "U_CX727_MY2021_Rx" SG_ 1872 TesterPhysicalReqPACM 1;
BA_ "U_P702_MY2021_Rx" SG_ 1872 TesterPhysicalReqPACM 1;
BA_ "U_CD542_MY2021_Rx" SG_ 1872 TesterPhysicalReqPACM 1;
BA_ "GenSigSendType" SG_ 1880 TesterPhysicalResPACM 3;
BA_ "U_CX727_MY2021_Tx" SG_ 1880 TesterPhysicalResPACM 1;
BA_ "U_P702_MY2021_Tx" SG_ 1880 TesterPhysicalResPACM 1;
BA_ "U_CD542_MY2021_Tx" SG_ 1880 TesterPhysicalResPACM 1;
BA_ "ContentDependant" SG_ 118 SteWhlCompAnEst_D_Qf 1;
BA_ "MetaData" SG_ 118 SteWhlCompAnEst_D_Qf 1;
BA_ "U_CX727_MY2021_Rx" SG_ 118 SteWhlCompAnEst_D_Qf 1;
BA_ "U_P702_MY2021_Rx" SG_ 118 SteWhlCompAnEst_D_Qf 1;
BA_ "U_T6_MCA_MY2020_Rx" SG_ 118 SteWhlCompAnEst_D_Qf 1;
BA_ "U_CD542_MY2021_Rx" SG_ 118 SteWhlCompAnEst_D_Qf 1;
BA_ "U_U55X_MY2022_Rx" SG_ 118 SteWhlCompAnEst_D_Qf 1;
BA_ "U_CD764_MY2022_Rx" SG_ 118 SteWhlCompAnEst_D_Qf 1;
BA_ "ContentDependant" SG_ 118 SteWhlComp_An_Est 1;
BA_ "U_CX727_MY2021_Rx" SG_ 118 SteWhlComp_An_Est 1;
BA_ "U_P702_MY2021_Rx" SG_ 118 SteWhlComp_An_Est 1;
BA_ "U_T6_MCA_MY2020_Rx" SG_ 118 SteWhlComp_An_Est 1;
BA_ "U_CD542_MY2021_Rx" SG_ 118 SteWhlComp_An_Est 1;
BA_ "U_U55X_MY2022_Rx" SG_ 118 SteWhlComp_An_Est 1;
BA_ "U_CD764_MY2022_Rx" SG_ 118 SteWhlComp_An_Est 1;
BA_ "GenSigStartValueInteger" SG_ 118 DrvSte_Tq_Rq 128;
BA_ "U_CX727_MY2021_Rx" SG_ 118 EmgcyBrkLamp_D_Rq 1;
BA_ "U_P702_MY2021_Rx" SG_ 118 EmgcyBrkLamp_D_Rq 1;
BA_ "U_T6_MCA_MY2020_Rx" SG_ 118 EmgcyBrkLamp_D_Rq 1;
BA_ "U_CD542_MY2021_Rx" SG_ 118 EmgcyBrkLamp_D_Rq 1;
BA_ "U_U55X_MY2022_Rx" SG_ 118 EmgcyBrkLamp_D_Rq 1;
BA_ "U_CD764_MY2022_Rx" SG_ 118 EmgcyBrkLamp_D_Rq 1;
BA_ "U_P702_MY2021_Rx" SG_ 118 StopLamp_B_RqBrk 1;
BA_ "U_T6_MCA_MY2020_Rx" SG_ 118 StopLamp_B_RqBrk 1;
BA_ "U_U55X_MY2022_Rx" SG_ 118 StopLamp_B_RqBrk 1;
BA_ "U_CX727_MY2021_Rx" SG_ 118 StopLamp_B_RqBrk 1;
BA_ "U_CD542_MY2021_Rx" SG_ 118 StopLamp_B_RqBrk 1;
BA_ "U_CD764_MY2022_Rx" SG_ 118 StopLamp_B_RqBrk 1;
VAL_ 1179 BattTracCell60_U_Actl 4095 "Fault" 4094 "NoDataExists" ;
VAL_ 1179 BattTracCell59_U_Actl 4095 "Fault" 4094 "NoDataExists" ;
VAL_ 1179 BattTracCell58_U_Actl 4095 "Fault" 4094 "NoDataExists" ;
VAL_ 1179 BattTracCell57_U_Actl 4095 "Fault" 4094 "NoDataExists" ;
VAL_ 1179 BattTracCell56_U_Actl 4095 "Fault" 4094 "NoDataExists" ;
VAL_ 1178 BattTracCell55_U_Actl 4095 "Fault" 4094 "NoDataExists" ;
VAL_ 1178 BattTracCell54_U_Actl 4095 "Fault" 4094 "NoDataExists" ;
VAL_ 1178 BattTracCell53_U_Actl 4095 "Fault" 4094 "NoDataExists" ;
VAL_ 1178 BattTracCell52_U_Actl 4095 "Fault" 4094 "NoDataExists" ;
VAL_ 1178 BattTracCell51_U_Actl 4095 "Fault" 4094 "NoDataExists" ;
VAL_ 1177 BattTracCell50_U_Actl 4095 "Fault" 4094 "NoDataExists" ;
VAL_ 1177 BattTracCell49_U_Actl 4095 "Fault" 4094 "NoDataExists" ;
VAL_ 1177 BattTracCell48_U_Actl 4095 "Fault" 4094 "NoDataExists" ;
VAL_ 1177 BattTracCell47_U_Actl 4095 "Fault" 4094 "NoDataExists" ;
VAL_ 1177 BattTracCell46_U_Actl 4095 "Fault" 4094 "NoDataExists" ;
VAL_ 1168 BattTracCell05_U_Actl 4095 "Fault" 4094 "NoDataExists" ;
VAL_ 1168 BattTracCell04_U_Actl 4095 "Fault" 4094 "NoDataExists" ;
VAL_ 1168 BattTracCell03_U_Actl 4095 "Fault" 4094 "NoDataExists" ;
VAL_ 1168 BattTracCell02_U_Actl 4095 "Fault" 4094 "NoDataExists" ;
VAL_ 1168 BattTracCell01_U_Actl 4095 "Fault" 4094 "NoDataExists" ;
VAL_ 1092 BattTracCell_U_Mx 16383 "Faulty" ;
VAL_ 1092 BattTracMnCell_Te_Actl 255 "Faulty" 254 "NoDataExists" ;
VAL_ 1092 BattTracInsAlrm_B_Stat 1 "Active" 0 "Inactive" ;
VAL_ 1092 BattTracUMx_B_Stat 1 "Active" 0 "Inactive" ;
VAL_ 1092 BattTracMxCell_Te_Actl 255 "Faulty" 254 "NoDataExists" ;
VAL_ 1092 BattTracEq_B_Actl 1 "Active" 0 "Inactive" ;
VAL_ 1092 BattTracCell_U_Mn 16383 "Faulty" ;
VAL_ 1092 BattTracUMn_B_Stat 1 "Active" 0 "Inactive" ;
VAL_ 1092 BattTracUAlrm_B_Stat 1 "Active" 0 "Inactive" ;
VAL_ 1092 BattTracInsltn_R_Actl 255 "Faulty" ;
VAL_ 606 BattTracThrml_D_Stat 15 "NotUsed_5" 14 "NotUsed_4" 13 "NotUsed_3" 12 "NotUsed_2" 11 "NotUsed_1" 10 "SysFill" 9 "AirPurge" 8 "VlvCalib" 7 "InActvHeaterCoreClntFlw" 6 "ActvHeaterCoreClntFlw" 5 "MxChlrClntFlw" 4 "ChlrClntFlw" 3 "RadClntFlwFan" 2 "RadClntFlwWoFan" 1 "ClntFlw" 0 "ThrmlSysOff" ;
VAL_ 606 ElVehLaterMde_D_Stat 3 "NotUsed" 2 "Available" 1 "NotAvailable" 0 "Null" ;
VAL_ 606 ElVehNowMde_D_Stat 3 "NotUsed" 2 "Available" 1 "NotAvailable" 0 "Null" ;
VAL_ 606 OnePdlDrvBrk_D_Rq 3 "Active_FbrkStandstillApply" 2 "Active_FbrkStopApply" 1 "Active_NoFbrkAllow" 0 "Inactive" ;
VAL_ 942 ApaOffOptnSel_B_Avail 1 "Available" 0 "NotAvailable" ;
VAL_ 942 PrkBrkElRleas_B_RqApa 1 "Yes" 0 "No" ;
VAL_ 942 ApaDrvRq2MsgTxt_D_Rq 15 "NotUsed_7" 14 "NotUsed_6" 13 "NotUsed_5" 12 "NotUsed_4" 11 "NotUsed_3" 10 "NotUsed_2" 9 "NotUsed_1" 8 "CloseDoor" 7 "TakeControl" 6 "ReleaseEpb" 5 "ReleaseSteering" 4 "ReleaseBrake" 3 "DriveBackward" 2 "DriveForward" 1 "Stop" 0 "NoRequest" ;
VAL_ 942 ApaDrvRq1MsgTxt_D_Rq 7 "NotUsed" 6 "ExitVehicle" 5 "PressApaButton" 4 "ShiftToP" 3 "ShiftToN" 2 "ShiftToD" 1 "ShiftToR" 0 "NoRequest" ;
VAL_ 942 ApaSys_D2_Stat 15 "NotUsed_5" 14 "NotUsed_4" 13 "NotUsed_3" 12 "NotUsed_2" 11 "NotUsed_1" 10 "NoSideSelectable" 9 "RightSideSelectable" 8 "LeftSideSelectable" 7 "BothSidesSelectable" 6 "Faulty" 5 "Finished" 4 "Cancelled" 3 "NotAvailable" 2 "Overspeed" 1 "Pause" 0 "NormalOperation" ;
VAL_ 942 ApaSlotTrgt_D_Stat 15 "NotUsed_7" 14 "NotUsed_6" 13 "NotUsed_5" 12 "NotUsed_4" 11 "NotUsed_3" 10 "NotUsed_2" 9 "NotUsed_1" 8 "Front" 7 "Rear" 6 "Right3" 5 "Right2" 4 "Right1" 3 "Left3" 2 "Left2" 1 "Left1" 0 "None" ;
VAL_ 942 ApaSlotOption_B_Avail 1 "Available" 0 "NotAvailable" ;
VAL_ 942 ApaSlotAlrtSet_B_Stat 1 "Enable" 0 "Disable" ;
VAL_ 942 ApaSlotAlrt_B_Rq 1 "True" 0 "False" ;
VAL_ 942 ApaRmtFeatSel_B_Avail 1 "Available" 0 "NotAvailable" ;
VAL_ 942 ApaParkOutSel_B_Avail 1 "Available" 0 "NotAvailable" ;
VAL_ 942 ApaParkInSel_B_Avail 1 "Available" 0 "NotAvailable" ;
VAL_ 942 ApaMsgTxt_D2_Stat 15 "ReducedFunction" 14 "TrailerFeatureNotAvailable" 13 "AcceleratorPedalInactive" 12 "SensorsBlocked" 11 "TrailerAttached" 10 "TcsDeactivated" 9 "WheelSlip" 8 "HighInclination" 7 "DoorOpen" 6 "SteeringInteraction" 5 "WrongDirection" 4 "SpeedLimitExceeded" 3 "BrakeEvent" 2 "ObstacleInPath" 1 "WaitForSteering" 0 "None" ;
VAL_ 942 ApaDynmcSlot_B_Stat 1 "On" 0 "Off" ;
VAL_ 942 ApaDisplayMode_D_Stat 3 "NotUsed" 2 "FullScreen" 1 "Menu" 0 "Off" ;
VAL_ 942 ApaControlMode_D_Stat 1 "Active" 0 "Inactive" ;
VAL_ 942 PrkAidAcsyRear_D_Stat 3 "NotUsed" 2 "On" 1 "Off" 0 "Null" ;
VAL_ 942 PrkAidAcsyFront_D_Stat 3 "NotUsed" 2 "On" 1 "Off" 0 "Null" ;
VAL_ 942 PrkAidDrvDir_D_Stat 7 "NotUsed_2" 6 "NotUsed_1" 5 "BackwardNegative" 4 "ForwardNegative" 3 "BackwardPositive" 2 "ForwardPositive" 1 "NoMotion" 0 "DirectionNotKnown" ;
VAL_ 757 SdarsAudioRtng_D_Stat 3 "NotUsed" 2 "APIMStereoOut" 1 "X40l2SStereoOut" 0 "NotDetermined" ;
VAL_ 757 SpkrStdRight_D_Stat 3 "Faulty" 2 "Normal" 1 "NotPresent" 0 "Null" ;
VAL_ 757 SpkrStdLeft_D_Stat 3 "Faulty" 2 "Normal" 1 "NotPresent" 0 "Null" ;
VAL_ 757 SpkrStdCntr_D_Stat 3 "Faulty" 2 "Normal" 1 "NotPresent" 0 "Null" ;
VAL_ 757 SDARS_ChipControl_St 7 "NotUsed_2" 6 "NotUsed_1" 5 "Ready" 4 "ResetInProgress" 3 "PowerDownInProgress" 2 "PowerUpInProgress" 1 "Off" 0 "Null" ;
VAL_ 757 ACU_AutoStoreResult_St 2 "No_Station_Found" 1 "Inactive" 0 "Invalid" ;
VAL_ 757 ACU_DirectTune_St 2 "Valid_Station" 1 "Invalid_Station" 0 "Invalid" ;
VAL_ 757 ACU_RadioSeekMode2_St 16 "ContAutoDown" 15 "ContAutoUp" 14 "PISeek" 13 "TpSeek" 12 "Autostore" 11 "PtySeekDown" 10 "PtySeekUp" 9 "ScanDown" 8 "ScanUp" 7 "ContManualDown" 6 "ContManualUp" 5 "ManSingleStepDown" 4 "ManSingleStepUp" 3 "AutoDown" 2 "AutoUp" 1 "SeekOff" 0 "Invalid" ;
VAL_ 757 ACU_CurrTUBand_St 10 "SAT2" 9 "SAT1" 8 "DAB2" 7 "DAB1" 6 "Fm3" 5 "AmAst" 4 "Am" 3 "FmAst" 2 "Fm2" 1 "Fm1" 0 "Invalid" 13 "reserved1" 15 "reserved_last" 12 "DAB3" 11 "SAT3" ;
VAL_ 1229 ExitNotClrRight_B_Stat 1 "True" 0 "False" ;
VAL_ 1229 ExitNotClrLeft_B_Stat 1 "True" 0 "False" ;
VAL_ 650 BptTglCnt_No_Rq 15 "Faulty" 14 "NoDataExists" ;
VAL_ 650 BptIsol_D_Stat 7 "Faulty" 6 "NoDataExists" 5 "NotUsed_3" 4 "NotUsed_2" 3 "NotUsed_1" 2 "Valid" 1 "Warning" 0 "Invalid" ;
VAL_ 650 Bpt_D_StatEvse 15 "Faulty" 14 "NoDataExists" 13 "NotUsed_6" 12 "NotUsed_5" 11 "NotUsed_4" 10 "NotUsed_3" 9 "NotUsed_2" 8 "NotUsed_1" 7 "EvseFault" 6 "EvseEnergyTransferActive" 5 "EvsePreChargeReady" 4 "EvseBptReady" 3 "ConnectionTglNotConfirmed" 2 "ConnectionTglConfirmed" 1 "Initialization" 0 "NotReady" ;
VAL_ 650 BptTgl_D_Rq 3 "Faulty" 2 "NoDataExists" 1 "Request" 0 "NoRequest" ;
VAL_ 650 BattTracIsoDis_D_RqBpt 3 "Faulty" 2 "NoDataExists" 1 "Yes" 0 "No" ;
VAL_ 655 EvseChrgOutHi_U_ActlBpt 1023 "Faulty" 1022 "NoDataExists" ;
VAL_ 655 EvseChrgOutHi_I_ActlBpt 32767 "Faulty" 32766 "NoDataExists" ;
VAL_ 655 EvseDchrg_Pw_Mx 32767 "Faulty" 32766 "NoDataExists" ;
VAL_ 655 EvseDchrg_I_Mx 32767 "Faulty" 32766 "NoDataExists" ;
VAL_ 599 Bpt_D_StatBattTrac 7 "Faulty" 6 "NotUsed_3" 5 "NotUsed_2" 4 "NotUsed_1" 3 "Active" 2 "Ready" 1 "Wait" 0 "NotReady" ;
VAL_ 528 TireInflateMsgTxt_B_Rq 1 "Yes" 0 "No" ;
VAL_ 528 OffRoadMde_D_Stat 7 "NotUsed_5" 6 "NotUsed_4" 5 "NotUsed_3" 4 "NotUsed_2" 3 "NotUsed_1" 2 "Off_Road2" 1 "Off_Road1" 0 "On_Road" ;
VAL_ 955 Tire_Temp_RF_Data 255 "NotSupported" 254 "Invalid" ;
VAL_ 955 Tire_Temp_ORR_Data 255 "NotSupported" 254 "Invalid" ;
VAL_ 955 Tire_Temp_OLR_Data 255 "NotSupported" 254 "Invalid" ;
VAL_ 955 Tire_Temp_LF_Data 255 "NotSupported" 254 "Invalid" ;
VAL_ 955 Tire_Temp_IRR_Data 255 "NotSupported" 254 "Invalid" ;
VAL_ 955 Tire_Temp_ILR_Data 255 "NotSupported" 254 "Invalid" ;
VAL_ 749 ChrgrSysFalt18_D_Stat 3 "NotUsed" 2 "Pass" 1 "Fail" 0 "NotDiagnoseYet" ;
VAL_ 749 ChrgrSysFalt17_D_Stat 3 "NotUsed" 2 "Pass" 1 "Fail" 0 "NotDiagnoseYet" ;
VAL_ 749 ChrgrSysFalt16_D_Stat 3 "NotUsed" 2 "Pass" 1 "Fail" 0 "NotDiagnoseYet" ;
VAL_ 749 ChrgrSysFalt15_D_Stat 3 "NotUsed" 2 "Pass" 1 "Fail" 0 "NotDiagnoseYet" ;
VAL_ 749 ChrgrSysFalt14_D_Stat 3 "NotUsed" 2 "Pass" 1 "Fail" 0 "NotDiagnoseYet" ;
VAL_ 749 ChrgrSysFalt13_D_Stat 3 "NotUsed" 2 "Pass" 1 "Fail" 0 "NotDiagnoseYet" ;
VAL_ 749 ChrgrSysFalt12_D_Stat 3 "NotUsed" 2 "Pass" 1 "Fail" 0 "NotDiagnoseYet" ;
VAL_ 749 ChrgrSysFalt11_D_Stat 3 "NotUsed" 2 "Pass" 1 "Fail" 0 "NotDiagnoseYet" ;
VAL_ 749 ChrgrSysFalt9_D_Stat 3 "NotUsed" 2 "Pass" 1 "Fail" 0 "NotDiagnoseYet" ;
VAL_ 749 ChrgrSysFalt8_D_Stat 3 "NotUsed" 2 "Pass" 1 "Fail" 0 "NotDiagnoseYet" ;
VAL_ 749 ChrgrSysFalt7_D_Stat 3 "NotUsed" 2 "Pass" 1 "Fail" 0 "NotDiagnoseYet" ;
VAL_ 749 ChrgrSysFalt6_D_Stat 3 "NotUsed" 2 "Pass" 1 "Fail" 0 "NotDiagnoseYet" ;
VAL_ 749 ChrgrSysFalt5_D_Stat 3 "NotUsed" 2 "Pass" 1 "Fail" 0 "NotDiagnoseYet" ;
VAL_ 749 ChrgrSysFalt4_D_Stat 3 "NotUsed" 2 "Pass" 1 "Fail" 0 "NotDiagnoseYet" ;
VAL_ 749 ChrgrSysFalt3_D_Stat 3 "NotUsed" 2 "Pass" 1 "Fail" 0 "NotDiagnoseYet" ;
VAL_ 749 ChrgrSysFalt2_D_Stat 3 "NotUsed" 2 "Pass" 1 "Fail" 0 "NotDiagnoseYet" ;
VAL_ 749 ChrgrSysFalt1_D_Stat 3 "NotUsed" 2 "Pass" 1 "Fail" 0 "NotDiagnoseYet" ;
VAL_ 749 ChrgrSysFalt10_D_Stat 3 "NotUsed" 2 "Pass" 1 "Fail" 0 "NotDiagnoseYet" ;
VAL_ 624 PaakAddErase_D_Rq 3 "EraseAll" 2 "Erase" 1 "Add" 0 "Null" ;
VAL_ 580 BattTracVrtOck_B_Rq 1 "Yes" 0 "No" ;
VAL_ 622 FobCtlType_D_Stat 3 "NotUsed" 2 "Valid" 1 "Invalid" 0 "Null" ;
VAL_ 1050 ActvDrvMde_D2_Stat_UB 1 "Fresh_data" 0 "Unchanged_data" ;
VAL_ 1050 ActvDrvMde_D2_Stat 31 "Faulty" 30 "SelDrvMde31" 29 "SelDrvMde30" 28 "SelDrvMde29" 27 "SelDrvMde28" 26 "SelDrvMde27" 25 "SelDrvMde26" 24 "SelDrvMde25" 23 "SelDrvMde24" 22 "SelDrvMde23" 21 "SelDrvMde22" 20 "SelDrvMde21" 19 "SelDrvMde20" 18 "SelDrvMde19" 17 "SelDrvMde18" 16 "SelDrvMde17" 15 "SelDrvMde16" 14 "SelDrvMde15" 13 "SelDrvMde14" 12 "SelDrvMde13" 11 "SelDrvMde12" 10 "SelDrvMde11" 9 "SelDrvMde10" 8 "SelDrvMde09" 7 "SelDrvMde08" 6 "SelDrvMde07" 5 "SelDrvMde06" 4 "SelDrvMde05" 3 "SelDrvMde04" 2 "SelDrvMde03" 1 "SelDrvMde02" 0 "SelDrvMde01" ;
VAL_ 1050 PtWakeupActv4_B_Rq_UB 1 "Fresh_data" 0 "Unchanged_data" ;
VAL_ 1050 PtWakeupActv4_B_Rq 1 "On" 0 "Off" ;
VAL_ 1050 ModemReset_D_Rq_UB 1 "Fresh_data" 0 "Unchanged_data" ;
VAL_ 1050 ModemReset_D_Rq 15 "NotUsed_11" 14 "NotUsed_10" 13 "NotUsed_9" 12 "NotUsed_8" 11 "NotUsed_7" 10 "NotUsed_6" 9 "NotUsed_5" 8 "NotUsed_4" 7 "NotUsed_3" 6 "BrandConnectReset2" 5 "BrandConnectReset1" 4 "CcsReset" 3 "OnlineTrafficReset" 2 "PaakReset" 1 "WifiHotspotReset" 0 "Null" ;
VAL_ 1050 SelDrvMdeAwd_D_Rq_UB 1 "Fresh_data" 0 "Unchanged_data" ;
VAL_ 1050 SelDrvMdeAwd_D_Rq 31 "Faulty" 30 "NotUsed_17" 29 "NotUsed_16" 28 "NotUsed_15" 27 "NotUsed_14" 26 "NotUsed_13" 25 "NotUsed_12" 24 "NotUsed_11" 23 "NotUsed_10" 22 "NotUsed_9" 21 "NotUsed_8" 20 "CustomMode" 19 "OnePedalDrive" 18 "DragMode" 17 "EvLaterChargeMode" 16 "EvNowMode" 15 "TrackMode" 14 "RoughRoadMode" 13 "NotAvailable" 12 "HighSpeedDesertMode_Baja" 11 "SportAdaptiveMode" 10 "RockCrawlMode" 9 "MudRutsMode" 8 "SandMode" 7 "EconomyMode" 6 "GrassGravelSnow" 5 "TowHaulMode" 4 "SportMode" 3 "Normal_4L" 2 "Normal_4A" 1 "Normal_2H" 0 "NormalMode" ;
VAL_ 1050 DrLckCnt_No_ActlTgate_UB 1 "Fresh_data" 0 "Unchanged_data" ;
VAL_ 1050 TelematicsSrvc_D_St_UB 1 "Fresh_data" 0 "Unchanged_data" ;
VAL_ 1050 TelematicsSrvc_D_St 7 "NotUsed" 6 "NotifyNotActivatedYet" 5 "NotActivatedYet" 4 "NotifyExpired" 3 "Expired" 2 "ExpiringSoon" 1 "Active" 0 "Null" ;
VAL_ 1050 FactoryReset_Rq_UB 1 "Fresh_data" 0 "Unchanged_data" ;
VAL_ 1050 FactoryReset_Rq 1 "ResetFactoryDefaults" 0 "Inactive" ;
VAL_ 1050 TurnLampFrOut_B_Stat_UB 1 "Fresh_data" 0 "Unchanged_data" ;
VAL_ 1050 TurnLampFlOut_B_Stat_UB 1 "Fresh_data" 0 "Unchanged_data" ;
VAL_ 1050 TurnLampFrOut_B_Stat 1 "Out" 0 "Null" ;
VAL_ 1050 TurnLampFlOut_B_Stat 1 "Out" 0 "Null" ;
VAL_ 1050 TrunkFrontRolCd_No_Locl_UB 1 "Fresh_data" 0 "Unchanged_data" ;
VAL_ 1050 SelDrvMdeHmi03_D_Rq 31 "Faulty" 30 "SelDrvMde31" 29 "SelDrvMde30" 28 "SelDrvMde29" 27 "SelDrvMde28" 26 "SelDrvMde27" 25 "SelDrvMde26" 24 "SelDrvMde25" 23 "SelDrvMde24" 22 "SelDrvMde23" 21 "SelDrvMde22" 20 "SelDrvMde21" 19 "SelDrvMde20" 18 "SelDrvMde19" 17 "SelDrvMde18" 16 "SelDrvMde17" 15 "SelDrvMde16" 14 "SelDrvMde15" 13 "SelDrvMde14" 12 "SelDrvMde13" 11 "SelDrvMde12" 10 "SelDrvMde11" 9 "SelDrvMde10" 8 "SelDrvMde09" 7 "SelDrvMde08" 6 "SelDrvMde07" 5 "SelDrvMde06" 4 "SelDrvMde05" 3 "SelDrvMde04" 2 "SelDrvMde03" 1 "SelDrvMde02" 0 "SelDrvMde01" ;
VAL_ 1050 SelDrvMdeHmi03_D_Rq_UB 1 "Fresh_data" 0 "Unchanged_data" ;
VAL_ 1217 PrkAidSwtch_D_RqMnu_UB 1 "Fresh_data" 0 "Unchanged_data" ;
VAL_ 1217 PrkAidSwtch_D_RqMnu 1 "Pressed" 0 "Not_Pressed" ;
VAL_ 1217 ApaSwtch_D_RqMnu_UB 1 "Fresh_data" 0 "Unchanged_data" ;
VAL_ 1217 ApaSwtch_D_RqMnu 3 "NotUsed2" 2 "NotUsed1" 1 "Pressed" 0 "Not_Pressed" ;
VAL_ 1217 StopStrtVThres_D_RqMnu_UB 1 "Fresh_data" 0 "Unchanged_data" ;
VAL_ 1217 StopStrtVThres_D_RqMnu 3 "High" 2 "Medium" 1 "Low" 0 "NoSelection" ;
VAL_ 1217 SldrrUnlckSwtch_D_Stat_UB 1 "Fresh_data" 0 "Unchanged_data" ;
VAL_ 1217 SldrrUnlckRollCd_No_Cnt_UB 1 "Fresh_data" 0 "Unchanged_data" ;
VAL_ 1217 SldrrUnlck_No_Cnt_UB 1 "Fresh_data" 0 "Unchanged_data" ;
VAL_ 1217 SldrrChildLck_No_Cnt_UB 1 "Fresh_data" 0 "Unchanged_data" ;
VAL_ 1217 Sldrr_D_Stat_UB 1 "Fresh_data" 0 "Unchanged_data" ;
VAL_ 1217 SldrrUnlckSwtch_D_Stat 3 "InnerHandle" 2 "RearInteriorSwitch" 1 "IpSwitch" 0 "Null" ;
VAL_ 1217 Sldrr_D_Stat 3 "NotCalibrated" 2 "Closing" 1 "Opening" 0 "NotMoving" ;
VAL_ 1216 Sldrl_D_Stat_UB 1 "Fresh_data" 0 "Unchanged_data" ;
VAL_ 1216 Sldrl_D_Stat 3 "NotCalibrated" 2 "Closing" 1 "Opening" 0 "NotMoving" ;
VAL_ 1216 SldrlUnlck_No_Cnt_UB 1 "Fresh_data" 0 "Unchanged_data" ;
VAL_ 1216 SldrlUnlckSwtch_D_Stat_UB 1 "Fresh_data" 0 "Unchanged_data" ;
VAL_ 1216 SldrlUnlckSwtch_D_Stat 3 "InnerHandle" 2 "RearInteriorSwitch" 1 "IpSwitch" 0 "Null" ;
VAL_ 1216 SldrlUnlckRollCd_No_Cnt_UB 1 "Fresh_data" 0 "Unchanged_data" ;
VAL_ 1216 SldrlChildLck_No_Cnt_UB 1 "Fresh_data" 0 "Unchanged_data" ;
VAL_ 1216 OCSSensrDataUpperLim_UB 1 "Fresh_data" 0 "Unchanged_data" ;
VAL_ 1216 OCSSensrDataUpperLim 255 "Invalid" ;
VAL_ 1216 OCSSensrDataLowerLim_UB 1 "Fresh_data" 0 "Unchanged_data" ;
VAL_ 1216 OCSSensrDataLowerLim 255 "Invalid" ;
VAL_ 1087 DcacFaltMsgTxt_D2_Rq 63 "NotUsed_47" 17 "NotUsed_1" 16 "HevDerate" 15 "HvacOn" 14 "OvercurrentLP" 13 "EngineRun" 12 "Service" 11 "NotAvailable" 10 "PlugWarn" 9 "PlugWarnDrive" 8 "BreakerC" 7 "BreakerB" 6 "BreakerA" 5 "FuelLow" 4 "AcOnOutput" 3 "Temperature" 2 "Gfci" 1 "Overcurrent" 0 "Ok" ;
VAL_ 1087 SelDrvMdeCstmPt_D_Stat 31 "Faulty" 30 "NotUsed15" 29 "NotUsed14" 28 "NotUsed13" 27 "NotUsed12" 26 "NotUsed11" 25 "NotUsed10" 24 "NotUsed9" 23 "NotUsed8" 22 "NotUsed7" 21 "CustomMode" 20 "TrackMode" 19 "OnePedalDrive" 18 "EvLaterChargerMode" 17 "EvNowMode" 16 "DragMode" 15 "HighSpeedDesertMode_Baja" 14 "SportAdaptiveMode" 13 "NotAvailable_13" 12 "NotAvailable_12" 11 "NotAvailable_11" 10 "NotAvailable_10" 9 "RockCrawlMode" 8 "MudRutsMode" 7 "SandMode" 6 "EconomyMode" 5 "GrassGravelSnow" 4 "NotAvailable_04" 3 "TowHaulMode" 2 "NotAvailable_02" 1 "SportMode" 0 "NormalMode" ;
VAL_ 1087 RepaLcGrdInhbt_B_Stat 1 "Yes" 0 "No" ;
VAL_ 1087 ClimtCool_D_RqPt 3 "NotUsed_2" 2 "NotUsed_1" 1 "On" 0 "Off" ;
VAL_ 1087 BtsiShifInhbt_B_RqPt 1 "Yes" 0 "No" ;
VAL_ 1087 StrtInGearMsgTxt_D_Rq 15 "Message15" 14 "Message14" 13 "Message13" 12 "Message12" 11 "Message11" 10 "Message10" 9 "Message9" 8 "Message8" 7 "Message7" 6 "Message6" 5 "Message5" 4 "Message4" 3 "Message3" 2 "Message2" 1 "Message1" 0 "NoMessage" ;
VAL_ 1087 IgnOffInhbt_B_Stat 1 "Yes" 0 "No" ;
VAL_ 1087 StopStrtCstm_D_Stat 3 "Faulty" 2 "On" 1 "Off" 0 "NotAvailable" ;
VAL_ 1087 FapLcInhbt_B_Rq 1 "Yes" 0 "No" ;
VAL_ 1087 FapLcStopHold_B_Rq 1 "Yes" 0 "No" ;
VAL_ 1087 FapLcPrchgBrk_B_Rq 1 "Yes" 0 "No" ;
VAL_ 1087 FapLcObstcl_B_Stat 1 "Yes" 0 "No" ;
VAL_ 1087 FapLcMaxGrdInhbt_B_Stat 1 "Yes" 0 "No" ;
VAL_ 1087 FapLcMaxGrdAbrt_B_Stat 1 "Yes" 0 "No" ;
VAL_ 1087 FapLcActv_B_Stat 1 "Yes" 0 "No" ;
VAL_ 1087 BattRgenLoDChrg_D_RqEng 3 "Disable" 2 "Retain" 1 "Closed" 0 "Open" ;
VAL_ 1087 BattRgenLoChrg_D_RqEng 3 "Disable" 2 "Retain" 1 "Closed" 0 "Open" ;
VAL_ 1087 AdasLcObtclAbrt_B_Stat 1 "Yes" 0 "No" ;
VAL_ 1087 AirDamPos_D_Stat 3 "Faulty" 2 "NotUsed" 1 "Down" 0 "Up" ;
VAL_ 562 OnePdlDrv_D_Stat 3 "Enabled_BrkLampAndFbrk" 2 "Enabled_BrkLamp" 1 "Enabled_NoAction" 0 "Disabled" ;
VAL_ 562 GearNtrl_D_Stat 3 "Faulty" 2 "NoDataExists" 1 "Yes" 0 "No" ;
VAL_ 533 ClrExitAsstEnbl_D_RqMnu 3 "NotUsed" 0 "Inactive" 2 "Enable" 1 "Disable" ;
VAL_ 533 PaakMyKey_D_Rq 3 "NotUsed" 2 "ConfirmNewPaakMyKey" 1 "RequestNewPaakMyKey" 0 "None" ;
VAL_ 533 AutoEpbZoomView_B_Stat 1 "Active" 0 "Inactive" ;
VAL_ 533 AutoEpbButtn_B_Stat 1 "Pressed" 0 "Not_Pressed" ;
VAL_ 533 DcacPw_D_Rq 3 "High" 2 "Low" 1 "Off" 0 "Null" ;
VAL_ 533 DcacPwReset_B_Rq 1 "Reset" 0 "Null" ;
VAL_ 533 OtaTrg_D_Stat 3 "NotUsed_1" 2 "Accepted" 1 "NotAccepted" 0 "Null" ;
VAL_ 533 DcacPwLoButtn_B_Stat 1 "Pressed" 0 "Not_Pressed" ;
VAL_ 533 DcacPwOffButtn_B_Stat 1 "Pressed" 0 "Not_Pressed" ;
VAL_ 533 DcacPwHiButtn_B_Stat 1 "Pressed" 0 "Not_Pressed" ;
VAL_ 533 DcacPwResetButtn_B_Stat 1 "Pressed" 0 "Not_Pressed" ;
VAL_ 533 DcacPwButtn_B_Falt 1 "Faulted" 0 "NotFaulted" ;
VAL_ 533 OnbChrgGoTTouch_D_Rq 3 "NotUsed" 2 "On" 1 "Off" 0 "Null" ;
VAL_ 533 OnbChrgGoTPrcond_D_Rq 3 "High" 2 "Medium" 1 "Low" 0 "Off" ;
VAL_ 533 OnbChrgGoTOn_D_Rq 3 "NotUsed" 2 "On" 1 "Off" 0 "Null" ;
VAL_ 533 OnbChrgGoTMnte_D_Rq 15 "NotUsed_4" 14 "NotUsed_3" 13 "NotUsed_2" 12 "NotUsed_1" 11 "Minute_55" 10 "Minute_50" 9 "Minute_45" 8 "Minute_40" 7 "Minute_35" 6 "Minute_30" 5 "Minute_25" 4 "Minute_20" 3 "Minute_15" 2 "Minute_10" 1 "Minute_5" 0 "Minute_0" ;
VAL_ 533 OnbChrgGoTHr_T_Rq 31 "Faulty" 30 "NoDataExists" ;
VAL_ 533 OnbChrgGoTExtHtr_D_Rq 3 "NotUsed" 2 "On" 1 "Off" 0 "Null" ;
VAL_ 533 OnbChrgGoTDelete_B_Rq 1 "Request" 0 "NoRequest" ;
VAL_ 533 OnbChrgClearAll_B_Rq 1 "Request" 0 "NoRequest" ;
VAL_ 533 OnbChrgGoTUpdate_B_Rq 1 "Request" 0 "NoRequest" ;
VAL_ 533 TrlrAidMde_D_Rq 3 "Mode_3" 2 "Mode_2" 1 "Mode_1" 0 "NoRequest" ;
VAL_ 533 TCU_Init_Actvtn_St 3 "NotUsed" 2 "InitialActivateDeny" 1 "InitialActivateAccept" 0 "Invalid" ;
VAL_ 533 TCU_Final_Actvtn_St 3 "NotUsed" 2 "FinalActivateDeny" 1 "FinalActivateAccept" 0 "Invalid" ;
VAL_ 533 TrlrAlarmButtn_B_Stat 1 "On" 0 "Off" ;
VAL_ 533 DcacMdeButtn_B_Stat 1 "Pressed" 0 "Not_Pressed" ;
VAL_ 533 LghtAmbDrvMde_D_Rq 3 "NotUsed" 2 "Automatic" 1 "Manual" 0 "Null" ;
VAL_ 533 DcacGfciTestBttn_B_Stat 1 "Pressed" 0 "Not_Pressed" ;
VAL_ 533 TrlrHitch_D_RqMnu 15 "NotUsed_10" 14 "NotUsed_9" 13 "NotUsed_8" 12 "NotUsed_7" 11 "NotUsed_6" 10 "NotUsed_5" 9 "NotUsed_4" 8 "NotUsed_3" 7 "NotUsed_2" 6 "NotUsed_1" 5 "GoToTraileringDomain" 4 "Confirm" 3 "TurnOnTba" 2 "TurnOnAutohitch" 1 "CancelAutohitch" 0 "NoRequest" ;
VAL_ 533 DcacPwButtn_B_Stat 1 "Pressed" 0 "Not_Pressed" ;
VAL_ 1012 ChrgLocSaved_B_Dsply 1 "Yes" 0 "No" ;
VAL_ 1012 ChrgLocLongPostv_B_Sav 1 "Yes" 0 "No" ;
VAL_ 1012 ChrgLocLattPostv_B_Sav 1 "Yes" 0 "No" ;
VAL_ 1012 AirCondRec_B_RqVehEl 1 "Yes" 0 "No" ;
VAL_ 1012 ChrgNowCurnt_B_Dsply 1 "On" 0 "Off" ;
VAL_ 874 BattTracShrtGrnd_D_Falt 3 "NotUsed" 2 "Pass" 1 "Fail" 0 "Not_Diagnose_Yet" ;
VAL_ 874 BattTracShrtBatt_D_Falt 3 "NotUsed" 2 "Pass" 1 "Fail" 0 "Not_Diagnose_Yet" ;
VAL_ 874 BattTracOpnCirct_D_Falt 3 "NotUsed" 2 "Pass" 1 "Fail" 0 "Not_Diagnose_Yet" ;
VAL_ 874 BattTracLifeLim_D_Falt 3 "NotUsed" 2 "Pass" 1 "Fail" 0 "Not_Diagnose_Yet" ;
VAL_ 874 BattChlrShrtGrnd_D_Falt 3 "NotUsed" 2 "Pass" 1 "Fail" 0 "Not_Diagnose_Yet" ;
VAL_ 874 BattChlrShrtBatt_D_Falt 3 "NotUsed" 2 "Pass" 1 "Fail" 0 "Not_Diagnose_Yet" ;
VAL_ 874 BattChlrOpnCirct_D_Falt 3 "NotUsed" 2 "Pass" 1 "Fail" 0 "Not_Diagnose_Yet" ;
VAL_ 874 BattChlrLifeLim_D_Falt 3 "NotUsed" 2 "Pass" 1 "Fail" 0 "Not_Diagnose_Yet" ;
VAL_ 874 BattTracLow_D_Falt 3 "NotUsed" 2 "Pass" 1 "Fail" 0 "Not_Diagnose_Yet" ;
VAL_ 912 GearPrkMtr_D_Stat 7 "NotUsed_1" 6 "FetLifeLimitReached" 5 "FetOpenCircuit" 4 "FetOutputShortToPower" 3 "FetOutputShortToGround" 2 "FetNotControlled" 1 "OnPowerToLoad" 0 "OffNoPowerToLoad" ;
VAL_ 912 GearPrkLck_D_Stat 7 "NotUsed_1" 6 "FetLifeLimitReached" 5 "FetOpenCircuit" 4 "FetOutputShortToPower" 3 "FetOutputShortToGround" 2 "FetNotControlled" 1 "OnPowerToLoad" 0 "OffNoPowerToLoad" ;
VAL_ 912 CabnEvapSovFront_D_Stat 7 "NotUsed_1" 6 "FetLifeLimitReached" 5 "FetOpenCircuit" 4 "FetOutputShortToPower" 3 "FetOutputShortToGround" 2 "FetNotControlled" 1 "OnPowerToLoad" 0 "OffNoPowerToLoad" ;
VAL_ 912 BattChlrSov_D_Stat 7 "NotUsed_1" 6 "FetLifeLimitReached" 5 "FetOpenCircuit" 4 "FetOutputShortToPower" 3 "FetOutputShortToGround" 2 "FetNotControlled" 1 "OnPowerToLoad" 0 "OffNoPowerToLoad" ;
VAL_ 912 BattTracClntVlv_D_Stat 7 "FetLowSideOpenOrShort" 6 "FetLifeLimitReached" 5 "FetOpenCircuit" 4 "FetOutputShortToPower" 3 "FetOutputShortToGround" 2 "FetNotControlled" 1 "OnPowerToLoad" 0 "OffNoPowerToLoad" ;
VAL_ 931 VehOnSrc_D_Stat 15 "NotUsed_11" 14 "NotUsed_10" 13 "NotUsed_9" 12 "NotUsed_8" 11 "NotUsed_7" 10 "NotUsed_6" 9 "EsclRssd" 8 "AutonomousVehicle" 7 "SecureIdle" 6 "FleetVehicleInhibit" 5 "StolenVehicleInhibit" 4 "OverTheAir" 3 "RemoteParkAssist" 2 "RemoteStart" 1 "Manual" 0 "Off" ;
VAL_ 931 EngStrtActv_B_Stat 1 "Active" 0 "Inactive" ;
VAL_ 931 EngStrt_B_Rq 1 "Request" 0 "NoRequest" ;
VAL_ 931 DrvInCtl_B_Stat 1 "Yes" 0 "No" ;
VAL_ 931 PtWakeReas_D_Stat 15 "NotUsed_9" 14 "NotUsed_8" 13 "NotUsed_7" 12 "NotUsed_6" 11 "NotUsed_5" 10 "NotUsed_4" 9 "NotUsed_3" 8 "NotUsed_2" 7 "NotUsed_1" 6 "ElapsedTime" 5 "ThirdPartyWakeup" 4 "DoorAjar" 3 "EarlyWake" 2 "NonMotiveStart" 1 "MotiveStart" 0 "Null" ;
VAL_ 931 CrnkInhbt_B_Stat 1 "Inhibit" 0 "NoInhibit" ;
VAL_ 931 IgnPreOffActv_B_Stat 1 "Active" 0 "Inactive" ;
VAL_ 563 DrvBhavAudioAlrt_D_Rq 58 "NotUsed_51" 57 "NotUsed_50" 56 "NotUsed_49" 55 "NotUsed_48" 54 "NotUsed_47" 53 "NotUsed_46" 52 "NotUsed_45" 25 "NotUsed_18" 24 "NotUsed_17" 23 "NotUsed_16" 22 "NotUsed_15" 21 "NotUsed_14" 20 "NotUsed_13" 19 "NotUsed_12" 18 "NotUsed_11" 17 "NotUsed_10" 16 "NotUsed_9" 15 "NotUsed_8" 14 "NotUsed_7" 13 "NotUsed_6" 12 "NotUsed_5" 11 "NotUsed_4" 10 "NotUsed_3" 9 "NotUsed_2" 8 "NotUsed_1" 7 "ExcessiveIdleAndUnbuckled" 6 "ExcessiveSpeedAndUnbuckled" 5 "SeatbeltUnbuckled" 4 "HardBrakingBegin" 3 "HardAccelerationBegin" 2 "ExcessiveSpeedBegin" 1 "ExcessiveIdleBegin" 0 "NoMessage" 63 "NotUsed_56" 62 "NotUsed_55" 61 "NotUsed_54" 60 "NotUsed_53" 59 "NotUsed_52" ;
VAL_ 563 NtfyDrvTrgtDist_L2_Rq 8191 "Faulty" 8190 "NoDataExists" ;
VAL_ 563 BattChrgStrtStop_D_Rq 3 "ReturnToSettings" 2 "StopCharge" 1 "StartCharge" 0 "NoNewRequest" ;
VAL_ 563 DrvBhavWarn_B_Rq 1 "On" 0 "Off" ;
VAL_ 563 OfbChrgSetSync_D_Rq 3 "Fail" 2 "Success" 1 "InProgress" 0 "NoSyncInProgress" ;
VAL_ 563 KeyOffPwMde_D_Stat 7 "NotUsed_6" 6 "NotUsed_5" 5 "NotUsed_4" 4 "NotUsed_3" 0 "Inactive" 1 "On" 2 "NotUsed_1" 3 "NotUsed_2" ;
VAL_ 563 ModemReset_D_Stat 15 "NotUsed_10" 14 "NotUsed_9" 13 "NotUsed_8" 12 "NotUsed_7" 11 "NotUsed_6" 10 "NotUsed_5" 9 "NotUsed_4" 8 "NotUsed_3" 7 "NotUsed_2" 6 "NotUsed_1" 5 "WifiHotSpotResetComplete" 4 "CcsResetComplete" 3 "OnlineTrafficResetComplete" 2 "PaakResetComplete" 1 "ResetNotComplete" 0 "Null" ;
VAL_ 563 FactoryReset_St 3 "NotUsed_2" 2 "NotUsed_1" 1 "FactoryDefaultsRestored" 0 "Null" ;
VAL_ 621 IgnPsswrdActv_B_Stat 1 "Active" 0 "Inactive" ;
VAL_ 621 FobTrgtZone_D_Rq 15 "NotUsed_9" 14 "NotUsed_8" 13 "NotUsed_7" 12 "NotUsed_6" 11 "NotUsed_5" 10 "NotUsed_4" 9 "NotUsed_3" 8 "NotUsed_2" 7 "NotUsed_1" 6 "Approach" 5 "RearInterior" 4 "RearExterior" 3 "Passenger" 2 "Driver" 1 "Interior" 0 "Null" ;
VAL_ 621 FobTrgtType_D_Rq 7 "NotUsed_4" 6 "NotUsed_3" 5 "NotUsed_2" 4 "NotUsed_1" 3 "Polling" 2 "Registry" 1 "Crypto" 0 "Null" ;
VAL_ 621 RmtCtlSelSlot_D_Rq 7 "NotUsed_3" 6 "NotUsed_2" 5 "NotUsed_1" 4 "Right" 3 "Left" 2 "Rear" 1 "Front" 0 "None" ;
VAL_ 621 RmtCtlSelPrkMde_D_Rq 3 "NotUsed" 2 "FreeDrive" 1 "ParkIn" 0 "None" ;
VAL_ 621 RmtCtlSelMoveDir_D_Rq 3 "NotUsed" 2 "Backward" 1 "Forward" 0 "None" ;
VAL_ 621 RmtCtlRjctAutoCfg_B_Rq 1 "Yes" 0 "No" ;
VAL_ 1149 BattTracPerf_Pc_Dsply 255 "Faulty" 254 "NoDataExists" ;
VAL_ 1149 BattTracPerf_Pc_Actl 255 "Faulty" 254 "NoDataExists" ;
VAL_ 626 PaakCtlIndx8_D_Stat 15 "NotUsed_9" 14 "NotUsed_8" 13 "NotUsed_7" 12 "NotUsed_6" 11 "NotUsed_5" 10 "NotUsed_4" 9 "NotUsed_3" 8 "NotUsed_2" 7 "NotUsed_1" 6 "Approach" 5 "RearInterior" 4 "RearExterior" 3 "Passenger" 2 "Driver" 1 "Interior" 0 "Null" ;
VAL_ 626 PaakCtlIndx7_D_Stat 15 "NotUsed_9" 14 "NotUsed_8" 13 "NotUsed_7" 12 "NotUsed_6" 11 "NotUsed_5" 10 "NotUsed_4" 9 "NotUsed_3" 8 "NotUsed_2" 7 "NotUsed_1" 6 "Approach" 5 "RearInterior" 4 "RearExterior" 3 "Passenger" 2 "Driver" 1 "Interior" 0 "Null" ;
VAL_ 626 PaakCtlIndx6_D_Stat 15 "NotUsed_9" 14 "NotUsed_8" 13 "NotUsed_7" 12 "NotUsed_6" 11 "NotUsed_5" 10 "NotUsed_4" 9 "NotUsed_3" 8 "NotUsed_2" 7 "NotUsed_1" 6 "Approach" 5 "RearInterior" 4 "RearExterior" 3 "Passenger" 2 "Driver" 1 "Interior" 0 "Null" ;
VAL_ 626 PaakCtlIndx5_D_Stat 15 "NotUsed_9" 14 "NotUsed_8" 13 "NotUsed_7" 12 "NotUsed_6" 11 "NotUsed_5" 10 "NotUsed_4" 9 "NotUsed_3" 8 "NotUsed_2" 7 "NotUsed_1" 6 "Approach" 5 "RearInterior" 4 "RearExterior" 3 "Passenger" 2 "Driver" 1 "Interior" 0 "Null" ;
VAL_ 626 PaakCtlIndx4_D_Stat 15 "NotUsed_9" 14 "NotUsed_8" 13 "NotUsed_7" 12 "NotUsed_6" 11 "NotUsed_5" 10 "NotUsed_4" 9 "NotUsed_3" 8 "NotUsed_2" 7 "NotUsed_1" 6 "Approach" 5 "RearInterior" 4 "RearExterior" 3 "Passenger" 2 "Driver" 1 "Interior" 0 "Null" ;
VAL_ 626 PaakCtlIndx3_D_Stat 15 "NotUsed_9" 14 "NotUsed_8" 13 "NotUsed_7" 12 "NotUsed_6" 11 "NotUsed_5" 10 "NotUsed_4" 9 "NotUsed_3" 8 "NotUsed_2" 7 "NotUsed_1" 6 "Approach" 5 "RearInterior" 4 "RearExterior" 3 "Passenger" 2 "Driver" 1 "Interior" 0 "Null" ;
VAL_ 626 PaakCtlIndx2_D_Stat 15 "NotUsed_9" 14 "NotUsed_8" 13 "NotUsed_7" 12 "NotUsed_6" 11 "NotUsed_5" 10 "NotUsed_4" 9 "NotUsed_3" 8 "NotUsed_2" 7 "NotUsed_1" 6 "Approach" 5 "RearInterior" 4 "RearExterior" 3 "Passenger" 2 "Driver" 1 "Interior" 0 "Null" ;
VAL_ 626 PaakCtlIndx1_D_Stat 15 "NotUsed_9" 14 "NotUsed_8" 13 "NotUsed_7" 12 "NotUsed_6" 11 "NotUsed_5" 10 "NotUsed_4" 9 "NotUsed_3" 8 "NotUsed_2" 7 "NotUsed_1" 6 "Approach" 5 "RearInterior" 4 "RearExterior" 3 "Passenger" 2 "Driver" 1 "Interior" 0 "Null" ;
VAL_ 1161 DrSwtchInnrRr_No_Rq_UB 1 "Fresh_data" 0 "Unchanged_data" ;
VAL_ 1161 DrSwtchInnrRl_No_Rq_UB 1 "Fresh_data" 0 "Unchanged_data" ;
VAL_ 1161 DrLatchRolCdRr_No_Locl_UB 1 "Fresh_data" 0 "Unchanged_data" ;
VAL_ 1161 DrLatchRolCdRl_No_Locl_UB 1 "Fresh_data" 0 "Unchanged_data" ;
VAL_ 1159 WakeAlarm2_B_Typ_UB 1 "Fresh_data" 0 "Unchanged_data" ;
VAL_ 1159 WakeAlarm2_T_Rq_UB 1 "Fresh_data" 0 "Unchanged_data" ;
VAL_ 1159 WakeAlarm2_B_Typ 1 "CanAndEcuDriveCircuit" 0 "CanOnly" ;
VAL_ 1159 DrLatchRolCdFr_No_Locl_UB 1 "Fresh_data" 0 "Unchanged_data" ;
VAL_ 1159 DrLatchRolCdFl_No_Locl_UB 1 "Fresh_data" 0 "Unchanged_data" ;
VAL_ 1159 DrSwtchInnrFr_No_Rq_UB 1 "Fresh_data" 0 "Unchanged_data" ;
VAL_ 1159 DrSwtchInnrFl_No_Rq_UB 1 "Fresh_data" 0 "Unchanged_data" ;
VAL_ 72 immoTarget2Status 7 "Unused4" 6 "Unused3" 5 "Unused2" 4 "ENABLED_LIMITEDMOTIVE_STAR" 3 "DISABLED_RESET   " 2 "ENABLED_NONMOTIVE_START" 1 "ENABLED_MOTIVE_START" 0 "DISABLED" ;
VAL_ 72 immoTarget2Cmd 7 "Unused4" 6 "Unused3" 5 "Unused2" 4 "Unused1" 3 "TARGET1_IDBLOCK2" 2 "TARGET1_IDBLOCK1" 1 "CHALLENGE" 0 "IDLE" ;
VAL_ 1130 PaakCtlType_D_Stat 3 "NotUsed" 2 "Valid" 1 "Invalid" 0 "Null" ;
VAL_ 1130 PaakCtlData_D_Stat 7 "NotUsed_3" 6 "NotUsed_2" 5 "NotUsed_1" 4 "Response" 3 "EchoTargetIdBlock1" 2 "RequestTargetIdBlock2" 1 "RequestTargetIdBlock1" 0 "Idle" ;
VAL_ 1130 IgnPsswrdLckout_B_Stat 1 "Active" 0 "Inactive" ;
VAL_ 1130 IgnPsswrdSetup_B_Rq 1 "Active" 0 "Inactive" ;
VAL_ 1130 PaakLoclzd_D_Stat 15 "NotUsed_12" 14 "NotUsed_11" 13 "NotUsed_10" 12 "NotUsed_9" 11 "NotUsed_8" 10 "NotUsed_7" 9 "NotUsed_6" 8 "NotUsed_5" 7 "NotUsed_4" 6 "NotUsed_3" 5 "NotUsed_2" 4 "NotUsed_1" 3 "FullLoc" 2 "PausedLoc" 1 "MaintainLink" 0 "BackgroundScan" ;
VAL_ 1129 PaaKMyKeyChng_D_Stat 3 "NotUsed" 2 "ClearAll" 1 "MyKey" 0 "Null" ;
VAL_ 1129 PaakAddErase_D_Stat 3 "EraseAll" 2 "Erase" 1 "Add" 0 "Null" ;
VAL_ 1131 KeyPadCodeProg_D_Rq 7 "NotUsed_3" 6 "NotUsed_2" 5 "NotUsed_1" 4 "DeleteAll" 3 "Delete" 2 "Add" 1 "ProgrammingMode" 0 "Null" ;
VAL_ 1131 PaakCnnct_D_Stat 3 "NotUsed" 2 "Connected" 1 "NotConnected" 0 "Null" ;
VAL_ 1131 PaakCtlActv_D_Rq 31 "NotUsed_13" 30 "NotUsed_12" 29 "NotUsed_11" 28 "NotUsed_10" 27 "NotUsed_9" 26 "NotUsed_8" 25 "NotUsed_7" 24 "NotUsed_6" 23 "NotUsed_5" 22 "NotUsed_4" 21 "NotUsed_3" 20 "TrunkFrontRelease" 19 "RemoteStop" 18 "RemoteStart" 17 "PowerDecklid" 16 "RightPowerSlidingDoor" 15 "LeftPowerSlidingDoor" 14 "PowerLiftgate" 13 "GlobalClose" 12 "GlobalOpen" 11 "PanicOff" 10 "PanicOn" 9 "LiftgateGlassRelease" 8 "LiftgateRelease" 7 "DecklidRelease" 6 "DoubleLock" 5 "LockAll" 4 "UnlockAllDoorsPlusCargo" 3 "UnlockCargoDoor" 2 "UnlockAllDoors" 1 "UnlockDriverDoor" 0 "Null" ;
VAL_ 1128 KeyPadCodeProg_D_Stat 7 "NotUsed_2" 6 "Duplicate" 5 "ProgrammingFailure" 4 "DeleteAll" 3 "Delete" 2 "Add" 1 "LearningMode" 0 "NormalMode" ;
VAL_ 1128 PaakTrgtType_D_Rq 7 "NotUsed_4" 6 "NotUsed_3" 5 "NotUsed_2" 4 "NotUsed_1" 3 "Polling" 2 "Registry" 1 "Crypto" 0 "Null" ;
VAL_ 1128 PaakTrgtZone_D_Rq 15 "NotUsed_9" 14 "NotUsed_8" 13 "NotUsed_7" 12 "NotUsed_6" 11 "NotUsed_5" 10 "NotUsed_4" 9 "NotUsed_3" 8 "NotUsed_2" 7 "NotUsed_1" 6 "Approach" 5 "RearInterior" 4 "RearExterior" 3 "Passenger" 2 "Driver" 1 "Interior" 0 "Null" ;
VAL_ 1128 PaakTrgtData_D_Rq 5 "NotUsed_2" 4 "Not_Used1" 3 "Target1_IdBlock2" 2 "Target1_IdBlock1" 1 "Challenge" 0 "Idle" 7 "NotUsed_4" 6 "NotUsed_3" ;
VAL_ 1128 PaakTrgtPreAuthrz_B_Rq 1 "Enable" 0 "Disable" ;
VAL_ 123 BattTrac_U2_Actl 4095 "Faulty" 4094 "NoDataExists" ;
VAL_ 123 BattTrac_I2_Actl 262143 "Faulty" 262142 "NoDataExists" ;
VAL_ 816 KeyPadCodeDgt7_D_Stat 15 "NotUsed_4" 14 "NotUsed_3" 13 "NotUsed_2" 12 "NotUsed_1" 11 "Button7_8and9_0" 10 "Button0" 9 "Button9_0or9" 8 "Button8" 7 "Button7_8or7" 6 "Button6" 5 "Button5_6or5" 4 "Button4" 3 "Button3_4or3" 2 "Button2" 1 "Button1_2or1" 0 "EndofString" ;
VAL_ 816 KeyPadCodeDgt6_D_Stat 15 "NotUsed_4" 14 "NotUsed_3" 13 "NotUsed_2" 12 "NotUsed_1" 11 "Button7_8and9_0" 10 "Button0" 9 "Button9_0or9" 8 "Button8" 7 "Button7_8or7" 6 "Button6" 5 "Button5_6or5" 4 "Button4" 3 "Button3_4or3" 2 "Button2" 1 "Button1_2or1" 0 "EndofString" ;
VAL_ 816 KeyPadCodeDgt5_D_Stat 15 "NotUsed_4" 14 "NotUsed_3" 13 "NotUsed_2" 12 "NotUsed_1" 11 "Button7_8and9_0" 10 "Button0" 9 "Button9_0or9" 8 "Button8" 7 "Button7_8or7" 6 "Button6" 5 "Button5_6or5" 4 "Button4" 3 "Button3_4or3" 2 "Button2" 1 "Button1_2or1" 0 "EndofString" ;
VAL_ 816 KeyPadCodeDgt4_D_Stat 15 "NotUsed_4" 14 "NotUsed_3" 13 "NotUsed_2" 12 "NotUsed_1" 11 "Button7_8and9_0" 10 "Button0" 9 "Button9_0or9" 8 "Button8" 7 "Button7_8or7" 6 "Button6" 5 "Button5_6or5" 4 "Button4" 3 "Button3_4or3" 2 "Button2" 1 "Button1_2or1" 0 "EndofString" ;
VAL_ 816 KeyPadCodeDgt3_D_Stat 15 "NotUsed_4" 14 "NotUsed_3" 13 "NotUsed_2" 12 "NotUsed_1" 11 "Button7_8and9_0" 10 "Button0" 9 "Button9_0or9" 8 "Button8" 7 "Button7_8or7" 6 "Button6" 5 "Button5_6or5" 4 "Button4" 3 "Button3_4or3" 2 "Button2" 1 "Button1_2or1" 0 "EndofString" ;
VAL_ 816 KeyPadCodeDgt2_D_Stat 15 "NotUsed_4" 14 "NotUsed_3" 13 "NotUsed_2" 12 "NotUsed_1" 11 "Button7_8and9_0" 10 "Button0" 9 "Button9_0or9" 8 "Button8" 7 "Button7_8or7" 6 "Button6" 5 "Button5_6or5" 4 "Button4" 3 "Button3_4or3" 2 "Button2" 1 "Button1_2or1" 0 "EndofString" ;
VAL_ 816 KeyPadCodeDgt1_D_Stat 15 "NotUsed_4" 14 "NotUsed_3" 13 "NotUsed_2" 12 "NotUsed_1" 11 "Button7_8and9_0" 10 "Button0" 9 "Button9_0or9" 8 "Button8" 7 "Button7_8or7" 6 "Button6" 5 "Button5_6or5" 4 "Button4" 3 "Button3_4or3" 2 "Button2" 1 "Button1_2or1" 0 "EndofString" ;
VAL_ 816 CntrStk2_D_RqAssoc 7 "Unused_2" 6 "Cancel" 5 "Set_Keycode" 4 "RKE" 3 "Null" 2 "Key" 1 "Erase_KeyCode" 0 "Check_KeyCode" ;
VAL_ 816 KeylessIdl_D_Rq 3 "Cancel" 2 "IgnitionOff" 1 "Active" 0 "Inactive" ;
VAL_ 966 TrnkFrontInhbt_B_Stat 1 "Inhibit" 0 "NoInhibit" ;
VAL_ 966 TrnkFrontRleas_D_Src 7 "NotUsed_3" 6 "NotUsed_2" 5 "NotUsed_1" 4 "Cpp" 3 "Sync" 2 "Keypad" 1 "Remote" 0 "Null" ;
VAL_ 943 InhbtGlblClkAdj_B_Rq 1 "Request" 0 "NoRequest" ;
VAL_ 932 RmtCtlBattMntr_B_Falt 1 "Yes" 0 "No" ;
VAL_ 932 VehInhbtMde_D_Stat 7 "NotUsed_3" 6 "NotUsed_2" 5 "NotUsed_1" 4 "FullVehicleOta" 3 "Iviota" 2 "SyncOta" 1 "NoOtaSupport" 0 "Unconfigured" ;
VAL_ 932 VehStrtInhbt_D_Stat 1 "Inhibit" 0 "NoInhibit" ;
VAL_ 932 VehOnCtl_D_Stat 3 "NotUsed" 2 "On" 1 "Off" 0 "Null" ;
VAL_ 932 VehOnSrc2_D_Stat 15 "NotUsed_11" 14 "NotUsed_10" 13 "NotUsed_9" 12 "NotUsed_8" 11 "NotUsed_7" 10 "NotUsed_6" 9 "EsclRssd" 8 "AutonomousVehicle" 7 "SecureIdle" 6 "FleetVehicleInhibit" 5 "StolenVehicleInhibit" 4 "OverTheAir" 3 "RemoteParkAssist" 2 "RemoteStart" 1 "Manual" 0 "Off" ;
VAL_ 885 BattULoChrg_D_RqOta 1 "Yes" 0 "No" ;
VAL_ 885 VehStrtInhbt_D_Dsply 15 "NotUsed_12" 14 "NotUsed_11" 13 "NotUsed_10" 12 "NotUsed_9" 11 "NotUsed_8" 10 "NotUsed_7" 9 "NotUsed_6" 8 "NotUsed_5" 7 "NotUsed_4" 6 "FleetPhoneNumber" 5 "FleetGeneral" 4 "OtaSuccess" 3 "PostOtaActivatePermFail" 2 "PostOtaActivateWarning" 1 "DuringOtaActivate" 0 "NoMessage" ;
VAL_ 885 VehOnRqstr_D_Stat 11 "NotUsed_8" 10 "NotUsed_7" 9 "NotUsed_6" 8 "NotUsed_5" 7 "NotUsed_4" 6 "NotUsed_3" 5 "NotUsed_2" 4 "NotUsed_1" 3 "FleetVehInhbt" 2 "StolenVehInhbt" 1 "OverTheAir" 0 "NoRequestor" 15 "NotUsed_12" 14 "NotUsed_11" 13 "NotUsed_10" 12 "NotUsed_9" ;
VAL_ 885 VehStrtInhbt_D_RqCld 3 "NotUsed" 2 "On" 1 "Off" 0 "Null" ;
VAL_ 885 VehOn_D_RqCld 3 "NoControl" 2 "On" 1 "Off" 0 "Null" ;
VAL_ 885 OtaActv_D_Stat 15 "NotUsed_10" 14 "NotUsed_9" 13 "NotUsed_8" 12 "NotUsed_7" 11 "NotUsed_6" 10 "NotUsed_5" 9 "NotUsed_4" 8 "NotUsed_3" 7 "NotUsed_2" 6 "NotUsed_1" 5 "NonInterruptible_Pending" 4 "NonInterruptible_Config" 3 "NonInterruptible_ER" 2 "NonInterruptible_AB" 1 "Interruptible_AB" 0 "NoInVehicleOta" ;
VAL_ 1160 ReFuelSwtchStat_D_Actl2 3 "NotUsed_2" 2 "NotUsed_1" 1 "On" 0 "Off" ;
VAL_ 1160 DgtlCommPncReset_B_Req 1 "Yes" 0 "No" ;
VAL_ 1160 DgtlCommPnc_D_Rq 3 "DeleteAll" 2 "Disable" 1 "Reset" 0 "NoRequest" ;
VAL_ 1160 PwSustnRdata_B_RqTelem 1 "Active" 0 "Inactive" ;
VAL_ 1160 DataMntrSustn_B_Rq 1 "Active" 0 "Inactive" ;
VAL_ 895 TurnLght_D_RqRmtCtl 3 "NotUsed" 2 "Right" 1 "Left" 0 "Null" ;
VAL_ 895 RmtCtlRngSet_D_Rq 3 "NotUsed" 2 "RangeSetB" 1 "RangeSetA" 0 "None" ;
VAL_ 895 RmtCtlKeyPoll_D_Rq 3 "NotUsed" 2 "Polling" 1 "NoPolling" 0 "Null" ;
VAL_ 895 RmtCtlCntnsIn_B_Stat 1 "Available" 0 "NotAvailable" ;
VAL_ 895 RmtCtl_D_Stat 15 "Faulty" 14 "NotUsed_5" 13 "NotUsed_4" 12 "NotUsed_3" 11 "NotUsed_2" 10 "NotUsed_1" 9 "Shutdown" 8 "ManeuverFinished" 7 "ReadyForResume" 6 "Pause" 5 "Maneuvering" 4 "ReadyForManeuvering" 3 "Activation" 2 "Initialize" 1 "Preparation" 0 "Disabled" ;
VAL_ 515 PtIgnSwtch_D_Stat 3 "Faulty" 2 "No_Data_Exists" 1 "On" 0 "Off" ;
VAL_ 1119 CoolFanDcdc_D_Rq 3 "High" 2 "Medium" 1 "Low" 0 "Off" ;
VAL_ 1119 DcdcClntFlw_D_Rq 3 "High" 2 "Medium" 1 "Low" 0 "Off" ;
VAL_ 1110 RstrnMdulePw_D_Falt 3 "NotUsed_1" 2 "NoFault" 1 "Fault" 0 "Null" ;
VAL_ 1036 PdstrnAlrt_B_Falt 1 "Yes" 0 "No" ;
VAL_ 1152 PwOutlet8EnblScnd_B_Rq 1 "Enable" 0 "Disable" ;
VAL_ 1152 PwOutlet8Enbl_B_Rq 1 "Enable" 0 "Disable" ;
VAL_ 1152 PwOutlet7EnblScnd_B_Rq 1 "Enable" 0 "Disable" ;
VAL_ 1152 PwOutlet7Enbl_B_Rq 1 "Enable" 0 "Disable" ;
VAL_ 1152 PwOutlet6EnblScnd_B_Rq 1 "Enable" 0 "Disable" ;
VAL_ 1152 PwOutlet6Enbl_B_Rq 1 "Enable" 0 "Disable" ;
VAL_ 1152 PwCabinEnblScnd_B_Rq 1 "Enable" 0 "Disable" ;
VAL_ 1152 PwCabinEnbl_B_Rq 1 "Enable" 0 "Disable" ;
VAL_ 1152 PwTrnkFrntEnblScnd_B_Rq 1 "Enable" 0 "Disable" ;
VAL_ 1152 PwTrnkFrntEnbl_B_Rq 1 "Enable" 0 "Disable" ;
VAL_ 1152 OnePdlDrvLamp_B_Rq 1 "On" 0 "Off" ;
VAL_ 1152 OnePdlDrv_D_Dsply 3 "Faulty" 2 "Suspended" 1 "On" 0 "Off" ;
VAL_ 1152 HybPwULoLamp_B_Rq 1 "On" 0 "Off" ;
VAL_ 1152 GrdAsstActv_B_Stat 1 "On" 0 "Off" ;
VAL_ 1152 StopStrtVThres_D_Stat 3 "High" 2 "Medium" 1 "Low" 0 "NoSelection" ;
VAL_ 1152 VehElEff_No_Avg 127 "Faulty" 126 "NoDataExists" ;
VAL_ 1152 EngTeHi_B_Actl 1 "EngineTempHigh" 0 "Normal" ;
VAL_ 1152 DcdcOn_B_Rq 1 "On" 0 "Off" ;
VAL_ 1152 BattTracDiagClr_B_Stat 1 "On" 0 "Off" ;
VAL_ 1152 ULoBattSpprtSustn_B_Rq 1 "Active" 0 "Inactive" ;
VAL_ 126 StePw_B_Rq 1 "Yes" 0 "No" ;
VAL_ 126 StePinRelInit_An_Sns 65535 "Faulty" 65534 "NoDataExists" ;
VAL_ 126 StePinCompAnEst_D_Qf 3 "OK" 2 "Degraded" 1 "No_Data_Exists" 0 "Faulty" ;
VAL_ 118 BrkTerrMdeChng_D_Rdy 7 "Fault" 6 "Undefined_2" 5 "Undefined_1" 4 "ModeUnavailDrInputRqd" 3 "SpOpModes_NotSupported" 2 "ModeUnavailDynamicCond" 1 "Module_In_Initialization" 0 "Mode_Change_Available" ;
VAL_ 118 BrkTerrMde_D_Actl 7 "Fail_Safe_Default" 6 "Dynamic_Mode" 5 "Rock_Crawl_Mode" 4 "Mud_Ruts_Mode" 3 "Sand_Mode" 2 "Undefined" 1 "Low_Mu_Mode" 0 "Special_Operating_Mode_Off" ;
VAL_ 118 BrkCtrFnd_B_Stat 1 "Yes" 0 "No" ;
VAL_ 118 SteWhlCompAnEst_D_Qf 3 "OK" 2 "Not_Within_Specifications" 1 "No_Data_Exists" 0 "Faulty" ;
VAL_ 118 DrvSte_D_Stat 15 "NotUsed10" 14 "NotUsed9" 13 "NotUsed8" 12 "NotUsed7" 11 "NotUsed6" 10 "NotUsed5" 9 "NotUsed4" 8 "NotUsed3" 7 "NotUsed2" 6 "NotUsed1" 5 "Request_Active" 4 "Ignition_Off" 3 "DSR_in_Normal_Idle_Mode" 2 "EPAS_Comm_Disturbed" 1 "DSR_Request_Not_Applicable" 0 "DSR_Deactivated" ;
VAL_ 118 DrvSte_Tq_Rq 255 "Invalid" 254 "Unknown" ;
VAL_ 118 EmgcyBrkLamp_D_Rq 3 "NotUsed" 2 "Active_at_standstill" 1 "Active_at_speed" 0 "Inactive" ;
VAL_ 118 StopLamp_B_RqBrk 1 "Active" 0 "Inactive" ;
SIG_GROUP_ 932 Profile1A_SigGroup_HS1_3A4 1 : VehOnSrc2_D_Stat VehOnCtl_D_Stat VehStrtInhbt_D_Stat CanMsg3A4_No_Cnt VehInhbtMde_D_Stat CanMsg3A4_No_Crc RmtCtlBattMntr_B_Falt;
SIG_GROUP_ 885 Profile1A_SigGroup_HS1_375 1 : BattULoChrg_D_RqOta VehStrtInhbt_T_Dsply VehStrtInhbt_D_Dsply OtaActv_D_Stat VehOn_D_RqCld VehOnRqstr_D_Stat VehStrtInhbt_D_RqCld CanMsg375_No_Cnt CanMsg375_No_Crc;
